VERSION ""

NS_ :

BS_:

BU_: Engine2 Aftertreatment_1_GasOutlet BrakesSystemController Transmission1 Engine1

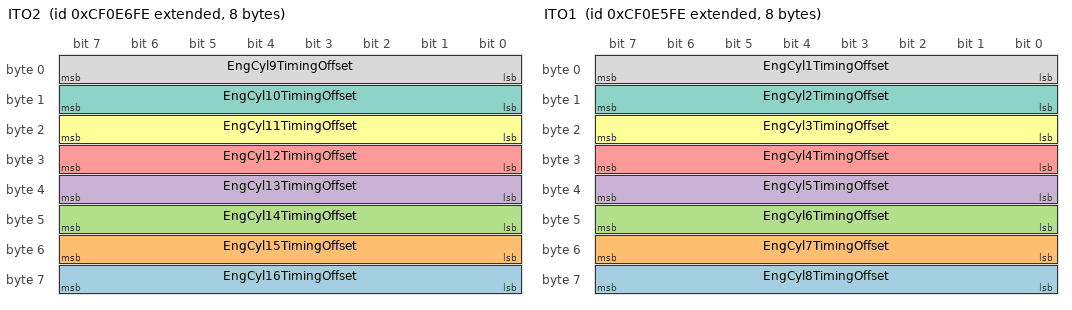
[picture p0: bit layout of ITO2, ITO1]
BO_ 2364598014 ITO2: 8 Vector__XXX
 SG_ EngCyl16TimingOffset : 56|8@1+ (0.1,-12.5) [-12.5|12.5] "deg" Vector__XXX
 SG_ EngCyl15TimingOffset : 48|8@1+ (0.1,-12.5) [-12.5|12.5] "deg" Vector__XXX
 SG_ EngCyl14TimingOffset : 40|8@1+ (0.1,-12.5) [-12.5|12.5] "deg" Vector__XXX
 SG_ EngCyl13TimingOffset : 32|8@1+ (0.1,-12.5) [-12.5|12.5] "deg" Vector__XXX
 SG_ EngCyl12TimingOffset : 24|8@1+ (0.1,-12.5) [-12.5|12.5] "deg" Vector__XXX
 SG_ EngCyl11TimingOffset : 16|8@1+ (0.1,-12.5) [-12.5|12.5] "deg" Vector__XXX
 SG_ EngCyl10TimingOffset : 8|8@1+ (0.1,-12.5) [-12.5|12.5] "deg" Vector__XXX
 SG_ EngCyl9TimingOffset : 0|8@1+ (0.1,-12.5) [-12.5|12.5] "deg" Vector__XXX

BO_ 2364597758 ITO1: 8 Vector__XXX
 SG_ EngCyl8TimingOffset : 56|8@1+ (0.1,-12.5) [-12.5|12.5] "deg" Vector__XXX
 SG_ EngCyl7TimingOffset : 48|8@1+ (0.1,-12.5) [-12.5|12.5] "deg" Vector__XXX
 SG_ EngCyl6TimingOffset : 40|8@1+ (0.1,-12.5) [-12.5|12.5] "deg" Vector__XXX
 SG_ EngCyl5TimingOffset : 32|8@1+ (0.1,-12.5) [-12.5|12.5] "deg" Vector__XXX
 SG_ EngCyl4TimingOffset : 24|8@1+ (0.1,-12.5) [-12.5|12.5] "deg" Vector__XXX
 SG_ EngCyl3TimingOffset : 16|8@1+ (0.1,-12.5) [-12.5|12.5] "deg" Vector__XXX
 SG_ EngCyl2TimingOffset : 8|8@1+ (0.1,-12.5) [-12.5|12.5] "deg" Vector__XXX
 SG_ EngCyl1TimingOffset : 0|8@1+ (0.1,-12.5) [-12.5|12.5] "deg" Vector__XXX

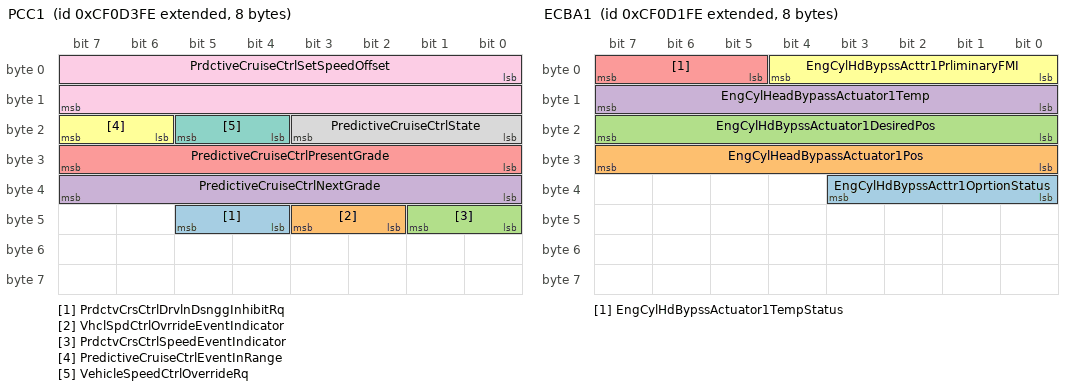
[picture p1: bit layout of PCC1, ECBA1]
BO_ 2364593150 PCC1: 8 Vector__XXX
 SG_ PrdctvCrsCtrlDrvlnDsnggInhibitRq : 44|2@1+ (1,0) [0|3] "" Vector__XXX
 SG_ VhclSpdCtrlOvrrideEventIndicator : 42|2@1+ (1,0) [0|3] "" Vector__XXX
 SG_ PrdctvCrsCtrlSpeedEventIndicator : 40|2@1+ (1,0) [0|3] "" Vector__XXX
 SG_ PredictiveCruiseCtrlNextGrade : 32|8@1+ (0.125,-16) [-16|15.25] "%" Vector__XXX
 SG_ PredictiveCruiseCtrlPresentGrade : 24|8@1+ (0.125,-16) [-16|15.25] "%" Vector__XXX
 SG_ PredictiveCruiseCtrlEventInRange : 22|2@1+ (1,0) [0|3] "" Vector__XXX
 SG_ VehicleSpeedCtrlOverrideRq : 20|2@1+ (1,0) [0|3] "" Vector__XXX
 SG_ PredictiveCruiseCtrlState : 16|4@1+ (1,0) [0|15] "" Vector__XXX
 SG_ PrdctiveCruiseCtrlSetSpeedOffset : 0|16@1+ (0.00390625,-125) [-125|125.996] "km/h" Vector__XXX

BO_ 2364592894 EEC18: 8 Vector__XXX
 SG_ EngCylHeadBypassActuator1Cmd : 0|16@1+ (0.0025,0) [0|160.6375] "%" Vector__XXX

BO_ 2364592638 ECBA1: 8 Vector__XXX
 SG_ EngCylHdBypssActtr1OprtionStatus : 32|4@1+ (1,0) [0|15] "" Vector__XXX
 SG_ EngCylHeadBypassActuator1Pos : 24|8@1+ (0.4,0) [0|100] "%" Vector__XXX
 SG_ EngCylHdBypssActuator1DesiredPos : 16|8@1+ (0.4,0) [0|100] "%" Vector__XXX
 SG_ EngCylHeadBypassActuator1Temp : 8|8@1+ (1,-40) [-40|210] "°C" Vector__XXX
 SG_ EngCylHdBypssActuator1TempStatus : 5|3@1+ (1,0) [0|7] "" Vector__XXX
 SG_ EngCylHdBypssActtr1PrliminaryFMI : 0|5@1+ (1,0) [0|31] "" Vector__XXX

BO_ 2364592382 ECCR: 8 Vector__XXX
 SG_ EngCyl24ExcludeFromCombustionRq : 54|2@1+ (1,0) [0|3] "" Vector__XXX
 SG_ EngCyl23ExcludeFromCombustionRq : 52|2@1+ (1,0) [0|3] "" Vector__XXX
 SG_ EngCyl22ExcludeFromCombustionRq : 50|2@1+ (1,0) [0|3] "" Vector__XXX
 SG_ EngCyl21ExcludeFromCombustionRq : 48|2@1+ (1,0) [0|3] "" Vector__XXX
 SG_ EngCyl20ExcludeFromCombustionRq : 46|2@1+ (1,0) [0|3] "" Vector__XXX
 SG_ EngCyl19ExcludeFromCombustionRq : 44|2@1+ (1,0) [0|3] "" Vector__XXX
 SG_ EngCyl18ExcludeFromCombustionRq : 42|2@1+ (1,0) [0|3] "" Vector__XXX
 SG_ EngCyl17ExcludeFromCombustionRq : 40|2@1+ (1,0) [0|3] "" Vector__XXX
 SG_ EngCyl16ExcludeFromCombustionRq : 38|2@1+ (1,0) [0|3] "" Vector__XXX
 SG_ EngCyl15ExcludeFromCombustionRq : 36|2@1+ (1,0) [0|3] "" Vector__XXX
 SG_ EngCyl14ExcludeFromCombustionRq : 34|2@1+ (1,0) [0|3] "" Vector__XXX
 SG_ EngCyl13ExcludeFromCombustionRq : 32|2@1+ (1,0) [0|3] "" Vector__XXX
 SG_ EngCyl12ExcludeFromCombustionRq : 30|2@1+ (1,0) [0|3] "" Vector__XXX
 SG_ EngCyl11ExcludeFromCombustionRq : 28|2@1+ (1,0) [0|3] "" Vector__XXX
 SG_ EngCyl10ExcludeFromCombustionRq : 26|2@1+ (1,0) [0|3] "" Vector__XXX
 SG_ EngCyl9ExcludeFromCombustionRq : 24|2@1+ (1,0) [0|3] "" Vector__XXX
 SG_ EngCyl8ExcludeFromCombustionRq : 22|2@1+ (1,0) [0|3] "" Vector__XXX
 SG_ EngCyl7ExcludeFromCombustionRq : 20|2@1+ (1,0) [0|3] "" Vector__XXX
 SG_ EngCyl6ExcludeFromCombustionRq : 18|2@1+ (1,0) [0|3] "" Vector__XXX
 SG_ EngCyl5ExcludeFromCombustionRq : 16|2@1+ (1,0) [0|3] "" Vector__XXX
 SG_ EngCyl4ExcludeFromCombustionRq : 14|2@1+ (1,0) [0|3] "" Vector__XXX
 SG_ EngCyl3ExcludeFromCombustionRq : 12|2@1+ (1,0) [0|3] "" Vector__XXX
 SG_ EngCyl2ExcludeFromCombustionRq : 10|2@1+ (1,0) [0|3] "" Vector__XXX
 SG_ EngCyl1ExcludeFromCombustionRq : 8|2@1+ (1,0) [0|3] "" Vector__XXX
 SG_ NmbrOfEngCylndrsTExcldFrmCmbston : 0|8@1+ (1,0) [0|24] "" Vector__XXX

BO_ 2364567294 FPAC: 8 Vector__XXX
 SG_ EngFlInjctnPump2FuelCtrlValveCmd : 16|16@1+ (0.0025,0) [0|100] "%" Vector__XXX
 SG_ EngFlInjctnPump1FuelCtrlValveCmd : 0|16@1+ (0.0025,0) [0|100] "%" Vector__XXX

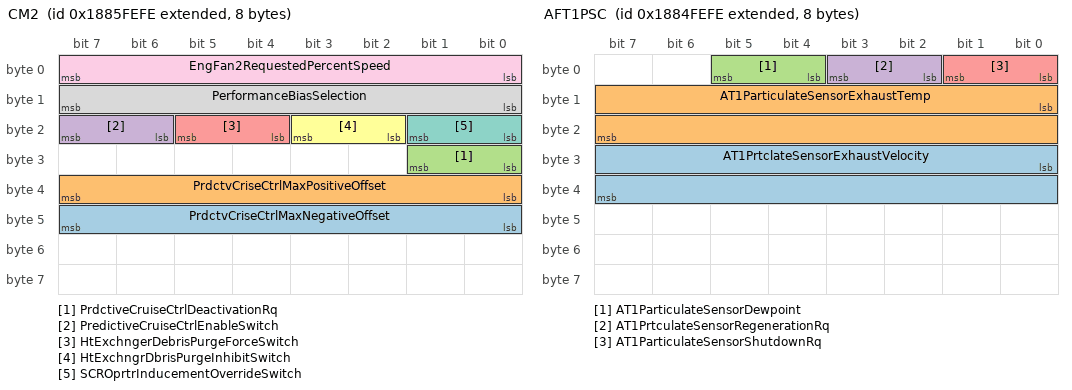
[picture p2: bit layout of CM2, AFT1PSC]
BO_ 2558918398 CM2: 8 Vector__XXX
 SG_ PrdctvCriseCtrlMaxNegativeOffset : 40|8@1+ (0.125,-31.25) [-31.25|0] "km/h" Vector__XXX
 SG_ PrdctvCriseCtrlMaxPositiveOffset : 32|8@1+ (0.125,0) [0|31.25] "km/h" Vector__XXX
 SG_ PrdctiveCruiseCtrlDeactivationRq : 24|2@1+ (1,0) [0|3] "" Vector__XXX
 SG_ PredictiveCruiseCtrlEnableSwitch : 22|2@1+ (1,0) [0|3] "" Vector__XXX
 SG_ HtExchngerDebrisPurgeForceSwitch : 20|2@1+ (1,0) [0|3] "" Vector__XXX
 SG_ HtExchngrDbrisPurgeInhibitSwitch : 18|2@1+ (1,0) [0|3] "" Vector__XXX
 SG_ SCROprtrInducementOverrideSwitch : 16|2@1+ (1,0) [0|3] "" Vector__XXX
 SG_ PerformanceBiasSelection : 8|8@1+ (0.4,0) [0|100] "%" Vector__XXX
 SG_ EngFan2RequestedPercentSpeed : 0|8@1+ (0.4,0) [0|100] "%" Vector__XXX

BO_ 2558852862 AFT1PSC: 8 Vector__XXX
 SG_ AT1PrtclateSensorExhaustVelocity : 24|16@1+ (0.00390625,0) [0|250.996] "km/h" Vector__XXX
 SG_ AT1ParticulateSensorExhaustTemp : 8|16@1+ (0.03125,-273) [-273|1734.96875] "°C" Vector__XXX
 SG_ AT1ParticulateSensorDewpoint : 4|2@1+ (1,0) [0|3] "" Vector__XXX
 SG_ AT1PrtculateSensorRegenerationRq : 2|2@1+ (1,0) [0|3] "" Vector__XXX
 SG_ AT1ParticulateSensorShutdownRq : 0|2@1+ (1,0) [0|3] "" Vector__XXX

BO_ 2558787326 PCIC: 8 Vector__XXX
 SG_ PayloadCorrectionFactorCmd : 24|8@1+ (1,-125) [-125|125] "%" Vector__XXX
 SG_ PayloadCalibCommandedWeight : 8|16@1+ (2,0) [0|128510] "kg" Vector__XXX
 SG_ PayloadCalibSetPointCmd : 0|4@1+ (1,0) [0|15] "" Vector__XXX

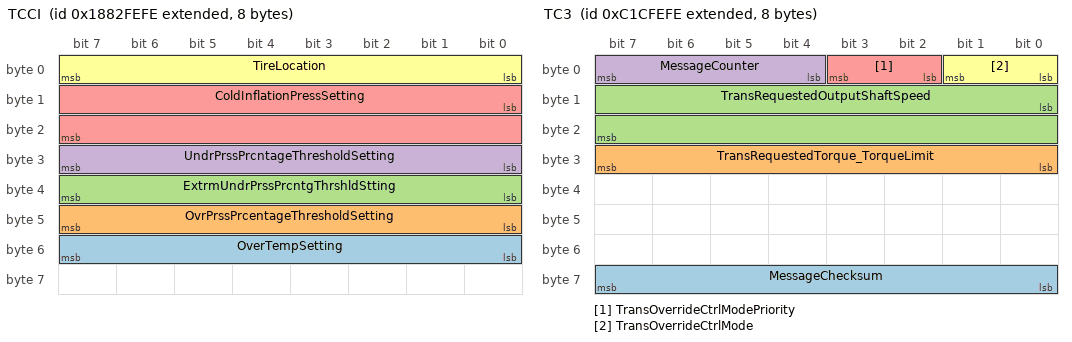
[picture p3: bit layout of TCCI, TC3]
BO_ 2558721790 TCCI: 8 Vector__XXX
 SG_ OverTempSetting : 48|8@1+ (1,-40) [-40|210] "°C" Vector__XXX
 SG_ OvrPrssPrcentageThresholdSetting : 40|8@1+ (0.5,0) [0|125] "%" Vector__XXX
 SG_ ExtrmUndrPrssPrcntgThrshldStting : 32|8@1+ (0.5,0) [0|125] "%" Vector__XXX
 SG_ UndrPrssPrcntageThresholdSetting : 24|8@1+ (0.5,0) [0|125] "%" Vector__XXX
 SG_ ColdInflationPressSetting : 8|16@1+ (1,0) [0|64255] "kPa" Vector__XXX
 SG_ TireLocation : 0|8@1+ (1,0) [0|0] "" Vector__XXX

BO_ 2558656254 AFTSC: 8 Vector__XXX
 SG_ RqToPermitDEFDosingTestInjection : 4|3@1+ (1,0) [0|7] "" Vector__XXX
 SG_ RqToPermitDEFHydStiffnessCheck : 2|2@1+ (1,0) [0|3] "" Vector__XXX
 SG_ ATThermalManagementInhibitRq : 0|2@1+ (1,0) [0|3] "" Vector__XXX

BO_ 2558590718 HSC1: 8 Vector__XXX
 SG_ HybrdSystmRgnrtvBrakingDisableRq : 4|2@1+ (1,0) [0|3] "" Vector__XXX
 SG_ HybridSystemProtectionOverrideRq : 0|2@1+ (1,0) [0|3] "" Vector__XXX

BO_ 2350776062 EIC: 8 Vector__XXX
 SG_ EngTimingAdvance : 0|16@1+ (0.0078125,-200) [-200|301.99] "deg" Vector__XXX

BO_ 2350710526 TC3: 8 Vector__XXX
 SG_ MessageChecksum : 56|8@1+ (1,0) [0|255] "" Vector__XXX
 SG_ TransRequestedTorque_TorqueLimit : 24|8@1+ (1,-125) [-125|125] "%" Vector__XXX
 SG_ TransRequestedOutputShaftSpeed : 8|16@1+ (0.25,-8031.75) [-8031.375|8031.375] "rpm" Vector__XXX
 SG_ MessageCounter : 4|4@1+ (1,0) [0|15] "" Vector__XXX
 SG_ TransOverrideCtrlModePriority : 2|2@1+ (1,0) [0|3] "" Vector__XXX
 SG_ TransOverrideCtrlMode : 0|2@1+ (1,0) [0|3] "" Vector__XXX

BO_ 2381315838 PropA2: 8 Vector__XXX
 SG_ ManufacturerSpecificInformation : 0|64@1+ (1,0) [0|0] "" Vector__XXX

BO_ 2365510142 DM09: 8 Vector__XXX

BO_ 2365475326 GBSD: 8 Vector__XXX
 SG_ GroundBasedDirection : 56|2@1+ (1,0) [0|0] "" Vector__XXX
 SG_ GroundBasedImplementDistance : 16|32@1+ (1,0) [0|0] "" Vector__XXX
 SG_ GroundBasedImplementSpeed : 0|16@1+ (1,0) [0|0] "" Vector__XXX

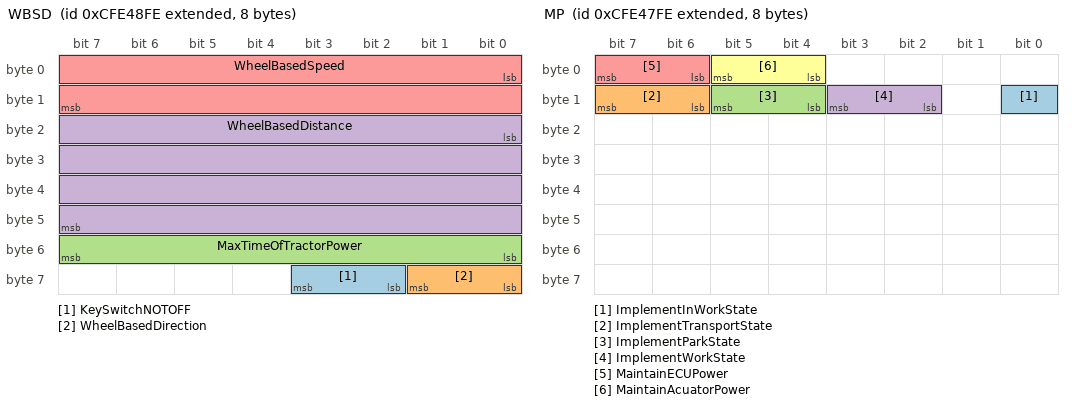
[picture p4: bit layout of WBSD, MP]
BO_ 2365475070 WBSD: 8 Vector__XXX
 SG_ KeySwitchNOTOFF : 58|2@1+ (1,0) [0|0] "" Vector__XXX
 SG_ WheelBasedDirection : 56|2@1+ (1,0) [0|0] "" Vector__XXX
 SG_ MaxTimeOfTractorPower : 48|8@1+ (1,0) [0|0] "" Vector__XXX
 SG_ WheelBasedDistance : 16|32@1+ (1,0) [0|0] "" Vector__XXX
 SG_ WheelBasedSpeed : 0|16@1+ (1,0) [0|0] "" Vector__XXX

BO_ 2365474814 MP: 8 Vector__XXX
 SG_ ImplementInWorkState : 8|1@1+ (1,0) [0|0] "" Vector__XXX
 SG_ ImplementTransportState : 14|2@1+ (1,0) [0|0] "" Vector__XXX
 SG_ ImplementParkState : 12|2@1+ (1,0) [0|0] "" Vector__XXX
 SG_ ImplementWorkState : 10|2@1+ (1,0) [0|0] "" Vector__XXX
 SG_ MaintainECUPower : 6|2@1+ (1,0) [0|0] "" Vector__XXX
 SG_ MaintainAcuatorPower : 4|2@1+ (1,0) [0|0] "" Vector__XXX

BO_ 2365474558 FHS: 8 Vector__XXX
 SG_ FrontDraft : 24|16@1+ (1,0) [0|0] "" Vector__XXX
 SG_ FrontNominalLowerLinkForce : 16|8@1+ (1,0) [0|0] "" Vector__XXX
 SG_ FrontHitchInworkIndication : 14|2@1+ (1,0) [0|0] "" Vector__XXX
 SG_ FrontHitchPos : 0|8@1+ (1,0) [0|0] "" Vector__XXX

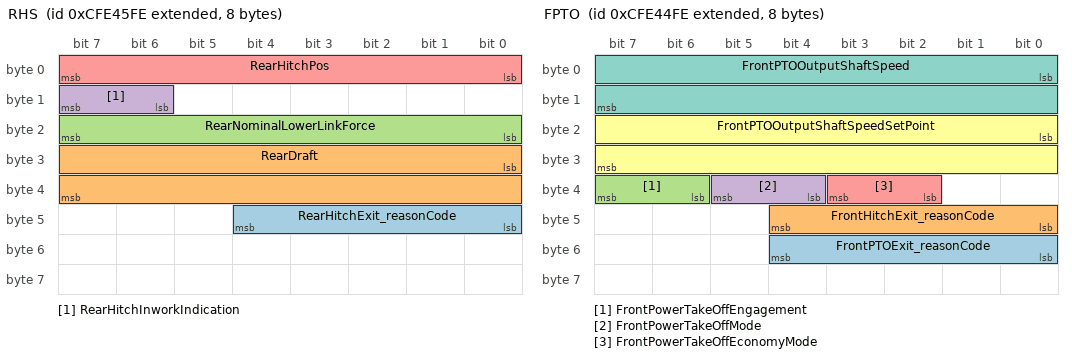
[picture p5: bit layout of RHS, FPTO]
BO_ 2365474302 RHS: 8 Vector__XXX
 SG_ RearHitchExit_reasonCode : 40|5@1+ (1,0) [0|0] "" Vector__XXX
 SG_ RearDraft : 24|16@1+ (1,0) [0|0] "" Vector__XXX
 SG_ RearNominalLowerLinkForce : 16|8@1+ (1,0) [0|0] "" Vector__XXX
 SG_ RearHitchInworkIndication : 14|2@1+ (1,0) [0|0] "" Vector__XXX
 SG_ RearHitchPos : 0|8@1+ (1,0) [0|0] "" Vector__XXX

BO_ 2365474046 FPTO: 8 Vector__XXX
 SG_ FrontPTOExit_reasonCode : 48|5@1+ (1,0) [0|0] "" Vector__XXX
 SG_ FrontHitchExit_reasonCode : 40|5@1+ (1,0) [0|0] "" Vector__XXX
 SG_ FrontPowerTakeOffEngagement : 38|2@1+ (1,0) [0|0] "" Vector__XXX
 SG_ FrontPowerTakeOffMode : 36|2@1+ (1,0) [0|0] "" Vector__XXX
 SG_ FrontPowerTakeOffEconomyMode : 34|2@1+ (1,0) [0|0] "" Vector__XXX
 SG_ FrontPTOOutputShaftSpeedSetPoint : 16|16@1+ (1,0) [0|0] "" Vector__XXX
 SG_ FrontPTOOutputShaftSpeed : 0|16@1+ (1,0) [0|0] "" Vector__XXX

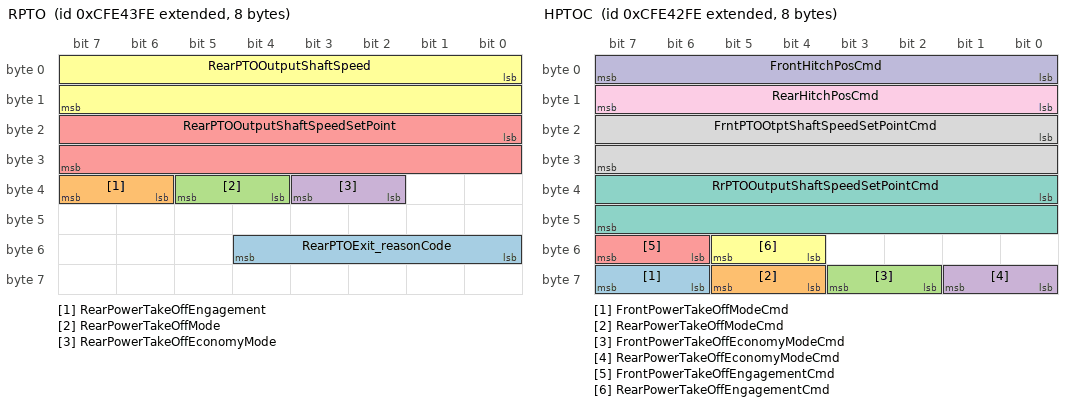
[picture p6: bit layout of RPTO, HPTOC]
BO_ 2365473790 RPTO: 8 Vector__XXX
 SG_ RearPTOExit_reasonCode : 48|5@1+ (1,0) [0|0] "" Vector__XXX
 SG_ RearPowerTakeOffEngagement : 38|2@1+ (1,0) [0|0] "" Vector__XXX
 SG_ RearPowerTakeOffMode : 36|2@1+ (1,0) [0|0] "" Vector__XXX
 SG_ RearPowerTakeOffEconomyMode : 34|2@1+ (1,0) [0|0] "" Vector__XXX
 SG_ RearPTOOutputShaftSpeedSetPoint : 16|16@1+ (1,0) [0|0] "" Vector__XXX
 SG_ RearPTOOutputShaftSpeed : 0|16@1+ (1,0) [0|0] "" Vector__XXX

BO_ 2365473534 HPTOC: 8 Vector__XXX
 SG_ FrontPowerTakeOffModeCmd : 62|2@1+ (1,0) [0|0] "" Vector__XXX
 SG_ RearPowerTakeOffModeCmd : 60|2@1+ (1,0) [0|0] "" Vector__XXX
 SG_ FrontPowerTakeOffEconomyModeCmd : 58|2@1+ (1,0) [0|0] "" Vector__XXX
 SG_ RearPowerTakeOffEconomyModeCmd : 56|2@1+ (1,0) [0|0] "" Vector__XXX
 SG_ FrontPowerTakeOffEngagementCmd : 54|2@1+ (1,0) [0|0] "" Vector__XXX
 SG_ RearPowerTakeOffEngagementCmd : 52|2@1+ (1,0) [0|0] "" Vector__XXX
 SG_ RrPTOOutputShaftSpeedSetPointCmd : 32|16@1+ (1,0) [0|0] "" Vector__XXX
 SG_ FrntPTOOtptShaftSpeedSetPointCmd : 16|16@1+ (1,0) [0|0] "" Vector__XXX
 SG_ RearHitchPosCmd : 8|8@1+ (1,0) [0|0] "" Vector__XXX
 SG_ FrontHitchPosCmd : 0|8@1+ (1,0) [0|0] "" Vector__XXX

BO_ 2365472766 AV15C: 8 Vector__XXX
 SG_ AuxValve15FailSafeModeCmd : 22|2@1+ (1,0) [0|0] "" Vector__XXX
 SG_ AuxValve15StateCmd : 16|4@1+ (1,0) [0|0] "" Vector__XXX
 SG_ AuxValve15PortFlowCmd : 0|8@1+ (1,0) [0|0] "" Vector__XXX

BO_ 2365472510 AV14C: 8 Vector__XXX
 SG_ AuxValve14FailSafeModeCmd : 22|2@1+ (1,0) [0|0] "" Vector__XXX
 SG_ AuxValve14StateCmd : 16|4@1+ (1,0) [0|0] "" Vector__XXX
 SG_ AuxValve14PortFlowCmd : 0|8@1+ (1,0) [0|0] "" Vector__XXX

BO_ 2365472254 AV13C: 8 Vector__XXX
 SG_ AuxValve13FailSafeModeCmd : 22|2@1+ (1,0) [0|0] "" Vector__XXX
 SG_ AuxValve13StateCmd : 16|4@1+ (1,0) [0|0] "" Vector__XXX
 SG_ AuxValve13PortFlowCmd : 0|8@1+ (1,0) [0|0] "" Vector__XXX

BO_ 2365471998 AV12C: 8 Vector__XXX
 SG_ AuxValve12FailSafeModeCmd : 22|2@1+ (1,0) [0|0] "" Vector__XXX
 SG_ AuxValve12StateCmd : 16|4@1+ (1,0) [0|0] "" Vector__XXX
 SG_ AuxValve12PortFlowCmd : 0|8@1+ (1,0) [0|0] "" Vector__XXX

BO_ 2365471742 AV11C: 8 Vector__XXX
 SG_ AuxValve11FailSafeModeCmd : 22|2@1+ (1,0) [0|0] "" Vector__XXX
 SG_ AuxValve11StateCmd : 16|4@1+ (1,0) [0|0] "" Vector__XXX
 SG_ AuxValve11PortFlowCmd : 0|8@1+ (1,0) [0|0] "" Vector__XXX

BO_ 2365471486 AV10C: 8 Vector__XXX
 SG_ AuxValve10FailSafeModeCmd : 22|2@1+ (1,0) [0|0] "" Vector__XXX
 SG_ AuxValve10StateCmd : 16|4@1+ (1,0) [0|0] "" Vector__XXX
 SG_ AuxValve10PortFlowCmd : 0|8@1+ (1,0) [0|0] "" Vector__XXX

BO_ 2365471230 AV09C: 8 Vector__XXX
 SG_ AuxValve9FailSafeModeCmd : 22|2@1+ (1,0) [0|0] "" Vector__XXX
 SG_ AuxValve9StateCmd : 16|4@1+ (1,0) [0|0] "" Vector__XXX
 SG_ AuxValve9PortFlowCmd : 0|8@1+ (1,0) [0|0] "" Vector__XXX

BO_ 2365470974 AV08C: 8 Vector__XXX
 SG_ AuxValve8FailSafeModeCmd : 22|2@1+ (1,0) [0|0] "" Vector__XXX
 SG_ AuxValve8StateCmd : 16|4@1+ (1,0) [0|0] "" Vector__XXX
 SG_ AuxValve8PortFlowCmd : 0|8@1+ (1,0) [0|0] "" Vector__XXX

BO_ 2365470718 AV07C: 8 Vector__XXX
 SG_ AuxValve7FailSafeModeCmd : 22|2@1+ (1,0) [0|0] "" Vector__XXX
 SG_ AuxValve7StateCmd : 16|4@1+ (1,0) [0|0] "" Vector__XXX
 SG_ AuxValve7PortFlowCmd : 0|8@1+ (1,0) [0|0] "" Vector__XXX

BO_ 2365470462 AV06C: 8 Vector__XXX
 SG_ AuxValve6FailSafeModeCmd : 22|2@1+ (1,0) [0|0] "" Vector__XXX
 SG_ AuxValve6StateCmd : 16|4@1+ (1,0) [0|0] "" Vector__XXX
 SG_ AuxValve6PortFlowCmd : 0|8@1+ (1,0) [0|0] "" Vector__XXX

BO_ 2365470206 AV05C: 8 Vector__XXX
 SG_ AuxValve5FailSafeModeCmd : 22|2@1+ (1,0) [0|0] "" Vector__XXX
 SG_ AuxValve5StateCmd : 16|4@1+ (1,0) [0|0] "" Vector__XXX
 SG_ AuxValve5PortFlowCmd : 0|8@1+ (1,0) [0|0] "" Vector__XXX

BO_ 2365469950 AV04C: 8 Vector__XXX
 SG_ AuxValve4FailSafeModeCmd : 22|2@1+ (1,0) [0|0] "" Vector__XXX
 SG_ AuxValve4StateCmd : 16|4@1+ (1,0) [0|0] "" Vector__XXX
 SG_ AuxValve4PortFlowCmd : 0|8@1+ (1,0) [0|0] "" Vector__XXX

BO_ 2365469694 AV03C: 8 Vector__XXX
 SG_ AuxValve3FailSafeModeCmd : 22|2@1+ (1,0) [0|0] "" Vector__XXX
 SG_ AuxValve3StateCmd : 16|4@1+ (1,0) [0|0] "" Vector__XXX
 SG_ AuxValve3PortFlowCmd : 0|8@1+ (1,0) [0|0] "" Vector__XXX

BO_ 2365469438 AV02C: 8 Vector__XXX
 SG_ AuxValve2FailSafeModeCmd : 22|2@1+ (1,0) [0|0] "" Vector__XXX
 SG_ AuxValve2StateCmd : 16|4@1+ (1,0) [0|0] "" Vector__XXX
 SG_ AuxValve2PortFlowCmd : 0|8@1+ (1,0) [0|0] "" Vector__XXX

BO_ 2365469182 AV01C: 8 Vector__XXX
 SG_ AuxValve1FailSafeModeCmd : 22|2@1+ (1,0) [0|0] "" Vector__XXX
 SG_ AuxValve1StateCmd : 16|4@1+ (1,0) [0|0] "" Vector__XXX
 SG_ AuxValve1PortFlowCmd : 0|8@1+ (1,0) [0|0] "" Vector__XXX

BO_ 2365468926 AV00C: 8 Vector__XXX
 SG_ AuxValve0FailSafeModeCmd : 22|2@1+ (1,0) [0|0] "" Vector__XXX
 SG_ AuxValve0StateCmd : 16|4@1+ (1,0) [0|0] "" Vector__XXX
 SG_ AuxValve0PortFlowCmd : 0|8@1+ (1,0) [0|0] "" Vector__XXX

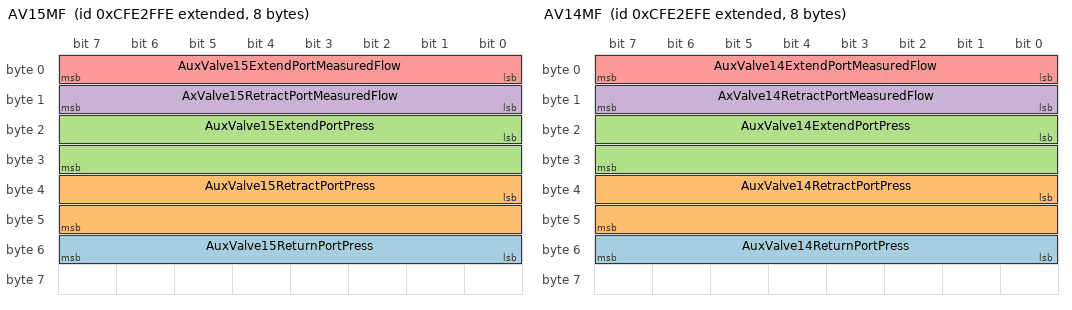
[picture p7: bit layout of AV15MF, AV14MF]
BO_ 2365468670 AV15MF: 8 Vector__XXX
 SG_ AuxValve15ReturnPortPress : 48|8@1+ (1,0) [0|0] "" Vector__XXX
 SG_ AuxValve15RetractPortPress : 32|16@1+ (1,0) [0|0] "" Vector__XXX
 SG_ AuxValve15ExtendPortPress : 16|16@1+ (1,0) [0|0] "" Vector__XXX
 SG_ AxValve15RetractPortMeasuredFlow : 8|8@1+ (1,0) [0|0] "" Vector__XXX
 SG_ AuxValve15ExtendPortMeasuredFlow : 0|8@1+ (1,0) [0|0] "" Vector__XXX

BO_ 2365468414 AV14MF: 8 Vector__XXX
 SG_ AuxValve14ReturnPortPress : 48|8@1+ (1,0) [0|0] "" Vector__XXX
 SG_ AuxValve14RetractPortPress : 32|16@1+ (1,0) [0|0] "" Vector__XXX
 SG_ AuxValve14ExtendPortPress : 16|16@1+ (1,0) [0|0] "" Vector__XXX
 SG_ AxValve14RetractPortMeasuredFlow : 8|8@1+ (1,0) [0|0] "" Vector__XXX
 SG_ AuxValve14ExtendPortMeasuredFlow : 0|8@1+ (1,0) [0|0] "" Vector__XXX

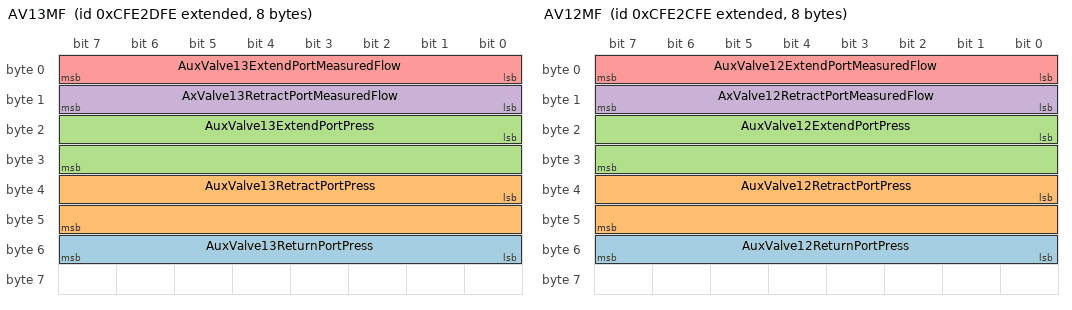
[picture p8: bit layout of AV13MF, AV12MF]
BO_ 2365468158 AV13MF: 8 Vector__XXX
 SG_ AuxValve13ReturnPortPress : 48|8@1+ (1,0) [0|0] "" Vector__XXX
 SG_ AuxValve13RetractPortPress : 32|16@1+ (1,0) [0|0] "" Vector__XXX
 SG_ AuxValve13ExtendPortPress : 16|16@1+ (1,0) [0|0] "" Vector__XXX
 SG_ AxValve13RetractPortMeasuredFlow : 8|8@1+ (1,0) [0|0] "" Vector__XXX
 SG_ AuxValve13ExtendPortMeasuredFlow : 0|8@1+ (1,0) [0|0] "" Vector__XXX

BO_ 2365467902 AV12MF: 8 Vector__XXX
 SG_ AuxValve12ReturnPortPress : 48|8@1+ (1,0) [0|0] "" Vector__XXX
 SG_ AuxValve12RetractPortPress : 32|16@1+ (1,0) [0|0] "" Vector__XXX
 SG_ AuxValve12ExtendPortPress : 16|16@1+ (1,0) [0|0] "" Vector__XXX
 SG_ AxValve12RetractPortMeasuredFlow : 8|8@1+ (1,0) [0|0] "" Vector__XXX
 SG_ AuxValve12ExtendPortMeasuredFlow : 0|8@1+ (1,0) [0|0] "" Vector__XXX

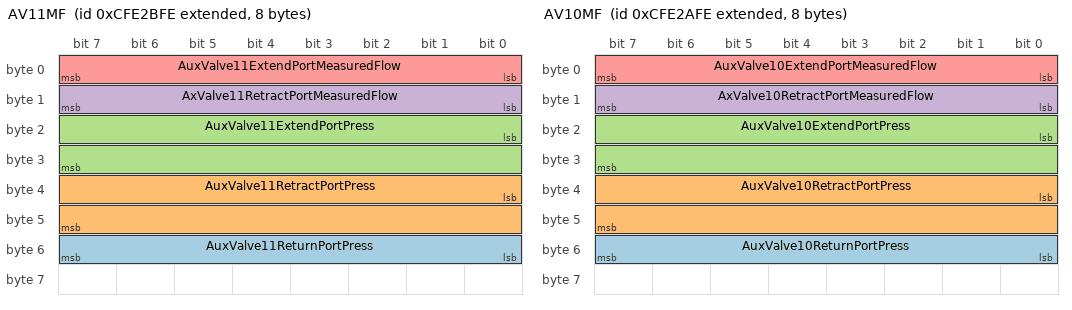
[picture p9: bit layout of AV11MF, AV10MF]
BO_ 2365467646 AV11MF: 8 Vector__XXX
 SG_ AuxValve11ReturnPortPress : 48|8@1+ (1,0) [0|0] "" Vector__XXX
 SG_ AuxValve11RetractPortPress : 32|16@1+ (1,0) [0|0] "" Vector__XXX
 SG_ AuxValve11ExtendPortPress : 16|16@1+ (1,0) [0|0] "" Vector__XXX
 SG_ AxValve11RetractPortMeasuredFlow : 8|8@1+ (1,0) [0|0] "" Vector__XXX
 SG_ AuxValve11ExtendPortMeasuredFlow : 0|8@1+ (1,0) [0|0] "" Vector__XXX

BO_ 2365467390 AV10MF: 8 Vector__XXX
 SG_ AuxValve10ReturnPortPress : 48|8@1+ (1,0) [0|0] "" Vector__XXX
 SG_ AuxValve10RetractPortPress : 32|16@1+ (1,0) [0|0] "" Vector__XXX
 SG_ AuxValve10ExtendPortPress : 16|16@1+ (1,0) [0|0] "" Vector__XXX
 SG_ AxValve10RetractPortMeasuredFlow : 8|8@1+ (1,0) [0|0] "" Vector__XXX
 SG_ AuxValve10ExtendPortMeasuredFlow : 0|8@1+ (1,0) [0|0] "" Vector__XXX

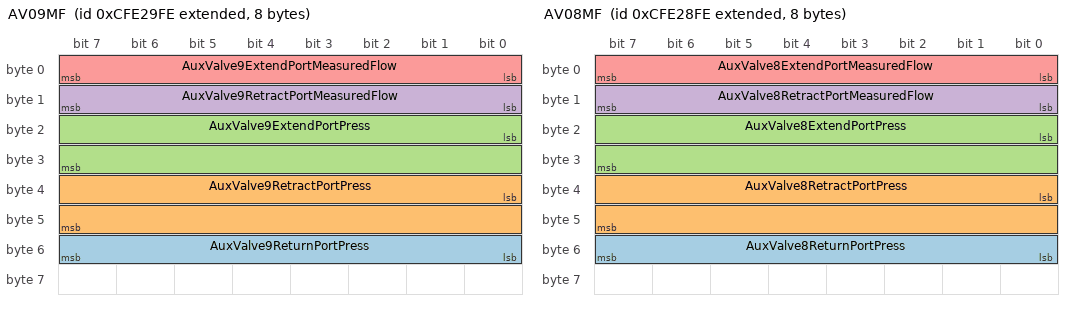
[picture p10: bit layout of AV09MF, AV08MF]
BO_ 2365467134 AV09MF: 8 Vector__XXX
 SG_ AuxValve9ReturnPortPress : 48|8@1+ (1,0) [0|0] "" Vector__XXX
 SG_ AuxValve9RetractPortPress : 32|16@1+ (1,0) [0|0] "" Vector__XXX
 SG_ AuxValve9ExtendPortPress : 16|16@1+ (1,0) [0|0] "" Vector__XXX
 SG_ AuxValve9RetractPortMeasuredFlow : 8|8@1+ (1,0) [0|0] "" Vector__XXX
 SG_ AuxValve9ExtendPortMeasuredFlow : 0|8@1+ (1,0) [0|0] "" Vector__XXX

BO_ 2365466878 AV08MF: 8 Vector__XXX
 SG_ AuxValve8ReturnPortPress : 48|8@1+ (1,0) [0|0] "" Vector__XXX
 SG_ AuxValve8RetractPortPress : 32|16@1+ (1,0) [0|0] "" Vector__XXX
 SG_ AuxValve8ExtendPortPress : 16|16@1+ (1,0) [0|0] "" Vector__XXX
 SG_ AuxValve8RetractPortMeasuredFlow : 8|8@1+ (1,0) [0|0] "" Vector__XXX
 SG_ AuxValve8ExtendPortMeasuredFlow : 0|8@1+ (1,0) [0|0] "" Vector__XXX

BO_ 2365466622 AV07MF: 8 Vector__XXX
 SG_ AuxValve7ReturnPortPress : 48|8@1+ (1,0) [0|0] "" Vector__XXX
 SG_ AuxValve7RetractPortPress : 32|16@1+ (1,0) [0|0] "" Vector__XXX
 SG_ AuxValve7ExtendPortPress : 16|16@1+ (1,0) [0|0] "" Vector__XXX
 SG_ AuxValve7RetractPortMeasuredFlow : 8|8@1+ (1,0) [0|0] "" Vector__XXX
 SG_ AuxValve7ExtendPortMeasuredFlow : 0|8@1+ (1,0) [0|0] "" Vector__XXX

BO_ 2365466366 AV06MF: 8 Vector__XXX
 SG_ AuxValve6ReturnPortPress : 48|8@1+ (1,0) [0|0] "" Vector__XXX
 SG_ AuxValve6RetractPortPress : 32|16@1+ (1,0) [0|0] "" Vector__XXX
 SG_ AuxValve6ExtendPortPress : 16|16@1+ (1,0) [0|0] "" Vector__XXX
 SG_ AuxValve6RetractPortMeasuredFlow : 8|8@1+ (1,0) [0|0] "" Vector__XXX
 SG_ AuxValve6ExtendPortMeasuredFlow : 0|8@1+ (1,0) [0|0] "" Vector__XXX

BO_ 2365466110 AV05MF: 8 Vector__XXX
 SG_ AuxValve5ReturnPortPress : 48|8@1+ (1,0) [0|0] "" Vector__XXX
 SG_ AuxValve5RetractPortPress : 32|16@1+ (1,0) [0|0] "" Vector__XXX
 SG_ AuxValve5ExtendPortPress : 16|16@1+ (1,0) [0|0] "" Vector__XXX
 SG_ AuxValve5RetractPortMeasuredFlow : 8|8@1+ (1,0) [0|0] "" Vector__XXX
 SG_ AuxValve5ExtendPortMeasuredFlow : 0|8@1+ (1,0) [0|0] "" Vector__XXX

BO_ 2365465854 AV04MF: 8 Vector__XXX
 SG_ AuxValve4ReturnPortPress : 48|8@1+ (1,0) [0|0] "" Vector__XXX
 SG_ AuxValve4RetractPortPress : 32|16@1+ (1,0) [0|0] "" Vector__XXX
 SG_ AuxValve4ExtendPortPress : 16|16@1+ (1,0) [0|0] "" Vector__XXX
 SG_ AuxValve4RetractPortMeasuredFlow : 8|8@1+ (1,0) [0|0] "" Vector__XXX
 SG_ AuxValve4ExtendPortMeasuredFlow : 0|8@1+ (1,0) [0|0] "" Vector__XXX

BO_ 2365465598 AV03MF: 8 Vector__XXX
 SG_ AuxValve3ReturnPortPress : 48|8@1+ (1,0) [0|0] "" Vector__XXX
 SG_ AuxValve3RetractPortPress : 32|16@1+ (1,0) [0|0] "" Vector__XXX
 SG_ AuxValve3ExtendPortPress : 16|16@1+ (1,0) [0|0] "" Vector__XXX
 SG_ AuxValve3RetractPortMeasuredFlow : 8|8@1+ (1,0) [0|0] "" Vector__XXX
 SG_ AuxValve3ExtendPortMeasuredFlow : 0|8@1+ (1,0) [0|0] "" Vector__XXX

BO_ 2365465342 AV02MF: 8 Vector__XXX
 SG_ AuxValve2ReturnPortPress : 48|8@1+ (1,0) [0|0] "" Vector__XXX
 SG_ AuxValve2RetractPortPress : 32|16@1+ (1,0) [0|0] "" Vector__XXX
 SG_ AuxValve2ExtendPortPress : 16|16@1+ (1,0) [0|0] "" Vector__XXX
 SG_ AuxValve2RetractPortMeasuredFlow : 8|8@1+ (1,0) [0|0] "" Vector__XXX
 SG_ AuxValve2ExtendPortMeasuredFlow : 0|8@1+ (1,0) [0|0] "" Vector__XXX

BO_ 2365465086 AV01MF: 8 Vector__XXX
 SG_ AuxValve1ReturnPortPress : 48|8@1+ (1,0) [0|0] "" Vector__XXX
 SG_ AuxValve1RetractPortPress : 32|16@1+ (1,0) [0|0] "" Vector__XXX
 SG_ AuxValve1ExtendPortPress : 16|16@1+ (1,0) [0|0] "" Vector__XXX
 SG_ AuxValve1RetractPortMeasuredFlow : 8|8@1+ (1,0) [0|0] "" Vector__XXX
 SG_ AuxValve1ExtendPortMeasuredFlow : 0|8@1+ (1,0) [0|0] "" Vector__XXX

BO_ 2365464830 AV00MF: 8 Vector__XXX
 SG_ AuxValve0ReturnPortPress : 48|8@1+ (1,0) [0|0] "" Vector__XXX
 SG_ AuxValve0RetractPortPress : 32|16@1+ (1,0) [0|0] "" Vector__XXX
 SG_ AuxValve0ExtendPortPress : 16|16@1+ (1,0) [0|0] "" Vector__XXX
 SG_ AuxValve0RetractPortMeasuredFlow : 8|8@1+ (1,0) [0|0] "" Vector__XXX
 SG_ AuxValve0ExtendPortMeasuredFlow : 0|8@1+ (1,0) [0|0] "" Vector__XXX

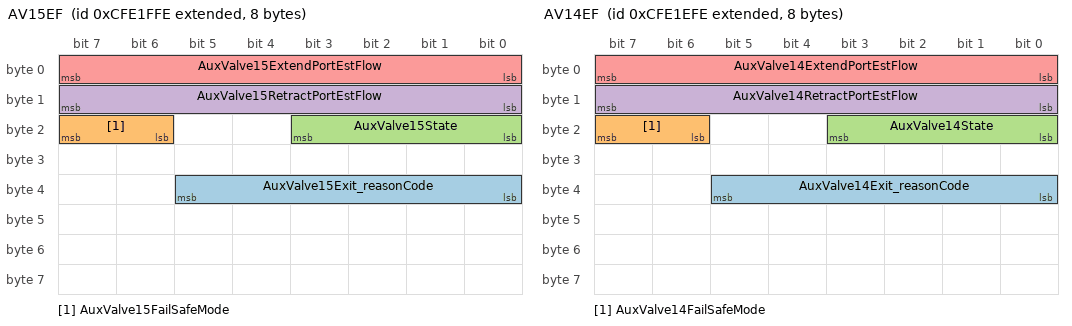
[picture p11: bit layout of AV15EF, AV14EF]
BO_ 2365464574 AV15EF: 8 Vector__XXX
 SG_ AuxValve15Exit_reasonCode : 32|6@1+ (1,0) [0|0] "" Vector__XXX
 SG_ AuxValve15FailSafeMode : 22|2@1+ (1,0) [0|0] "" Vector__XXX
 SG_ AuxValve15State : 16|4@1+ (1,0) [0|0] "" Vector__XXX
 SG_ AuxValve15RetractPortEstFlow : 8|8@1+ (1,0) [0|0] "" Vector__XXX
 SG_ AuxValve15ExtendPortEstFlow : 0|8@1+ (1,0) [0|0] "" Vector__XXX

BO_ 2365464318 AV14EF: 8 Vector__XXX
 SG_ AuxValve14Exit_reasonCode : 32|6@1+ (1,0) [0|0] "" Vector__XXX
 SG_ AuxValve14FailSafeMode : 22|2@1+ (1,0) [0|0] "" Vector__XXX
 SG_ AuxValve14State : 16|4@1+ (1,0) [0|0] "" Vector__XXX
 SG_ AuxValve14RetractPortEstFlow : 8|8@1+ (1,0) [0|0] "" Vector__XXX
 SG_ AuxValve14ExtendPortEstFlow : 0|8@1+ (1,0) [0|0] "" Vector__XXX

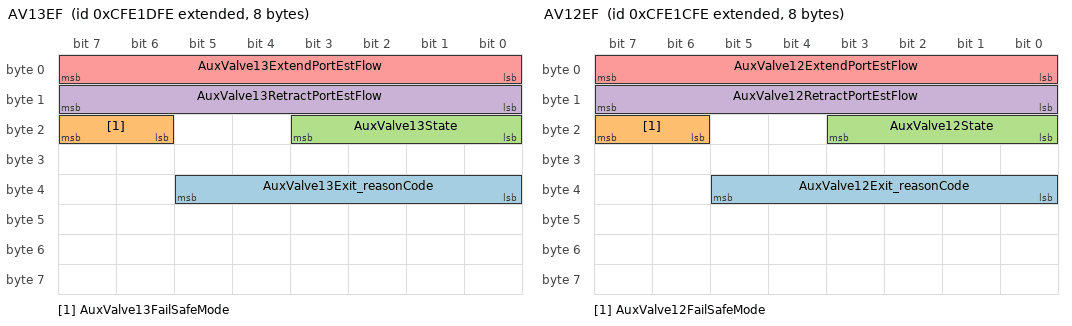
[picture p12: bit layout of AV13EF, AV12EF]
BO_ 2365464062 AV13EF: 8 Vector__XXX
 SG_ AuxValve13Exit_reasonCode : 32|6@1+ (1,0) [0|0] "" Vector__XXX
 SG_ AuxValve13FailSafeMode : 22|2@1+ (1,0) [0|0] "" Vector__XXX
 SG_ AuxValve13State : 16|4@1+ (1,0) [0|0] "" Vector__XXX
 SG_ AuxValve13RetractPortEstFlow : 8|8@1+ (1,0) [0|0] "" Vector__XXX
 SG_ AuxValve13ExtendPortEstFlow : 0|8@1+ (1,0) [0|0] "" Vector__XXX

BO_ 2365463806 AV12EF: 8 Vector__XXX
 SG_ AuxValve12Exit_reasonCode : 32|6@1+ (1,0) [0|0] "" Vector__XXX
 SG_ AuxValve12FailSafeMode : 22|2@1+ (1,0) [0|0] "" Vector__XXX
 SG_ AuxValve12State : 16|4@1+ (1,0) [0|0] "" Vector__XXX
 SG_ AuxValve12RetractPortEstFlow : 8|8@1+ (1,0) [0|0] "" Vector__XXX
 SG_ AuxValve12ExtendPortEstFlow : 0|8@1+ (1,0) [0|0] "" Vector__XXX

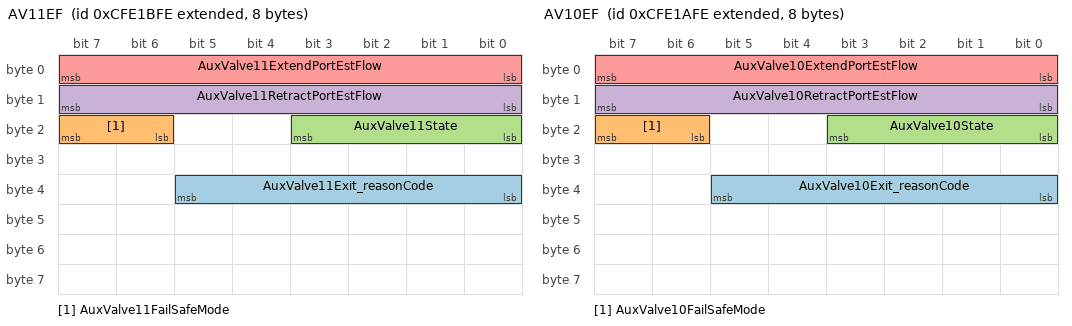
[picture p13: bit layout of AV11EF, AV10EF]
BO_ 2365463550 AV11EF: 8 Vector__XXX
 SG_ AuxValve11Exit_reasonCode : 32|6@1+ (1,0) [0|0] "" Vector__XXX
 SG_ AuxValve11FailSafeMode : 22|2@1+ (1,0) [0|0] "" Vector__XXX
 SG_ AuxValve11State : 16|4@1+ (1,0) [0|0] "" Vector__XXX
 SG_ AuxValve11RetractPortEstFlow : 8|8@1+ (1,0) [0|0] "" Vector__XXX
 SG_ AuxValve11ExtendPortEstFlow : 0|8@1+ (1,0) [0|0] "" Vector__XXX

BO_ 2365463294 AV10EF: 8 Vector__XXX
 SG_ AuxValve10Exit_reasonCode : 32|6@1+ (1,0) [0|0] "" Vector__XXX
 SG_ AuxValve10FailSafeMode : 22|2@1+ (1,0) [0|0] "" Vector__XXX
 SG_ AuxValve10State : 16|4@1+ (1,0) [0|0] "" Vector__XXX
 SG_ AuxValve10RetractPortEstFlow : 8|8@1+ (1,0) [0|0] "" Vector__XXX
 SG_ AuxValve10ExtendPortEstFlow : 0|8@1+ (1,0) [0|0] "" Vector__XXX

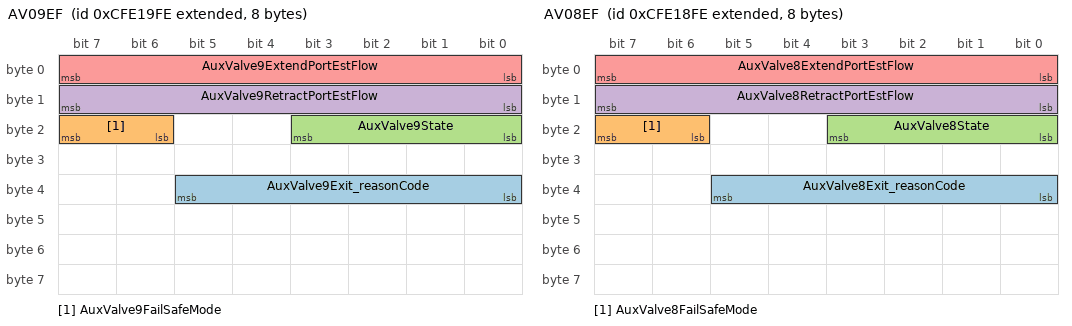
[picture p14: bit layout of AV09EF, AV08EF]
BO_ 2365463038 AV09EF: 8 Vector__XXX
 SG_ AuxValve9Exit_reasonCode : 32|6@1+ (1,0) [0|0] "" Vector__XXX
 SG_ AuxValve9FailSafeMode : 22|2@1+ (1,0) [0|0] "" Vector__XXX
 SG_ AuxValve9State : 16|4@1+ (1,0) [0|0] "" Vector__XXX
 SG_ AuxValve9RetractPortEstFlow : 8|8@1+ (1,0) [0|0] "" Vector__XXX
 SG_ AuxValve9ExtendPortEstFlow : 0|8@1+ (1,0) [0|0] "" Vector__XXX

BO_ 2365462782 AV08EF: 8 Vector__XXX
 SG_ AuxValve8Exit_reasonCode : 32|6@1+ (1,0) [0|0] "" Vector__XXX
 SG_ AuxValve8FailSafeMode : 22|2@1+ (1,0) [0|0] "" Vector__XXX
 SG_ AuxValve8State : 16|4@1+ (1,0) [0|0] "" Vector__XXX
 SG_ AuxValve8RetractPortEstFlow : 8|8@1+ (1,0) [0|0] "" Vector__XXX
 SG_ AuxValve8ExtendPortEstFlow : 0|8@1+ (1,0) [0|0] "" Vector__XXX

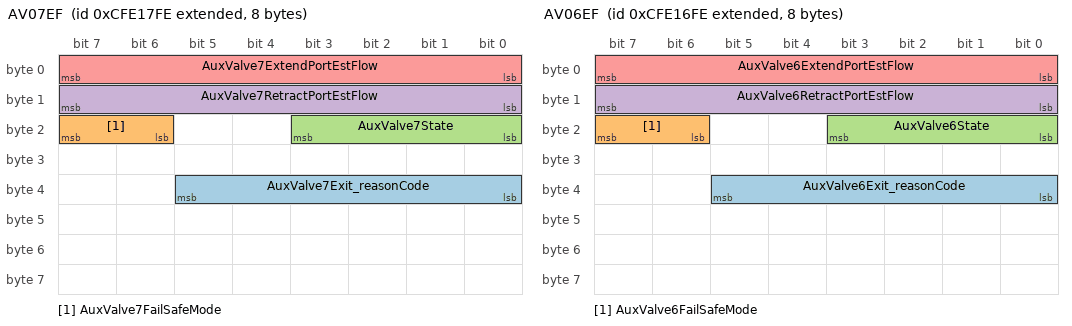
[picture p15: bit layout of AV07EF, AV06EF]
BO_ 2365462526 AV07EF: 8 Vector__XXX
 SG_ AuxValve7Exit_reasonCode : 32|6@1+ (1,0) [0|0] "" Vector__XXX
 SG_ AuxValve7FailSafeMode : 22|2@1+ (1,0) [0|0] "" Vector__XXX
 SG_ AuxValve7State : 16|4@1+ (1,0) [0|0] "" Vector__XXX
 SG_ AuxValve7RetractPortEstFlow : 8|8@1+ (1,0) [0|0] "" Vector__XXX
 SG_ AuxValve7ExtendPortEstFlow : 0|8@1+ (1,0) [0|0] "" Vector__XXX

BO_ 2365462270 AV06EF: 8 Vector__XXX
 SG_ AuxValve6Exit_reasonCode : 32|6@1+ (1,0) [0|0] "" Vector__XXX
 SG_ AuxValve6FailSafeMode : 22|2@1+ (1,0) [0|0] "" Vector__XXX
 SG_ AuxValve6State : 16|4@1+ (1,0) [0|0] "" Vector__XXX
 SG_ AuxValve6RetractPortEstFlow : 8|8@1+ (1,0) [0|0] "" Vector__XXX
 SG_ AuxValve6ExtendPortEstFlow : 0|8@1+ (1,0) [0|0] "" Vector__XXX

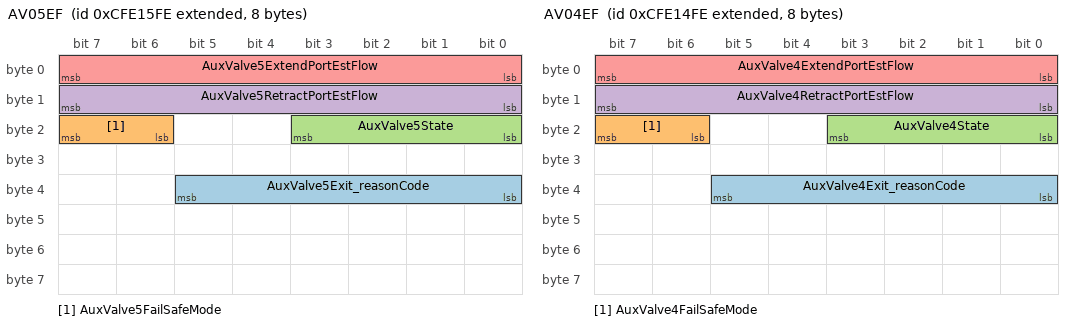
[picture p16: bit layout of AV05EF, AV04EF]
BO_ 2365462014 AV05EF: 8 Vector__XXX
 SG_ AuxValve5Exit_reasonCode : 32|6@1+ (1,0) [0|0] "" Vector__XXX
 SG_ AuxValve5FailSafeMode : 22|2@1+ (1,0) [0|0] "" Vector__XXX
 SG_ AuxValve5State : 16|4@1+ (1,0) [0|0] "" Vector__XXX
 SG_ AuxValve5RetractPortEstFlow : 8|8@1+ (1,0) [0|0] "" Vector__XXX
 SG_ AuxValve5ExtendPortEstFlow : 0|8@1+ (1,0) [0|0] "" Vector__XXX

BO_ 2365461758 AV04EF: 8 Vector__XXX
 SG_ AuxValve4Exit_reasonCode : 32|6@1+ (1,0) [0|0] "" Vector__XXX
 SG_ AuxValve4FailSafeMode : 22|2@1+ (1,0) [0|0] "" Vector__XXX
 SG_ AuxValve4State : 16|4@1+ (1,0) [0|0] "" Vector__XXX
 SG_ AuxValve4RetractPortEstFlow : 8|8@1+ (1,0) [0|0] "" Vector__XXX
 SG_ AuxValve4ExtendPortEstFlow : 0|8@1+ (1,0) [0|0] "" Vector__XXX

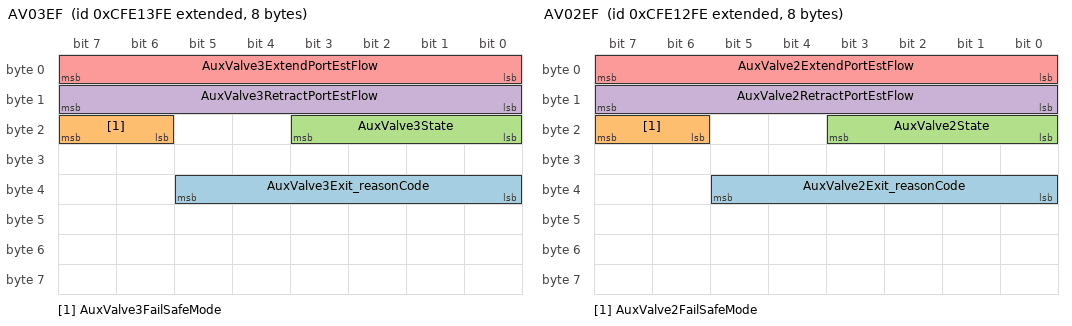
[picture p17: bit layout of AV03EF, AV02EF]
BO_ 2365461502 AV03EF: 8 Vector__XXX
 SG_ AuxValve3Exit_reasonCode : 32|6@1+ (1,0) [0|0] "" Vector__XXX
 SG_ AuxValve3FailSafeMode : 22|2@1+ (1,0) [0|0] "" Vector__XXX
 SG_ AuxValve3State : 16|4@1+ (1,0) [0|0] "" Vector__XXX
 SG_ AuxValve3RetractPortEstFlow : 8|8@1+ (1,0) [0|0] "" Vector__XXX
 SG_ AuxValve3ExtendPortEstFlow : 0|8@1+ (1,0) [0|0] "" Vector__XXX

BO_ 2365461246 AV02EF: 8 Vector__XXX
 SG_ AuxValve2Exit_reasonCode : 32|6@1+ (1,0) [0|0] "" Vector__XXX
 SG_ AuxValve2FailSafeMode : 22|2@1+ (1,0) [0|0] "" Vector__XXX
 SG_ AuxValve2State : 16|4@1+ (1,0) [0|0] "" Vector__XXX
 SG_ AuxValve2RetractPortEstFlow : 8|8@1+ (1,0) [0|0] "" Vector__XXX
 SG_ AuxValve2ExtendPortEstFlow : 0|8@1+ (1,0) [0|0] "" Vector__XXX

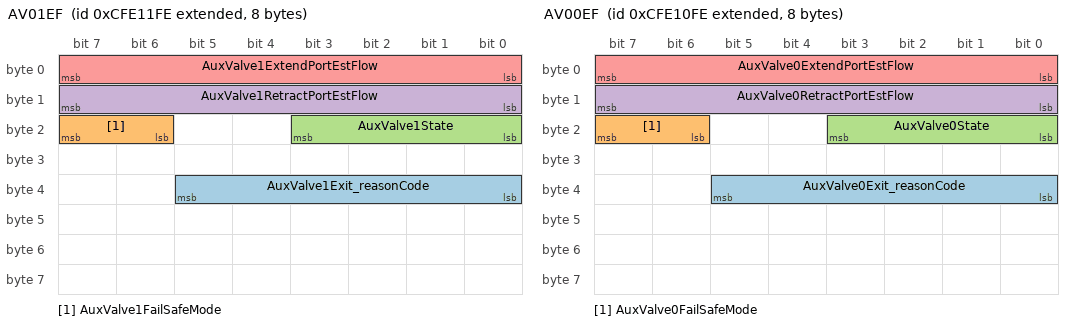
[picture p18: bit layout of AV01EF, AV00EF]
BO_ 2365460990 AV01EF: 8 Vector__XXX
 SG_ AuxValve1Exit_reasonCode : 32|6@1+ (1,0) [0|0] "" Vector__XXX
 SG_ AuxValve1FailSafeMode : 22|2@1+ (1,0) [0|0] "" Vector__XXX
 SG_ AuxValve1State : 16|4@1+ (1,0) [0|0] "" Vector__XXX
 SG_ AuxValve1RetractPortEstFlow : 8|8@1+ (1,0) [0|0] "" Vector__XXX
 SG_ AuxValve1ExtendPortEstFlow : 0|8@1+ (1,0) [0|0] "" Vector__XXX

BO_ 2365460734 AV00EF: 8 Vector__XXX
 SG_ AuxValve0Exit_reasonCode : 32|6@1+ (1,0) [0|0] "" Vector__XXX
 SG_ AuxValve0FailSafeMode : 22|2@1+ (1,0) [0|0] "" Vector__XXX
 SG_ AuxValve0State : 16|4@1+ (1,0) [0|0] "" Vector__XXX
 SG_ AuxValve0RetractPortEstFlow : 8|8@1+ (1,0) [0|0] "" Vector__XXX
 SG_ AuxValve0ExtendPortEstFlow : 0|8@1+ (1,0) [0|0] "" Vector__XXX

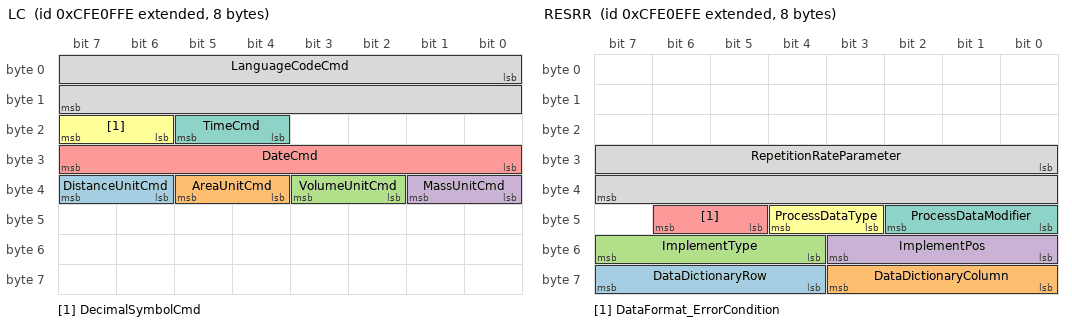
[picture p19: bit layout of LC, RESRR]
BO_ 2365460478 LC: 8 Vector__XXX
 SG_ DistanceUnitCmd : 38|2@1+ (1,0) [0|0] "" Vector__XXX
 SG_ AreaUnitCmd : 36|2@1+ (1,0) [0|0] "" Vector__XXX
 SG_ VolumeUnitCmd : 34|2@1+ (1,0) [0|0] "" Vector__XXX
 SG_ MassUnitCmd : 32|2@1+ (1,0) [0|0] "" Vector__XXX
 SG_ DateCmd : 24|8@1+ (1,0) [0|0] "" Vector__XXX
 SG_ DecimalSymbolCmd : 22|2@1+ (1,0) [0|0] "" Vector__XXX
 SG_ TimeCmd : 20|2@1+ (1,0) [0|0] "" Vector__XXX
 SG_ LanguageCodeCmd : 0|16@1+ (1,0) [0|0] "" Vector__XXX

BO_ 2365460222 RESRR: 8 Vector__XXX
 SG_ DataDictionaryRow : 60|4@1+ (1,0) [0|0] "" Vector__XXX
 SG_ DataDictionaryColumn : 56|4@1+ (1,0) [0|0] "" Vector__XXX
 SG_ ImplementType : 52|4@1+ (1,0) [0|0] "" Vector__XXX
 SG_ ImplementPos : 48|4@1+ (1,0) [0|0] "" Vector__XXX
 SG_ DataFormat_ErrorCondition : 45|2@1+ (1,0) [0|0] "" Vector__XXX
 SG_ ProcessDataType : 43|2@1+ (1,0) [0|0] "" Vector__XXX
 SG_ ProcessDataModifier : 40|3@1+ (1,0) [0|0] "" Vector__XXX
 SG_ RepetitionRateParameter : 24|16@1+ (1,0) [0|0] "" Vector__XXX

BO_ 2365459454 IRC: 8 Vector__XXX

BO_ 2365459198 IRCR: 8 Vector__XXX

BO_ 2365458942 TFR: 8 Vector__XXX
 SG_ TrctrFcltyRspLmt_RqstSttsRprting : 27|1@1+ (1,0) [0|0] "" Vector__XXX

BO_ 2365458686 RTF: 8 Vector__XXX
 SG_ TrctrFcltyRqLmt_RqstSttsRporting : 27|1@1+ (1,0) [0|0] "" Vector__XXX

BO_ 2365447934 MAM21: 8 Vector__XXX

BO_ 2365447678 MAM11: 8 Vector__XXX

BO_ 2365444094 WSM: 8 Vector__XXX
 SG_ NumberOfMembers : 0|8@1+ (1,0) [0|0] "" Vector__XXX

BO_ 2365443838 WSMM: 8 Vector__XXX
 SG_ NAMEOfWorkingSetMember : 0|64@1+ (1,0) [0|0] "" Vector__XXX

BO_ 2365434878 RCMS: 8 Vector__XXX
 SG_ PGNOfConfigurableMessageDesired : 8|24@1+ (1,0) [0|16777215] "" Vector__XXX
 SG_ MessageSelectionCtrl : 0|8@1+ (1,0) [0|250] "" Vector__XXX

BO_ 2566754814 ACS: 8 Vector__XXX
 SG_ AutomaticTransferSwitchStatus : 8|3@1+ (1,0) [0|7] "" Vector__XXX
 SG_ UtilityCircuitBreakerStatus : 3|3@1+ (1,0) [0|7] "" Vector__XXX
 SG_ GeneratorCircuitBreakerStatus : 0|3@1+ (1,0) [0|7] "" Vector__XXX

BO_ 2566754302 GTACPP: 8 Vector__XXX
 SG_ GeneratorTotalPercentKVAr : 32|16@1+ (0.0078125,-251) [-251|250.99] "%" Vector__XXX
 SG_ GeneratorTotalPercentKVA : 16|16@1+ (0.0078125,-251) [-251|250.99] "%" Vector__XXX
 SG_ GeneratorTotalPercentKW : 0|16@1+ (0.0078125,-251) [-251|250.99] "%" Vector__XXX

BO_ 2566754046 GTACER: 8 Vector__XXX
 SG_ GeneratorTotalKVArHoursImport : 32|32@1+ (1,0) [0|4211081215] "kVArh" Vector__XXX
 SG_ GeneratorTotalKVArHoursExport : 0|32@1+ (1,0) [0|4211081215] "kVArh" Vector__XXX

BO_ 2566753790 UTACER: 8 Vector__XXX
 SG_ UtilityTotalKVArHoursImport : 32|32@1+ (1,0) [0|4211081215] "kVArh" Vector__XXX
 SG_ UtilityTotalKVArHoursExport : 0|32@1+ (1,0) [0|4211081215] "kVArh" Vector__XXX

BO_ 2365411582 GPM19: 8 Vector__XXX

BO_ 2365411326 GPM26: 8 Vector__XXX

BO_ 2365411070 GPM27: 8 Vector__XXX

BO_ 2365410814 GPM28: 8 Vector__XXX

BO_ 2365410558 GPM29: 8 Vector__XXX

BO_ 2365410302 GPM210: 8 Vector__XXX

BO_ 2365410046 GPM211: 8 Vector__XXX

BO_ 2365408254 MSSC: 8 Vector__XXX
 SG_ MachineSelectedDirectionCmd : 56|2@1+ (1,0) [0|0] "" Vector__XXX
 SG_ MchnSelectedSpeedExit_reasonCode : 48|5@1+ (1,0) [0|0] "" Vector__XXX
 SG_ MchineSelectedSpeedSetpointLimit : 16|16@1+ (1,0) [0|0] "" Vector__XXX
 SG_ MachineSelectedSpeedSetpointCmd : 0|16@1+ (1,0) [0|0] "" Vector__XXX

BO_ 2365407998 ICC: 8 Vector__XXX
 SG_ ISOBUSCmplncCrtfctnMssgeRevision : 47|1@1+ (1,0) [0|0] "" Vector__XXX
 SG_ ISOBUSCmplncCrtfctnRfrenceNumber : 48|16@1+ (1,0) [0|0] "" Vector__XXX
 SG_ ISOBUSCmplncCrtfctonTypeTaskCtrl : 39|1@1+ (1,0) [0|0] "" Vector__XXX
 SG_ ISOBUSCmplncCrtfctnTypTCWrkn4326 : 38|1@1+ (1,0) [0|0] "" Vector__XXX
 SG_ ISOBUSCmplncCrtfctnTypTCWrkngStM : 37|1@1+ (1,0) [0|0] "" Vector__XXX
 SG_ ISOBUSCmplncCrtfctnTypFileServer : 36|1@1+ (1,0) [0|0] "" Vector__XXX
 SG_ ISOBUSCmplncCrtfctnTypGPSRceiver : 35|1@1+ (1,0) [0|0] "" Vector__XXX
 SG_ ISOBUSCmplncCrtfcationTypeMinECU : 31|1@1+ (1,0) [0|0] "" Vector__XXX
 SG_ ISOBUSCmplncCrtfctnTypTECUClass1 : 30|1@1+ (1,0) [0|0] "" Vector__XXX
 SG_ ISOBUSCmplncCrtfctnTypTECUClass2 : 29|1@1+ (1,0) [0|0] "" Vector__XXX
 SG_ ISOBUSCmplncCrtfctnTypTECUClass3 : 28|1@1+ (1,0) [0|0] "" Vector__XXX
 SG_ ISOBUSCmplncCrtfctnTypeClass3ECU : 27|1@1+ (1,0) [0|0] "" Vector__XXX
 SG_ ISOBUSCmplncCrtfctnTypVrtlTrmnal : 26|1@1+ (1,0) [0|0] "" Vector__XXX
 SG_ ISOBUSCmplncCrtfctnTypVTWrkn4323 : 25|1@1+ (1,0) [0|0] "" Vector__XXX
 SG_ ISOBUSCmplncCrtfctnTypVTWrkngStM : 24|1@1+ (1,0) [0|0] "" Vector__XXX
 SG_ ISOBUSCmplncCrtfctonLaboratoryID : 13|11@1+ (1,0) [0|0] "" Vector__XXX
 SG_ ISOBUSCmplncCrtfctLaboratoryType : 9|3@1+ (1,0) [0|0] "" Vector__XXX
 SG_ ISOBUSCmplnceCertificateRevision : 6|3@1+ (1,0) [0|0] "" Vector__XXX
 SG_ ISOBUSCmplianceCertificationYear : 0|6@1+ (1,0) [0|0] "" Vector__XXX

BO_ 2365403902 TBD: 8 Vector__XXX

BO_ 2365391870 IOS: 8 Vector__XXX
 SG_ ImplementOperatingStateCmd : 56|2@1+ (1,0) [0|0] "" Vector__XXX

CM_ BO_ 2364598014 "This PGN contains timing offsets for cylinders 9-16.

These timing offsets are relative to the commanded engine timing advance (SPN 7355).";
CM_ SG_ 2364598014 EngCyl16TimingOffset "The ignition timing offset for Cylinder 16 from the engine timing advance (SPN 7355) as a command to the ignition control module. Positive values command an increasingly advanced timing.";
CM_ SG_ 2364598014 EngCyl15TimingOffset "The ignition timing offset for Cylinder 15 from the engine timing advance (SPN 7355) as a command to the ignition control module. Positive values command an increasingly advanced timing.";
CM_ SG_ 2364598014 EngCyl14TimingOffset "The ignition timing offset for Cylinder 14 from the engine timing advance (SPN 7355) as a command to the ignition control module. Positive values command an increasingly advanced timing.";
CM_ SG_ 2364598014 EngCyl13TimingOffset "The ignition timing offset for Cylinder 13 from the engine timing advance (SPN 7355) as a command to the ignition control module. Positive values command an increasingly advanced timing.";
CM_ SG_ 2364598014 EngCyl12TimingOffset "The ignition timing offset for Cylinder 12 from the engine timing advance (SPN 7355) as a command to the ignition control module. Positive values command an increasingly advanced timing.";
CM_ SG_ 2364598014 EngCyl11TimingOffset "The ignition timing offset for Cylinder 11 from the engine timing advance (SPN 7355) as a command to the ignition control module. Positive values command an increasingly advanced timing.";
CM_ SG_ 2364598014 EngCyl10TimingOffset "The ignition timing offset for Cylinder 10 from the engine timing advance (SPN 7355) as a command to the ignition control module. Positive values command an increasingly advanced timing.";
CM_ SG_ 2364598014 EngCyl9TimingOffset "The ignition timing offset for Cylinder 9 from the engine timing advance (SPN 7355) as a command to the ignition control module. Positive values command an increasingly advanced timing.";
CM_ BO_ 2364597758 "This PGN contains timing offsets for cylinders 1-8.

These timing offsets are relative to the commanded engine timing advance (SPN 7355).";
CM_ SG_ 2364597758 EngCyl8TimingOffset "The ignition timing offset for Cylinder 8 from the engine timing advance (SPN 7355) as a command to the ignition control module. Positive values command an increasingly advanced timing.";
CM_ SG_ 2364597758 EngCyl7TimingOffset "The ignition timing offset for Cylinder 7 from the engine timing advance (SPN 7355) as a command to the ignition control module. Positive values command an increasingly advanced timing.";
CM_ SG_ 2364597758 EngCyl6TimingOffset "The ignition timing offset for Cylinder 6 from the engine timing advance (SPN 7355) as a command to the ignition control module. Positive values command an increasingly advanced timing.";
CM_ SG_ 2364597758 EngCyl5TimingOffset "The ignition timing offset for Cylinder 5 from the engine timing advance (SPN 7355) as a command to the ignition control module. Positive values command an increasingly advanced timing.";
CM_ SG_ 2364597758 EngCyl4TimingOffset "The ignition timing offset for Cylinder 4 from the engine timing advance (SPN 7355) as a command to the ignition control module. Positive values command an increasingly advanced timing.";
CM_ SG_ 2364597758 EngCyl3TimingOffset "The ignition timing offset for Cylinder 3 from the engine timing advance (SPN 7355) as a command to the ignition control module. Positive values command an increasingly advanced timing.";
CM_ SG_ 2364597758 EngCyl2TimingOffset "The ignition timing offset for Cylinder 2 from the engine timing advance (SPN 7355) as a command to the ignition control module. Positive values command an increasingly advanced timing.";
CM_ SG_ 2364597758 EngCyl1TimingOffset "The ignition timing offset for Cylinder 1 from the engine timing advance (SPN 7355) as a command to the ignition control module. Positive values command an increasingly advanced timing.";
CM_ BO_ 2364593150 "Contains parameters related to predictive cruise control. Predictive cruise control is the process of varying the set point used by the cruise control algorithm based on external factors (e.g., anticipated road grade).";
CM_ SG_ 2364593150 PrdctvCrsCtrlDrvlnDsnggInhibitRq "Request to temporarily inhibit a fuel saving feature that would normally open the driveline. Under certain conditions and with knowledge of the terrain, inhibiting this feature may improve fuel economy.
SPN 683 Disengage Driveline Request has ...";
CM_ SG_ 2364593150 VhclSpdCtrlOvrrideEventIndicator "Indicates to the operator that a Speed Control override event is active.  \"Speed Control\" refers to retarders or methods of automatically limiting vehicle speed, for instance on downhill grades.  An active event indicates that vehicle speed may ...";
CM_ SG_ 2364593150 PrdctvCrsCtrlSpeedEventIndicator "Indicates to the operator that a predictive cruise control (PCC) speed event is active. Typically, this will correspond to a Predictive Cruise Control Set Speed Offset (SPN 7316) request to increase or decrease vehicle speed from the nominal cruise ...";
CM_ SG_ 2364593150 PredictiveCruiseCtrlNextGrade "Road grade at next predictive cruise control (PCC) event. Positive numbers indicate uphill grade, negative are downhill for vehicle direction of travel. For grades beyond the limits of the parameter, the limit value shall be reported.";
CM_ SG_ 2364593150 PredictiveCruiseCtrlPresentGrade "Road grade at present vehicle position. Positive numbers indicate uphill grade, negative are downhill for present vehicle direction of travel. For grades beyond the limits of the parameter, the limit value shall be reported.";
CM_ SG_ 2364593150 PredictiveCruiseCtrlEventInRange "Indicates that an event, such as a grade, is detected within the range of the predictive cruise control (PCC) look-ahead distance.
00 - No PCC event in range
01 - PCC event in range
10 - Error
11 - Not available
Note:  Intended to be sent ...";
CM_ SG_ 2364593150 VehicleSpeedCtrlOverrideRq "Speed control override requested. Indicates that the minimum restriction of speed is desired, for instance when travelling downhill towards an impending uphill grade. This is not a request to inhibit engine brakes (or other speed limiting device) ...";
CM_ SG_ 2364593150 PredictiveCruiseCtrlState "Indicates the state of the PCC controller.
If this parameter is 0001, the cruise control set point may be modified by the Predictive Cruise Control Set Speed Offset (SPN 7316) . For states other than 0001, the value in Predictive Cruise Control Set ...";
CM_ SG_ 2364593150 PrdctiveCruiseCtrlSetSpeedOffset "The amount by which the actual set point used by the cruise control algorithm should be changed as determined by external factors (e.g., anticipated road grade).
If SPN 7317 indicates Enabled (0001b) and if the cruise control algorithm determines ...";
CM_ BO_ 2364592894 "Transmits command information for the actuators associated with engine.";
CM_ SG_ 2364592894 EngCylHeadBypassActuator1Cmd "Command to cylinder head bypass actuator 1, normalized to percent, where 0% nominally represents fully closed (No Flow) and 100% represents fully open (Max Flow). The purpose of the cylinder bypass valve is to release the air at the high pressure ...";
CM_ BO_ 2364592638 "Transmits information about Engine Cylinder Head Bypass Actuator. The cylinder head bypass
valve is used to release the air at the high pressure compressor outlet into turbocharger turbine inlet
when intake pressure exceeds exhaust pressure at ...";
CM_ SG_ 2364592638 EngCylHdBypssActtr1OprtionStatus "Identifies the status of Engine Cylinder Head Bypass Actuator 1.
Cylinder head bypass valve is used to release the air at the high pressure compressor outlet into turbocharger turbine inlet when intake pressure exceeds exhaust pressure at lower ...";
CM_ SG_ 2364592638 EngCylHeadBypassActuator1Pos "Actual position of Engine Cylinder Head Bypass actuator, where 0% represents fully closed and 100% represents fully open.
Cylinder Head bypass valve is used to release the air at the high pressure compressor outlet into turbocharger turbine inlet ...";
CM_ SG_ 2364592638 EngCylHdBypssActuator1DesiredPos "Requested position of Engine Cylinder Head Bypass actuator by engine ECM, where 0% represents bypass fully closed and 100% represents fully open. This is the position that the device is attempting to achieve.
Cylinder Head bypass valve is used to ...";
CM_ SG_ 2364592638 EngCylHeadBypassActuator1Temp "Temperature of the Engine Cylinder Head Bypass Actuator 1 drive circuitry. Temperature excursions may affect the torque output.
Cylinder Head bypass valve is used to release the air at the high pressure compressor outlet into turbocharger turbine ...";
CM_ SG_ 2364592638 EngCylHdBypssActuator1TempStatus "Identifies the status of the Engine Cylinder Head Bypass Blowoff Actuator 1 drive circuitry temperature. Temperature excursions may affect the torque output.
Cylinder Head bypass valve is used to release the air at the high pressure compressor ...";
CM_ SG_ 2364592638 EngCylHdBypssActtr1PrliminaryFMI "Identifies the applicable J1939-73 FMI detected in Engine Cylinder Head Bypass Actuator 1 by the manufacturer's software. When there is no failure FMI 31 is transmitted. When there are multiple failures, the most severe is transmitted.
Cylinder ...";
CM_ BO_ 2364592382 "Transmits combustion related requests";
CM_ SG_ 2364592382 EngCyl24ExcludeFromCombustionRq "Request to the engine ECU to exclude (skip or cut-out) cylinder 24 from combustion.

00 Exclude from Combustion
01 Include for Combustion
10 Reserved
11 Not available/Do not care";
CM_ SG_ 2364592382 EngCyl23ExcludeFromCombustionRq "Request to the engine ECU to exclude (skip or cut-out) cylinder 23 from combustion.

00 Exclude from Combustion
01 Include for Combustion
10 Reserved
11 Not available/Do not care";
CM_ SG_ 2364592382 EngCyl22ExcludeFromCombustionRq "Request to the engine ECU to exclude (skip or cut-out) cylinder 22 from combustion.

00 Exclude from Combustion
01 Include for Combustion
10 Reserved
11 Not available/Do not care";
CM_ SG_ 2364592382 EngCyl21ExcludeFromCombustionRq "Request to the engine ECU to exclude (skip or cut-out) cylinder 21 from combustion.

00 Exclude from Combustion
01 Include for Combustion
10 Reserved
11 Not available/Do not care";
CM_ SG_ 2364592382 EngCyl20ExcludeFromCombustionRq "Request to the engine ECU to exclude (skip or cut-out) cylinder 20 from combustion.

00 Exclude from Combustion
01 Include for Combustion
10 Reserved
11 Not available/Do not care";
CM_ SG_ 2364592382 EngCyl19ExcludeFromCombustionRq "Request to the engine ECU to exclude (skip or cut-out) cylinder 19 from combustion.

00 Exclude from Combustion
01 Include for Combustion
10 Reserved
11 Not available/Do not care";
CM_ SG_ 2364592382 EngCyl18ExcludeFromCombustionRq "Request to the engine ECU to exclude (skip or cut-out) cylinder 18 from combustion.

00 Exclude from Combustion
01 Include for Combustion
10 Reserved
11 Not available/Do not care";
CM_ SG_ 2364592382 EngCyl17ExcludeFromCombustionRq "Request to the engine ECU to exclude (skip or cut-out) cylinder 17 from combustion.

00 Exclude from Combustion
01 Include for Combustion
10 Reserved
11 Not available/Do not care";
CM_ SG_ 2364592382 EngCyl16ExcludeFromCombustionRq "Request to the engine ECU to exclude (skip or cut-out) cylinder 16 from combustion.

00 Exclude from Combustion
01 Include for Combustion
10 Reserved
11 Not available/Do not care";
CM_ SG_ 2364592382 EngCyl15ExcludeFromCombustionRq "Request to the engine ECU to exclude (skip or cut-out) cylinder 15 from combustion.

00 Exclude from Combustion
01 Include for Combustion
10 Reserved
11 Not available/Do not care";
CM_ SG_ 2364592382 EngCyl14ExcludeFromCombustionRq "Request to the engine ECU to exclude (skip or cut-out) cylinder 14 from combustion.

00 Exclude from Combustion
01 Include for Combustion
10 Reserved
11 Not available/Do not care";
CM_ SG_ 2364592382 EngCyl13ExcludeFromCombustionRq "Request to the engine ECU to exclude (skip or cut-out) cylinder 13 from combustion.

00 Exclude from Combustion
01 Include for Combustion
10 Reserved
11 Not available/Do not care";
CM_ SG_ 2364592382 EngCyl12ExcludeFromCombustionRq "Request to the engine ECU to exclude (skip or cut-out) cylinder 12 from combustion.

00 Exclude from Combustion
01 Include for Combustion
10 Reserved
11 Not available/Do not care";
CM_ SG_ 2364592382 EngCyl11ExcludeFromCombustionRq "Request to the engine ECU to exclude (skip or cut-out) cylinder 11 from combustion.

00 Exclude from Combustion
01 Include for Combustion
10 Reserved
11 Not available/Do not care";
CM_ SG_ 2364592382 EngCyl10ExcludeFromCombustionRq "Request to the engine ECU to exclude (skip or cut-out) cylinder 10 from combustion.

00 Exclude from Combustion
01 Include for Combustion
10 Reserved
11 Not available/Do not care";
CM_ SG_ 2364592382 EngCyl9ExcludeFromCombustionRq "Request to the engine ECU to exclude (skip or cut-out) cylinder 9 from combustion.

00 Exclude from Combustion
01 Include for Combustion
10 Reserved
11 Not available/Do not care";
CM_ SG_ 2364592382 EngCyl8ExcludeFromCombustionRq "Request to the engine ECU to exclude (skip or cut-out) cylinder 8 from combustion.

00 Exclude from Combustion
01 Include for Combustion
10 Reserved
11 Not available/Do not care";
CM_ SG_ 2364592382 EngCyl7ExcludeFromCombustionRq "Request to the engine ECU to exclude (skip or cut-out) cylinder 7 from combustion.

00 Exclude from Combustion
01 Include for Combustion
10 Reserved
11 Not available/Do not care";
CM_ SG_ 2364592382 EngCyl6ExcludeFromCombustionRq "Request to the engine ECU to exclude (skip or cut-out) cylinder 6 from combustion.

00 Exclude from Combustion
01 Include for Combustion
10 Reserved
11 Not available/Do not care";
CM_ SG_ 2364592382 EngCyl5ExcludeFromCombustionRq "Request to the engine ECU to exclude (skip or cut-out) cylinder 5 from combustion.

00 Exclude from Combustion
01 Include for Combustion
10 Reserved
11 Not available/Do not care";
CM_ SG_ 2364592382 EngCyl4ExcludeFromCombustionRq "Request to the engine ECU to exclude (skip or cut-out) cylinder 4 from combustion.

00 Exclude from Combustion
01 Include for Combustion
10 Reserved
11 Not available/Do not care";
CM_ SG_ 2364592382 EngCyl3ExcludeFromCombustionRq "Request to the engine ECU to exclude (skip or cut-out) cylinder 3 from combustion.

00 Exclude from Combustion
01 Include for Combustion
10 Reserved
11 Not available/Do not care";
CM_ SG_ 2364592382 EngCyl2ExcludeFromCombustionRq "Request to the engine ECU to exclude (skip or cut-out) cylinder 2 from combustion.

00 Exclude from Combustion
01 Include for Combustion
10 Reserved
11 Not available/Do not care";
CM_ SG_ 2364592382 EngCyl1ExcludeFromCombustionRq "Request to the engine ECU to exclude (skip or cut-out) cylinder 1 from combustion.

00 Exclude from Combustion
01 Include for Combustion
10 Reserved
11 Not available/Do not care";
CM_ SG_ 2364592382 NmbrOfEngCylndrsTExcldFrmCmbston "Request to the engine ECU for the number of cylinders to exclude from combustion (cut-out or skip) for a given instance in time.  The engine ECU can decide on the cylinders to exclude from combustion.  One of the use cases would be sending this ...";
CM_ BO_ 2364567294 "Used to transmit the commanded % position for the Fuel Pump control valve.";
CM_ SG_ 2364567294 EngFlInjctnPump2FuelCtrlValveCmd "The control command to fuel control valve in fuel pump 2, normalized to percent, where 0% represents fully closed and 100% represents fully open.";
CM_ SG_ 2364567294 EngFlInjctnPump1FuelCtrlValveCmd "The control command to fuel control valve in fuel pump 1, normalized to percent, where 0% represents fully closed and 100% represents fully open.";
CM_ BO_ 2558918398 "Message containing parameters originating from the vehicle cab.";
CM_ SG_ 2558918398 PrdctvCriseCtrlMaxNegativeOffset "Maximum speed decrease that the predictive cruise control (PCC) is allowed to request. This may be adjusted by the operator (either directly or indirectly) to tailor the performance of the PCC system.
This parameter is used in conjunction with ...";
CM_ SG_ 2558918398 PrdctvCriseCtrlMaxPositiveOffset "Maximum speed increase that the predictive cruise control (PCC) is allowed to request. This may be adjusted by the operator (either directly or indirectly) to tailor the performance of the PCC system.
This parameter is used in conjunction with ...";
CM_ SG_ 2558918398 PrdctiveCruiseCtrlDeactivationRq "Indicates that the operator has requested to deactivate the predictive cruise control (PCC) function.
If enabled, the PCC device may still provide notification of events in range, road grade, and other information. But if requested to be ...";
CM_ SG_ 2558918398 PredictiveCruiseCtrlEnableSwitch "Indicates whether predictive cruise control (PCC) is enabled. When not enabled, the predictive cruise control does not calculate a speed offset or identify predictive cruise events, and the predictive cruise control state (SPN 7317) shall not be ...";
CM_ SG_ 2558918398 HtExchngerDebrisPurgeForceSwitch "Indicates the state of a switch available to the operator that forces the system to purge the debris from the heat exchanger.
00   not active
01   active
10   error
11   not available
This SPN would be “not active” when purging the debris from ...";
CM_ SG_ 2558918398 HtExchngrDbrisPurgeInhibitSwitch "Indicates the state of a switch available to the operator that will inhibit the system from purging the debris from the heat exchanger.
00   not active
01   active
10   error
11   not available
This SPN would be “not active” when purging the ...";
CM_ SG_ 2558918398 SCROprtrInducementOverrideSwitch "The position of the operator inducement override switch. This switch function allows the operator to override an operator inducement derate.
See EU Commission directive 2012/46/EU. Appendix 1 Section 5.5 for more information.
00 Off
01 On
10 ...";
CM_ SG_ 2558918398 PerformanceBiasSelection "Indicates the operating bias toward performance of the power source.
0% Functionality is biased toward fuel economy as much as possible.
50% Functionality is biased toward neither fuel economy or performance.
100% Functionality is biased toward ...";
CM_ SG_ 2558918398 EngFan2RequestedPercentSpeed "Fan speed of the second fan in the system as a ratio of the actual fan drive (current speed) to the fully engaged fan drive (maximum fan speed). A two state fan (off/on) will use 0% and 100% respectively.  A three state fan (off/intermediate/on) ...";
CM_ BO_ 2558852862 "This PGN contains parameters used to control the particulate sensor and to provide data that the particulate sensor needs to operate.";
CM_ SG_ 2558852862 AT1PrtclateSensorExhaustVelocity "Velocity of the exhaust gas near the particulate sensor.";
CM_ SG_ 2558852862 AT1ParticulateSensorExhaustTemp "This is the temperature in the exhaust stream that is closest to the particulate sensor. This could be a calculated value or read from another sensor. The ECU transmitting this message to the particulate sensor controller will be aware of the ...";
CM_ SG_ 2558852862 AT1ParticulateSensorDewpoint "Indicates that the temperature near the particulate sensor has exceeded the dew point.

00 - Dewpoint has not been reached
01 - Dewpoint has been reached
10 - SAE reserved
11 - Not available";
CM_ SG_ 2558852862 AT1PrtculateSensorRegenerationRq "Another ECU would send this to request that the particulate sensor perform a regeneration of the sensor.  A request would be considered active when this parameter transitions from 00 to 01.
00 - Regeneration not requested
01 - Regeneration ...";
CM_ SG_ 2558852862 AT1ParticulateSensorShutdownRq "Aftertreatment 1 particulate sensor shutdown request.

00 - Shutdown request not active
01 - Shutdown request active
10 - SAE reserved
11 - Not available";
CM_ BO_ 2558787326 "Calibration setting commands for the Payload Measurement System.";
CM_ SG_ 2558787326 PayloadCorrectionFactorCmd "The payload correction factor is used to fine tune the sensor gain value.
Correction factor calibration of the Payload Measurement system is performed through a Payload Calibration Set Point SPN value of Correction Point and the Payload Correction ...";
CM_ SG_ 2558787326 PayloadCalibCommandedWeight "The true known mass of real load weight applicable for the calibration point specified in SPN 6871 and used for calibrating Payload system.
Multipoint calibration of the Payload Measurement system is perfomed by loading the machine with up to 10 ...";
CM_ SG_ 2558787326 PayloadCalibSetPointCmd "Specifies the current payload point being calibrated. The data specified in the 'Payload Calibration Commanded Weight' SPN (SPN 6872) or 'Payload Correction Factor Command' SPN (SPN 6873) shall be used for calibrating this specified payload point ...";
CM_ BO_ 2558721790 "Details the attributes for the tire monitoring settings for the tires.";
CM_ SG_ 2558721790 OverTempSetting "Configurable constant temperature above which an over temperature alert will trigger.";
CM_ SG_ 2558721790 OvrPrssPrcentageThresholdSetting "Configurable percentage deviation from the set cold inflation pressure, for the over tire pressure alert.";
CM_ SG_ 2558721790 ExtrmUndrPrssPrcntgThrshldStting "Configurable percent deviation from the set cold inflation pressure, for the extreme under tire pressure alert.";
CM_ SG_ 2558721790 UndrPrssPrcntageThresholdSetting "Configurable percent deviation from the set cold inflation pressure, for the under tire pressure alert.";
CM_ SG_ 2558721790 ColdInflationPressSetting "Configurable value of the cold inflation pressure of the tire. Cold inflation pressure is the default/reference inflation pressure suggested by the manufacturer for a specific tire.";
CM_ SG_ 2558721790 TireLocation "The location of monitored tire on the vehicle.
The high order 4 bits indicate the vehicle axle position of the tire, counting front to back on the vehicle, with the value 0 representing the front axle on the vehicle. If the upper 4 bits have a ...";
CM_ BO_ 2558656254 "Used to request the aftertreatment system to perform or inhibit certain operations.";
CM_ SG_ 2558656254 RqToPermitDEFDosingTestInjection "A request to permit the DEF dosing test injection. The request continues to be broadcast until the test injection is finished or the corresponding permission status indicates an error.
000 = no request
001 = request to permit DEF Dosing Test ...";
CM_ SG_ 2558656254 RqToPermitDEFHydStiffnessCheck "A request to permit the DEF hydraulic stiffness check. The request continues to be broadcast until the stiffness check is finished or the corresponding permission status indicates an error.
00 = no request
01 = request to permit DEF hydraulic ...";
CM_ SG_ 2558656254 ATThermalManagementInhibitRq "Provides state of inhibit request for Aftertreatment thermal management from external system.
Aftertreatment Thermal Management indicates that the exhaust temperatures have been controlled for expected functioning of the aftertreatment system - ...";
CM_ BO_ 2558590718 "This messages is sent to the hybrid system to control hybrid related features.";
CM_ SG_ 2558590718 HybrdSystmRgnrtvBrakingDisableRq "Indicates the hybrid system regenerative braking disable request state.  This signal gives network controllers the ability to disable all regenerative braking.  This is not the operator controlled switch that performs regenerative braking disable ...";
CM_ SG_ 2558590718 HybridSystemProtectionOverrideRq "Indicates the hybrid system protection override request state.  This request allows overriding of hybrid system protection
features and failure modes allowing hybrid systems to continue to operate, if possible. This is not the physical switch that ...";
CM_ BO_ 2350776062 "Commanded engine ignition timing advance";
CM_ SG_ 2350776062 EngTimingAdvance "Ignition timing as a command to the ignition control module.  Positive values command an increasingly advanced timing from TDC. The same timing applies to all cylinders. Use SPN 7356 - SPN 7379 for cylinder specific timing offsets from this timing.";
CM_ BO_ 2350710526 "This message is used to control the output speed and/or torque of a transmission.
For example, this message could be directed toward a continuously variable transmission (CVT) where output speed and torque are not directly dependent on input speed ...";
CM_ SG_ 2350710526 MessageChecksum "The message checksum is used to verify the signal path from the transmitting device to the receiving device.
The message checksum is calculated using the first 7 data bytes, the message counter and the bytes of the message identifier. It is ...";
CM_ SG_ 2350710526 TransRequestedTorque_TorqueLimit "Parameter provided to the transmission in the torque/speed control message for controlling or limiting the output torque.
Note:  0% to 125% for (positive) powered torque requests, -125% to 0% for (negative) retarding torque requests.  Does not ...";
CM_ SG_ 2350710526 TransRequestedOutputShaftSpeed "Used to request output shaft speed of the transmission which has a output through a driveline to the wheels of a machine/vehicle.";
CM_ SG_ 2350710526 MessageCounter "The message counter is used to detect situations where the transmitting ECU malfunction repeats the same frame all the time.  The receiver of the information may use the counter parameter to detect this situation.
Note:  The initial value of the 4 ...";
CM_ SG_ 2350710526 TransOverrideCtrlModePriority "This field is used as an input to the transmission to determine the priority of the Override Control Mode received in the Torque/Speed Control message.  The default is 11 (Low priority).  It is not required to use the same priority during the entire ...";
CM_ SG_ 2350710526 TransOverrideCtrlMode "The override control mode defines the type of control mode used to control transmission operation.
00 = Override disabled - Disable any existing control commanded by the source of this command.
01 = Speed control - Control speed to the included ...";
CM_ BO_ 2381315838 "This proprietary PG uses the Destination Specific PDU Format allowing manufacturers to direct their proprietary communications to a specific destination node.";
CM_ BO_ 2365510142 "SAE J1939 will not specify an implementation for this DM.  Oxygen sensor test and results should be communicated using DM7 and DM8";
CM_ BO_ 2365475326 "This message is normally sent by the Tractor ECU on the implement bus on construction and agricultural implements and provides to connected systems, the current measured ground speed.";
CM_ SG_ 2365475326 GroundBasedDirection "A measured signal indicating either forward or reverse as the direction of travel.  When speed is zero, indicate the last travel direction until a different direction is detected.

00 Reverse
01 Forward
10 Error indication
11 Not available";
CM_ SG_ 2365475326 GroundBasedImplementDistance "Actual distance travelled by a machine based on measurements from a sensor such as RADAR.  When distance exceeds 4 211 081.215 m, the value should be reset to zero and incremented as additional distance accrues.";
CM_ SG_ 2365475326 GroundBasedImplementSpeed "Actual ground speed of a machine, measured by a sensor such as RADAR.";
CM_ BO_ 2365475070 "This message is sent by the Tractor ECU on the implement bus on construction and agricultural implements and provides to connected systems, the current measured wheel-based speed.";
CM_ SG_ 2365475070 KeySwitchNOTOFF "Indicates the Key Switch of the tractor or power unit is NOT in the Off position. This does not indicate unforeseen power interruption such as those caused by starting the engine or due to connector intermittents.
00 Key Switch Off
01 Key Switch ...";
CM_ SG_ 2365475070 WheelBasedDirection "A measured signal indicating either forward or reverse as the direction of travel.  When speed is zero, indicate the last travel direction until a different direction is detected or selected and engaged.
00 Reverse
01 Forward
10 Error indication
 ...";
CM_ SG_ 2365475070 MaxTimeOfTractorPower "The maximum time of remaining tractor or power unit supplied electrical power at the current load.";
CM_ SG_ 2365475070 WheelBasedDistance "The distance travelled by a machine as calculated from wheel or tail shaft speed.  When distance exceeds 4211081,215 m, the value should be reset to zero and incremented as additional distance accrues.";
CM_ SG_ 2365475070 WheelBasedSpeed "A value of the speed of a machine as calculated from the measured wheel or tail shaft speed.";
CM_ BO_ 2365474814 "This message is sent by any ECU connected to the implement bus requesting that the Tractor ECU not switch off the power for the next 2 seconds.";
CM_ SG_ 2365474814 ImplementInWorkState "Indicates that an implement is connected to a tractor or power unit and is “in-work”.

00   Implement is “out of work”
01   Implement is “in-work”
10   Error indication
11   Not available";
CM_ SG_ 2365474814 ImplementTransportState "Indicates the transport state of an implement connected to a tractor or power unit.

00 Implement may Not be transported 
01 Implement may be transported
10 Error indication
11 Not available";
CM_ SG_ 2365474814 ImplementParkState "Indicates the state of an implement where it may be disconnected from a tractor or power unit.

00 Implement may Not be disconnected 
01 Implement may be disconnected
10 Error indication
11 Not available";
CM_ SG_ 2365474814 ImplementWorkState "Indicates that an implement is connected to a tractor or power unit and is ready for work

00 Implement is Not ready for field work 
01 Implement is ready for field work
10 Error indication
11 Not available";
CM_ SG_ 2365474814 MaintainECUPower "Request to the Tractor ECU to maintain ECU_PWR power for the next 2 seconds.

00 No Further Requirement for ECU_PWR
01 Requirement for 2 more seconds of ECU_PWR
10 Reserved 
11 Don’t Care";
CM_ SG_ 2365474814 MaintainAcuatorPower "Request to the Tractor ECU to maintain PWR power for the next 2 seconds.

00 No Further Requirement for PWR
01 Requirement for 2 more seconds of PWR
10 Reserved 
11 Don’t Care";
CM_ BO_ 2365474558 "This message provides the measurement of the current front hitch parameters.";
CM_ SG_ 2365474558 FrontDraft "The apparent horizontal force applied to the front hitch by an implement.  A positive value indicates force applied to the tractor opposed to heading.";
CM_ SG_ 2365474558 FrontNominalLowerLinkForce "This measurement provides an indication of draft at the lower links of the front three point hitch. Nominal lower link force may be expected to be approximately linear with respect to draft and may be proportional to draft for a single hitch ...";
CM_ SG_ 2365474558 FrontHitchInworkIndication "A measured signal indicating that the front hitch is positioned below (in-work) or above (out-of-work) an adjustable switching threshold.

00 Hitch position is out-of-work 
01 Hitch position is in-work
10 Error indication
11 Not available";
CM_ SG_ 2365474558 FrontHitchPos "The measured position of the front three-point-hitch.  Expressed as a percentage of full travel.  Zero percent indicates the full down position, and 100%, the full up position.";
CM_ BO_ 2365474302 "This message provides the measurement of the current rear hitch parameters.";
CM_ SG_ 2365474302 RearHitchExit_reasonCode "This parameter indicates why the Rear Hitch cannot accept remote commands or has most recently stopped accepting remote commands.
0-No reason/all clear
1-Operator presence not detected
2-Implement released control of function
3-Operator override ...";
CM_ SG_ 2365474302 RearDraft "The apparent horizontal force applied to the rear hitch by an implement.  A positive value indicates force applied to the tractor opposed to heading.";
CM_ SG_ 2365474302 RearNominalLowerLinkForce "This measurement provides an indication of draft at the lower links of the rear three point hitch. Nominal lower link force may be expected to be approximately linear with respect to draft and may be proportional to draft for a single hitch ...";
CM_ SG_ 2365474302 RearHitchInworkIndication "A measured signal indicating that the rear hitch is positioned below (in-work) or above (out-of-work) an adjustable switching threshold.  The method of determining switching threshold is not standardise and will be determined by machine designers.
 ...";
CM_ SG_ 2365474302 RearHitchPos "The measured position of the rear three-point-hitch.  Expressed as a percentage of full travel.  Zero percent indicates the full down position, and 100%, the full up position.";
CM_ BO_ 2365474046 "This message provides the measurement of the current secondary or front PTO output shaft parameters.";
CM_ SG_ 2365474046 FrontPTOExit_reasonCode "This parameter indicates why the Front PTO cannot accept remote commands or has most recently stopped accepting remote commands.
0-No reason/all clear
1-Operator presence not detected
2-Implement released control of function
3-Operator override ...";
CM_ SG_ 2365474046 FrontHitchExit_reasonCode "This parameter indicates why the Front Hitch cannot accept remote commands or has most recently stopped accepting remote commands.
0-No reason/all clear
1-Operator presence not detected
2-Implement released control of function
3-Operator ...";
CM_ SG_ 2365474046 FrontPowerTakeOffEngagement "A measured signal indicating that the front power take off is engaged or disengage.

00 Power take off disengaged
01 Power take off engaged
10 Error indication
11 Not available";
CM_ SG_ 2365474046 FrontPowerTakeOffMode "A measured signal indicating that the front power take off mode is either 540 or 1000 rpm. 

00 Power take off mode is 540
01 Power take off mode is 1000
10 Error indication
11 Not available";
CM_ SG_ 2365474046 FrontPowerTakeOffEconomyMode "A measured signal indicating that the front power take off economy mode is engaged or disengaged. Economy mode PTO operate at 540 or 1000 rpm at a lower engine rpm.
00 Power take off economy mode is disengaged
01 Power take off economy mode is ...";
CM_ SG_ 2365474046 FrontPTOOutputShaftSpeedSetPoint "The measured value of the set point of the rotational speed of the front power take off (PTO) output shaft.";
CM_ SG_ 2365474046 FrontPTOOutputShaftSpeed "The measured rotational speed of the front power take off (PTO) output shaft. For existing tractors that monitor PTO speed prior to the engagement clutch, the PTO speed would only be valid when PTO is engaged and not available when PTO disengaged.";
CM_ BO_ 2365473790 "This message provides the measurement of the current primary or rear PTO output shaft parameters.";
CM_ SG_ 2365473790 RearPTOExit_reasonCode "This parameter indicates why the Rear PTO cannot accept remote commands or has most recently stopped accepting remote commands.
0-No reason/all clear
1-Operator presence not detected
2-Implement released control of function
3-Operator override ...";
CM_ SG_ 2365473790 RearPowerTakeOffEngagement "A measured signal indicating that the rear power take off is engaged or disengage.

00 Power take off disengaged
01 Power take off engaged
10 Error indication
11 Not available";
CM_ SG_ 2365473790 RearPowerTakeOffMode "A measured signal indicating that the rear power take off mode is either 540 or 1000 rpm. 

00 Power take off mode is 540
01 Power take off mode is 1000
10 Error indication
11 Not available";
CM_ SG_ 2365473790 RearPowerTakeOffEconomyMode "A measured signal indicating that the rear power take off economy mode is engaged or disengaged. Economy mode PTO operate at 540 or 1000 rpm at a lower engine rpm.
00 Power take off economy mode is disengaged
01 Power take off economy mode is ...";
CM_ SG_ 2365473790 RearPTOOutputShaftSpeedSetPoint "The measured value of the set point of the rotational speed of the rear power take off (PTO) output shaft.";
CM_ SG_ 2365473790 RearPTOOutputShaftSpeed "The measured rotational speed of the rear power take off (PTO) output shaft. For existing tractors that monitor PTO speed prior to the engagement clutch, the PTO speed would only be valid when PTO is engaged and not available when PTO disengaged.";
CM_ BO_ 2365473534 "This message provides control of the hitch position, PTO shaft set point speed and PTO engagement.";
CM_ SG_ 2365473534 FrontPowerTakeOffModeCmd "The command to select the mode of the front power take off .

00 Select 540 rpm mode
01 Select 1000 rpm mode 
10 Reserved
11 Don’t Care";
CM_ SG_ 2365473534 RearPowerTakeOffModeCmd "The command to select the mode of the rear power take off .

00 Select 540 rpm mode
01 Select 1000 rpm mode 
10 Reserved
11 Don’t Care";
CM_ SG_ 2365473534 FrontPowerTakeOffEconomyModeCmd "The command to engage or disengage the front power take off‘s economy mode.

00 Disengage Power take off‘s economy mode
01 Engage Power take off‘s economy mode
10 Reserved
11 Don’t Care";
CM_ SG_ 2365473534 RearPowerTakeOffEconomyModeCmd "The command to engage or disengage the rear power take off‘s economy mode.

00 Disengage Power take off‘s economy mode
01 Engage Power take off‘s economy mode
10 Reserved
11 Don’t Care";
CM_ SG_ 2365473534 FrontPowerTakeOffEngagementCmd "The command to engage or disengage the front power take off .

00 Disengage Power take off
01 Engage Power take off 
10 Reserved
11 Don’t Care";
CM_ SG_ 2365473534 RearPowerTakeOffEngagementCmd "The command to engage or disengage the rear power take off .

00 Disengage Power take off
01 Engage Power take off 
10 Reserved
11 Don’t Care";
CM_ SG_ 2365473534 RrPTOOutputShaftSpeedSetPointCmd "The command to set the rotational speed of the rear power take off (PTO) output shaft.";
CM_ SG_ 2365473534 FrntPTOOtptShaftSpeedSetPointCmd "The command to set the rotational speed of the front power take off (PTO) output shaft.";
CM_ SG_ 2365473534 RearHitchPosCmd "Command to allow the position of the rear three-point-hitch to be set.  Expressed as a percentage of full travel.  Zero percent indicates the full down position, and 100%, the full up position.";
CM_ SG_ 2365473534 FrontHitchPosCmd "Command to allow the position of the front three-point-hitch to be set.  Expressed as a percentage of full travel.  Zero percent indicates the full down position, and 100%, the full up position.";
CM_ BO_ 2365472766 "This message provides control of the flow through the auxiliary valves.";
CM_ SG_ 2365472766 AuxValve15FailSafeModeCmd "Command for setting the fail safe mode of an auxiliary valve.

00 Block
01 Float
10 Reserved
11 Don’t Care";
CM_ SG_ 2365472766 AuxValve15StateCmd "Command for setting the auxiliary valve state.  With float enabled, hydraulic fluid may flow to or from the tractor as driven by the implement.

0000 Block
0001 Extend
0010 Retract
0011 Float
0100-1110 Reserved
1111 Don’t Care";
CM_ SG_ 2365472766 AuxValve15PortFlowCmd "The command to set the flow through the  extend or retract port of an auxiliary valve of a tractor, expressed as a percentage of full flow.  Zero percent indicates no flow, 100% indicates maximum flow, flow returns to the tractor through the ...";
CM_ BO_ 2365472510 "This message provides control of the flow through the auxiliary valves.";
CM_ SG_ 2365472510 AuxValve14FailSafeModeCmd "Command for setting the fail safe mode of an auxiliary valve.

00 Block
01 Float
10 Reserved
11 Don’t Care";
CM_ SG_ 2365472510 AuxValve14StateCmd "Command for setting the auxiliary valve state.  With float enabled, hydraulic fluid may flow to or from the tractor as driven by the implement.

0000 Block
0001 Extend
0010 Retract
0011 Float
0100-1110 Reserved
1111 Don’t Care";
CM_ SG_ 2365472510 AuxValve14PortFlowCmd "The command to set the flow through the  extend or retract port of an auxiliary valve of a tractor, expressed as a percentage of full flow.  Zero percent indicates no flow, 100% indicates maximum flow, flow returns to the tractor through the ...";
CM_ BO_ 2365472254 "This message provides control of the flow through the auxiliary valves.";
CM_ SG_ 2365472254 AuxValve13FailSafeModeCmd "Command for setting the fail safe mode of an auxiliary valve.

00 Block
01 Float
10 Reserved
11 Don’t Care";
CM_ SG_ 2365472254 AuxValve13StateCmd "Command for setting the auxiliary valve state.  With float enabled, hydraulic fluid may flow to or from the tractor as driven by the implement.

0000 Block
0001 Extend
0010 Retract
0011 Float
0100-1110 Reserved
1111 Don’t Care";
CM_ SG_ 2365472254 AuxValve13PortFlowCmd "The command to set the flow through the  extend or retract port of an auxiliary valve of a tractor, expressed as a percentage of full flow.  Zero percent indicates no flow, 100% indicates maximum flow, flow returns to the tractor through the ...";
CM_ BO_ 2365471998 "This message provides control of the flow through the auxiliary valves.";
CM_ SG_ 2365471998 AuxValve12FailSafeModeCmd "Command for setting the fail safe mode of an auxiliary valve.

00 Block
01 Float
10 Reserved
11 Don’t Care";
CM_ SG_ 2365471998 AuxValve12StateCmd "Command for setting the auxiliary valve state.  With float enabled, hydraulic fluid may flow to or from the tractor as driven by the implement.

0000 Block
0001 Extend
0010 Retract
0011 Float
0100-1110 Reserved
1111 Don’t Care";
CM_ SG_ 2365471998 AuxValve12PortFlowCmd "The command to set the flow through the  extend or retract port of an auxiliary valve of a tractor, expressed as a percentage of full flow.  Zero percent indicates no flow, 100% indicates maximum flow, flow returns to the tractor through the ...";
CM_ BO_ 2365471742 "This message provides control of the flow through the auxiliary valves.";
CM_ SG_ 2365471742 AuxValve11FailSafeModeCmd "Command for setting the fail safe mode of an auxiliary valve.

00 Block
01 Float
10 Reserved
11 Don’t Care";
CM_ SG_ 2365471742 AuxValve11StateCmd "Command for setting the auxiliary valve state.  With float enabled, hydraulic fluid may flow to or from the tractor as driven by the implement.

0000 Block
0001 Extend
0010 Retract
0011 Float
0100-1110 Reserved
1111 Don’t Care";
CM_ SG_ 2365471742 AuxValve11PortFlowCmd "The command to set the flow through the  extend or retract port of an auxiliary valve of a tractor, expressed as a percentage of full flow.  Zero percent indicates no flow, 100% indicates maximum flow, flow returns to the tractor through the ...";
CM_ BO_ 2365471486 "This message provides control of the flow through the auxiliary valves.";
CM_ SG_ 2365471486 AuxValve10FailSafeModeCmd "Command for setting the fail safe mode of an auxiliary valve.

00 Block
01 Float
10 Reserved
11 Don’t Care";
CM_ SG_ 2365471486 AuxValve10StateCmd "Command for setting the auxiliary valve state.  With float enabled, hydraulic fluid may flow to or from the tractor as driven by the implement.

0000 Block
0001 Extend
0010 Retract
0011 Float
0100-1110 Reserved
1111 Don’t Care";
CM_ SG_ 2365471486 AuxValve10PortFlowCmd "The command to set the flow through the  extend or retract port of an auxiliary valve of a tractor, expressed as a percentage of full flow.  Zero percent indicates no flow, 100% indicates maximum flow, flow returns to the tractor through the ...";
CM_ BO_ 2365471230 "This message provides control of the flow through the auxiliary valves.";
CM_ SG_ 2365471230 AuxValve9FailSafeModeCmd "Command for setting the fail safe mode of an auxiliary valve.

00 Block
01 Float
10 Reserved
11 Don’t Care";
CM_ SG_ 2365471230 AuxValve9StateCmd "Command for setting the auxiliary valve state.  With float enabled, hydraulic fluid may flow to or from the tractor as driven by the implement.

0000 Block
0001 Extend
0010 Retract
0011 Float
0100-1110 Reserved
1111 Don’t Care";
CM_ SG_ 2365471230 AuxValve9PortFlowCmd "The command to set the flow through the  extend or retract port of an auxiliary valve of a tractor, expressed as a percentage of full flow.  Zero percent indicates no flow, 100% indicates maximum flow, flow returns to the tractor through the ...";
CM_ BO_ 2365470974 "This message provides control of the flow through the auxiliary valves.";
CM_ SG_ 2365470974 AuxValve8FailSafeModeCmd "Command for setting the fail safe mode of an auxiliary valve.

00 Block
01 Float
10 Reserved
11 Don’t Care";
CM_ SG_ 2365470974 AuxValve8StateCmd "Command for setting the auxiliary valve state.  With float enabled, hydraulic fluid may flow to or from the tractor as driven by the implement.

0000 Block
0001 Extend
0010 Retract
0011 Float
0100-1110 Reserved
1111 Don’t Care";
CM_ SG_ 2365470974 AuxValve8PortFlowCmd "The command to set the flow through the  extend or retract port of an auxiliary valve of a tractor, expressed as a percentage of full flow.  Zero percent indicates no flow, 100% indicates maximum flow, flow returns to the tractor through the ...";
CM_ BO_ 2365470718 "This message provides control of the flow through the auxiliary valves.";
CM_ SG_ 2365470718 AuxValve7FailSafeModeCmd "Command for setting the fail safe mode of an auxiliary valve.

00 Block
01 Float
10 Reserved
11 Don’t Care";
CM_ SG_ 2365470718 AuxValve7StateCmd "Command for setting the auxiliary valve state.  With float enabled, hydraulic fluid may flow to or from the tractor as driven by the implement.

0000 Block
0001 Extend
0010 Retract
0011 Float
0100-1110 Reserved
1111 Don’t Care";
CM_ SG_ 2365470718 AuxValve7PortFlowCmd "The command to set the flow through the  extend or retract port of an auxiliary valve of a tractor, expressed as a percentage of full flow.  Zero percent indicates no flow, 100% indicates maximum flow, flow returns to the tractor through the ...";
CM_ BO_ 2365470462 "This message provides control of the flow through the auxiliary valves.";
CM_ SG_ 2365470462 AuxValve6FailSafeModeCmd "Command for setting the fail safe mode of an auxiliary valve.

00 Block
01 Float
10 Reserved
11 Don’t Care";
CM_ SG_ 2365470462 AuxValve6StateCmd "Command for setting the auxiliary valve state.  With float enabled, hydraulic fluid may flow to or from the tractor as driven by the implement.

0000 Block
0001 Extend
0010 Retract
0011 Float
0100-1110 Reserved
1111 Don’t Care";
CM_ SG_ 2365470462 AuxValve6PortFlowCmd "The command to set the flow through the  extend or retract port of an auxiliary valve of a tractor, expressed as a percentage of full flow.  Zero percent indicates no flow, 100% indicates maximum flow, flow returns to the tractor through the ...";
CM_ BO_ 2365470206 "This message provides control of the flow through the auxiliary valves.";
CM_ SG_ 2365470206 AuxValve5FailSafeModeCmd "Command for setting the fail safe mode of an auxiliary valve.

00 Block
01 Float
10 Reserved
11 Don’t Care";
CM_ SG_ 2365470206 AuxValve5StateCmd "Command for setting the auxiliary valve state.  With float enabled, hydraulic fluid may flow to or from the tractor as driven by the implement.

0000 Block
0001 Extend
0010 Retract
0011 Float
0100-1110 Reserved
1111 Don’t Care";
CM_ SG_ 2365470206 AuxValve5PortFlowCmd "The command to set the flow through the  extend or retract port of an auxiliary valve of a tractor, expressed as a percentage of full flow.  Zero percent indicates no flow, 100% indicates maximum flow, flow returns to the tractor through the ...";
CM_ BO_ 2365469950 "This message provides control of the flow through the auxiliary valves.";
CM_ SG_ 2365469950 AuxValve4FailSafeModeCmd "Command for setting the fail safe mode of an auxiliary valve.

00 Block
01 Float
10 Reserved
11 Don’t Care";
CM_ SG_ 2365469950 AuxValve4StateCmd "Command for setting the auxiliary valve state.  With float enabled, hydraulic fluid may flow to or from the tractor as driven by the implement.

0000 Block
0001 Extend
0010 Retract
0011 Float
0100-1110 Reserved
1111 Don’t Care";
CM_ SG_ 2365469950 AuxValve4PortFlowCmd "The command to set the flow through the  extend or retract port of an auxiliary valve of a tractor, expressed as a percentage of full flow.  Zero percent indicates no flow, 100% indicates maximum flow, flow returns to the tractor through the ...";
CM_ BO_ 2365469694 "This message provides control of the flow through the auxiliary valves.";
CM_ SG_ 2365469694 AuxValve3FailSafeModeCmd "Command for setting the fail safe mode of an auxiliary valve.

00 Block
01 Float
10 Reserved
11 Don’t Care";
CM_ SG_ 2365469694 AuxValve3StateCmd "Command for setting the auxiliary valve state.  With float enabled, hydraulic fluid may flow to or from the tractor as driven by the implement.

0000 Block
0001 Extend
0010 Retract
0011 Float
0100-1110 Reserved
1111 Don’t Care";
CM_ SG_ 2365469694 AuxValve3PortFlowCmd "The command to set the flow through the  extend or retract port of an auxiliary valve of a tractor, expressed as a percentage of full flow.  Zero percent indicates no flow, 100% indicates maximum flow, flow returns to the tractor through the ...";
CM_ BO_ 2365469438 "This message provides control of the flow through the auxiliary valves.";
CM_ SG_ 2365469438 AuxValve2FailSafeModeCmd "Command for setting the fail safe mode of an auxiliary valve.

00 Block
01 Float
10 Reserved
11 Don’t Care";
CM_ SG_ 2365469438 AuxValve2StateCmd "Command for setting the auxiliary valve state.  With float enabled, hydraulic fluid may flow to or from the tractor as driven by the implement.

0000 Block
0001 Extend
0010 Retract
0011 Float
0100-1110 Reserved
1111 Don’t Care";
CM_ SG_ 2365469438 AuxValve2PortFlowCmd "The command to set the flow through the  extend or retract port of an auxiliary valve of a tractor, expressed as a percentage of full flow.  Zero percent indicates no flow, 100% indicates maximum flow, flow returns to the tractor through the ...";
CM_ BO_ 2365469182 "This message provides control of the flow through the auxiliary valves.";
CM_ SG_ 2365469182 AuxValve1FailSafeModeCmd "Command for setting the fail safe mode of an auxiliary valve.

00 Block
01 Float
10 Reserved
11 Don’t Care";
CM_ SG_ 2365469182 AuxValve1StateCmd "Command for setting the auxiliary valve state.  With float enabled, hydraulic fluid may flow to or from the tractor as driven by the implement.

0000 Block
0001 Extend
0010 Retract
0011 Float
0100-1110 Reserved
1111 Don’t Care";
CM_ SG_ 2365469182 AuxValve1PortFlowCmd "The command to set the flow through the  extend or retract port of an auxiliary valve of a tractor, expressed as a percentage of full flow.  Zero percent indicates no flow, 100% indicates maximum flow, flow returns to the tractor through the ...";
CM_ BO_ 2365468926 "This message provides control of the flow through the auxiliary valves.";
CM_ SG_ 2365468926 AuxValve0FailSafeModeCmd "Command for setting the fail safe mode of an auxiliary valve.

00 Block
01 Float
10 Reserved
11 Don’t Care";
CM_ SG_ 2365468926 AuxValve0StateCmd "Command for setting the auxiliary valve state.  With float enabled, hydraulic fluid may flow to or from the tractor as driven by the implement.

0000 Block
0001 Extend
0010 Retract
0011 Float
0100-1110 Reserved
1111 Don’t Care";
CM_ SG_ 2365468926 AuxValve0PortFlowCmd "The command to set the flow through the  extend or retract port of an auxiliary valve of a tractor, expressed as a percentage of full flow.  Zero percent indicates no flow, 100% indicates maximum flow, flow returns to the tractor through the ...";
CM_ BO_ 2365468670 "This message provides the measurement of specified auxiliary valve.";
CM_ SG_ 2365468670 AuxValve15ReturnPortPress "The measured nominal pressure at the return port of an auxiliary valve of a tractor.";
CM_ SG_ 2365468670 AuxValve15RetractPortPress "The measured nominal pressure at the retract port of an auxiliary valve of a tractor.";
CM_ SG_ 2365468670 AuxValve15ExtendPortPress "The measured nominal pressure at the extend port of an auxiliary valve of a tractor.";
CM_ SG_ 2365468670 AxValve15RetractPortMeasuredFlow "The measured flow through the retract port of an auxiliary valve of a tractor, expressed as a percentage of full flow.  Zero percent indicates no flow, 100% indicates maximum flow, -100% indicates maximum flow returning to the tractor through the ...";
CM_ SG_ 2365468670 AuxValve15ExtendPortMeasuredFlow "The measured flow through the extend port of an auxiliary valve of a tractor, expressed as a percentage of full flow.  Zero percent indicates no flow, 100% indicates maximum flow, -100% indicates maximum flow returning to the tractor through the ...";
CM_ BO_ 2365468414 "This message provides the measurement of specified auxiliary valve.";
CM_ SG_ 2365468414 AuxValve14ReturnPortPress "The measured nominal pressure at the return port of an auxiliary valve of a tractor.";
CM_ SG_ 2365468414 AuxValve14RetractPortPress "The measured nominal pressure at the retract port of an auxiliary valve of a tractor.";
CM_ SG_ 2365468414 AuxValve14ExtendPortPress "The measured nominal pressure at the extend port of an auxiliary valve of a tractor.";
CM_ SG_ 2365468414 AxValve14RetractPortMeasuredFlow "The measured flow through the retract port of an auxiliary valve of a tractor, expressed as a percentage of full flow.  Zero percent indicates no flow, 100% indicates maximum flow, -100% indicates maximum flow returning to the tractor through the ...";
CM_ SG_ 2365468414 AuxValve14ExtendPortMeasuredFlow "The measured flow through the extend port of an auxiliary valve of a tractor, expressed as a percentage of full flow.  Zero percent indicates no flow, 100% indicates maximum flow, -100% indicates maximum flow returning to the tractor through the ...";
CM_ BO_ 2365468158 "This message provides the measurement of specified auxiliary valve.";
CM_ SG_ 2365468158 AuxValve13ReturnPortPress "The measured nominal pressure at the return port of an auxiliary valve of a tractor.";
CM_ SG_ 2365468158 AuxValve13RetractPortPress "The measured nominal pressure at the retract port of an auxiliary valve of a tractor.";
CM_ SG_ 2365468158 AuxValve13ExtendPortPress "The measured nominal pressure at the extend port of an auxiliary valve of a tractor.";
CM_ SG_ 2365468158 AxValve13RetractPortMeasuredFlow "The measured flow through the retract port of an auxiliary valve of a tractor, expressed as a percentage of full flow.  Zero percent indicates no flow, 100% indicates maximum flow, -100% indicates maximum flow returning to the tractor through the ...";
CM_ SG_ 2365468158 AuxValve13ExtendPortMeasuredFlow "The measured flow through the extend port of an auxiliary valve of a tractor, expressed as a percentage of full flow.  Zero percent indicates no flow, 100% indicates maximum flow, -100% indicates maximum flow returning to the tractor through the ...";
CM_ BO_ 2365467902 "This message provides the measurement of specified auxiliary valve.";
CM_ SG_ 2365467902 AuxValve12ReturnPortPress "The measured nominal pressure at the return port of an auxiliary valve of a tractor.";
CM_ SG_ 2365467902 AuxValve12RetractPortPress "The measured nominal pressure at the retract port of an auxiliary valve of a tractor.";
CM_ SG_ 2365467902 AuxValve12ExtendPortPress "The measured nominal pressure at the extend port of an auxiliary valve of a tractor.";
CM_ SG_ 2365467902 AxValve12RetractPortMeasuredFlow "The measured flow through the retract port of an auxiliary valve of a tractor, expressed as a percentage of full flow.  Zero percent indicates no flow, 100% indicates maximum flow, -100% indicates maximum flow returning to the tractor through the ...";
CM_ SG_ 2365467902 AuxValve12ExtendPortMeasuredFlow "The measured flow through the extend port of an auxiliary valve of a tractor, expressed as a percentage of full flow.  Zero percent indicates no flow, 100% indicates maximum flow, -100% indicates maximum flow returning to the tractor through the ...";
CM_ BO_ 2365467646 "This message provides the measurement of specified auxiliary valve.";
CM_ SG_ 2365467646 AuxValve11ReturnPortPress "The measured nominal pressure at the return port of an auxiliary valve of a tractor.";
CM_ SG_ 2365467646 AuxValve11RetractPortPress "The measured nominal pressure at the retract port of an auxiliary valve of a tractor.";
CM_ SG_ 2365467646 AuxValve11ExtendPortPress "The measured nominal pressure at the extend port of an auxiliary valve of a tractor.";
CM_ SG_ 2365467646 AxValve11RetractPortMeasuredFlow "The measured flow through the retract port of an auxiliary valve of a tractor, expressed as a percentage of full flow.  Zero percent indicates no flow, 100% indicates maximum flow, -100% indicates maximum flow returning to the tractor through the ...";
CM_ SG_ 2365467646 AuxValve11ExtendPortMeasuredFlow "The measured flow through the extend port of an auxiliary valve of a tractor, expressed as a percentage of full flow.  Zero percent indicates no flow, 100% indicates maximum flow, -100% indicates maximum flow returning to the tractor through the ...";
CM_ BO_ 2365467390 "This message provides the measurement of specified auxiliary valve.";
CM_ SG_ 2365467390 AuxValve10ReturnPortPress "The measured nominal pressure at the return port of an auxiliary valve of a tractor.";
CM_ SG_ 2365467390 AuxValve10RetractPortPress "The measured nominal pressure at the retract port of an auxiliary valve of a tractor.";
CM_ SG_ 2365467390 AuxValve10ExtendPortPress "The measured nominal pressure at the extend port of an auxiliary valve of a tractor.";
CM_ SG_ 2365467390 AxValve10RetractPortMeasuredFlow "The measured flow through the retract port of an auxiliary valve of a tractor, expressed as a percentage of full flow.  Zero percent indicates no flow, 100% indicates maximum flow, -100% indicates maximum flow returning to the tractor through the ...";
CM_ SG_ 2365467390 AuxValve10ExtendPortMeasuredFlow "The measured flow through the extend port of an auxiliary valve of a tractor, expressed as a percentage of full flow.  Zero percent indicates no flow, 100% indicates maximum flow, -100% indicates maximum flow returning to the tractor through the ...";
CM_ BO_ 2365467134 "This message provides the measurement of specified auxiliary valve.";
CM_ SG_ 2365467134 AuxValve9ReturnPortPress "The measured nominal pressure at the return port of an auxiliary valve of a tractor.";
CM_ SG_ 2365467134 AuxValve9RetractPortPress "The measured nominal pressure at the retract port of an auxiliary valve of a tractor.";
CM_ SG_ 2365467134 AuxValve9ExtendPortPress "The measured nominal pressure at the extend port of an auxiliary valve of a tractor.";
CM_ SG_ 2365467134 AuxValve9RetractPortMeasuredFlow "The measured flow through the retract port of an auxiliary valve of a tractor, expressed as a percentage of full flow.  Zero percent indicates no flow, 100% indicates maximum flow, -100% indicates maximum flow returning to the tractor through the ...";
CM_ SG_ 2365467134 AuxValve9ExtendPortMeasuredFlow "The measured flow through the extend port of an auxiliary valve of a tractor, expressed as a percentage of full flow.  Zero percent indicates no flow, 100% indicates maximum flow, -100% indicates maximum flow returning to the tractor through the ...";
CM_ BO_ 2365466878 "This message provides the measurement of specified auxiliary valve.";
CM_ SG_ 2365466878 AuxValve8ReturnPortPress "The measured nominal pressure at the return port of an auxiliary valve of a tractor.";
CM_ SG_ 2365466878 AuxValve8RetractPortPress "The measured nominal pressure at the retract port of an auxiliary valve of a tractor.";
CM_ SG_ 2365466878 AuxValve8ExtendPortPress "The measured nominal pressure at the extend port of an auxiliary valve of a tractor.";
CM_ SG_ 2365466878 AuxValve8RetractPortMeasuredFlow "The measured flow through the retract port of an auxiliary valve of a tractor, expressed as a percentage of full flow.  Zero percent indicates no flow, 100% indicates maximum flow, -100% indicates maximum flow returning to the tractor through the ...";
CM_ SG_ 2365466878 AuxValve8ExtendPortMeasuredFlow "The measured flow through the extend port of an auxiliary valve of a tractor, expressed as a percentage of full flow.  Zero percent indicates no flow, 100% indicates maximum flow, -100% indicates maximum flow returning to the tractor through the ...";
CM_ BO_ 2365466622 "This message provides the measurement of specified auxiliary valve.";
CM_ SG_ 2365466622 AuxValve7ReturnPortPress "The measured nominal pressure at the return port of an auxiliary valve of a tractor.";
CM_ SG_ 2365466622 AuxValve7RetractPortPress "The measured nominal pressure at the retract port of an auxiliary valve of a tractor.";
CM_ SG_ 2365466622 AuxValve7ExtendPortPress "The measured nominal pressure at the extend port of an auxiliary valve of a tractor.";
CM_ SG_ 2365466622 AuxValve7RetractPortMeasuredFlow "The measured flow through the retract port of an auxiliary valve of a tractor, expressed as a percentage of full flow.  Zero percent indicates no flow, 100% indicates maximum flow, -100% indicates maximum flow returning to the tractor through the ...";
CM_ SG_ 2365466622 AuxValve7ExtendPortMeasuredFlow "The measured flow through the extend port of an auxiliary valve of a tractor, expressed as a percentage of full flow.  Zero percent indicates no flow, 100% indicates maximum flow, -100% indicates maximum flow returning to the tractor through the ...";
CM_ BO_ 2365466366 "This message provides the measurement of specified auxiliary valve.";
CM_ SG_ 2365466366 AuxValve6ReturnPortPress "The measured nominal pressure at the return port of an auxiliary valve of a tractor.";
CM_ SG_ 2365466366 AuxValve6RetractPortPress "The measured nominal pressure at the retract port of an auxiliary valve of a tractor.";
CM_ SG_ 2365466366 AuxValve6ExtendPortPress "The measured nominal pressure at the extend port of an auxiliary valve of a tractor.";
CM_ SG_ 2365466366 AuxValve6RetractPortMeasuredFlow "The measured flow through the retract port of an auxiliary valve of a tractor, expressed as a percentage of full flow.  Zero percent indicates no flow, 100% indicates maximum flow, -100% indicates maximum flow returning to the tractor through the ...";
CM_ SG_ 2365466366 AuxValve6ExtendPortMeasuredFlow "The measured flow through the extend port of an auxiliary valve of a tractor, expressed as a percentage of full flow.  Zero percent indicates no flow, 100% indicates maximum flow, -100% indicates maximum flow returning to the tractor through the ...";
CM_ BO_ 2365466110 "This message provides the measurement of specified auxiliary valve.";
CM_ SG_ 2365466110 AuxValve5ReturnPortPress "The measured nominal pressure at the return port of an auxiliary valve of a tractor.";
CM_ SG_ 2365466110 AuxValve5RetractPortPress "The measured nominal pressure at the retract port of an auxiliary valve of a tractor.";
CM_ SG_ 2365466110 AuxValve5ExtendPortPress "The measured nominal pressure at the extend port of an auxiliary valve of a tractor.";
CM_ SG_ 2365466110 AuxValve5RetractPortMeasuredFlow "The measured flow through the retract port of an auxiliary valve of a tractor, expressed as a percentage of full flow.  Zero percent indicates no flow, 100% indicates maximum flow, -100% indicates maximum flow returning to the tractor through the ...";
CM_ SG_ 2365466110 AuxValve5ExtendPortMeasuredFlow "The measured flow through the extend port of an auxiliary valve of a tractor, expressed as a percentage of full flow.  Zero percent indicates no flow, 100% indicates maximum flow, -100% indicates maximum flow returning to the tractor through the ...";
CM_ BO_ 2365465854 "This message provides the measurement of specified auxiliary valve.";
CM_ SG_ 2365465854 AuxValve4ReturnPortPress "The measured nominal pressure at the return port of an auxiliary valve of a tractor.";
CM_ SG_ 2365465854 AuxValve4RetractPortPress "The measured nominal pressure at the retract port of an auxiliary valve of a tractor.";
CM_ SG_ 2365465854 AuxValve4ExtendPortPress "The measured nominal pressure at the extend port of an auxiliary valve of a tractor.";
CM_ SG_ 2365465854 AuxValve4RetractPortMeasuredFlow "The measured flow through the retract port of an auxiliary valve of a tractor, expressed as a percentage of full flow.  Zero percent indicates no flow, 100% indicates maximum flow, -100% indicates maximum flow returning to the tractor through the ...";
CM_ SG_ 2365465854 AuxValve4ExtendPortMeasuredFlow "The measured flow through the extend port of an auxiliary valve of a tractor, expressed as a percentage of full flow.  Zero percent indicates no flow, 100% indicates maximum flow, -100% indicates maximum flow returning to the tractor through the ...";
CM_ BO_ 2365465598 "This message provides the measurement of specified auxiliary valve.";
CM_ SG_ 2365465598 AuxValve3ReturnPortPress "The measured nominal pressure at the return port of an auxiliary valve of a tractor.";
CM_ SG_ 2365465598 AuxValve3RetractPortPress "The measured nominal pressure at the retract port of an auxiliary valve of a tractor.";
CM_ SG_ 2365465598 AuxValve3ExtendPortPress "The measured nominal pressure at the extend port of an auxiliary valve of a tractor.";
CM_ SG_ 2365465598 AuxValve3RetractPortMeasuredFlow "The measured flow through the retract port of an auxiliary valve of a tractor, expressed as a percentage of full flow.  Zero percent indicates no flow, 100% indicates maximum flow, -100% indicates maximum flow returning to the tractor through the ...";
CM_ SG_ 2365465598 AuxValve3ExtendPortMeasuredFlow "The measured flow through the extend port of an auxiliary valve of a tractor, expressed as a percentage of full flow.  Zero percent indicates no flow, 100% indicates maximum flow, -100% indicates maximum flow returning to the tractor through the ...";
CM_ BO_ 2365465342 "This message provides the measurement of specified auxiliary valve.";
CM_ SG_ 2365465342 AuxValve2ReturnPortPress "The measured nominal pressure at the return port of an auxiliary valve of a tractor.";
CM_ SG_ 2365465342 AuxValve2RetractPortPress "The measured nominal pressure at the retract port of an auxiliary valve of a tractor.";
CM_ SG_ 2365465342 AuxValve2ExtendPortPress "The measured nominal pressure at the extend port of an auxiliary valve of a tractor.";
CM_ SG_ 2365465342 AuxValve2RetractPortMeasuredFlow "The measured flow through the retract port of an auxiliary valve of a tractor, expressed as a percentage of full flow.  Zero percent indicates no flow, 100% indicates maximum flow, -100% indicates maximum flow returning to the tractor through the ...";
CM_ SG_ 2365465342 AuxValve2ExtendPortMeasuredFlow "The measured flow through the extend port of an auxiliary valve of a tractor, expressed as a percentage of full flow.  Zero percent indicates no flow, 100% indicates maximum flow, -100% indicates maximum flow returning to the tractor through the ...";
CM_ BO_ 2365465086 "This message provides the measurement of specified auxiliary valve.";
CM_ SG_ 2365465086 AuxValve1ReturnPortPress "The measured nominal pressure at the return port of an auxiliary valve of a tractor.";
CM_ SG_ 2365465086 AuxValve1RetractPortPress "The measured nominal pressure at the retract port of an auxiliary valve of a tractor.";
CM_ SG_ 2365465086 AuxValve1ExtendPortPress "The measured nominal pressure at the extend port of an auxiliary valve of a tractor.";
CM_ SG_ 2365465086 AuxValve1RetractPortMeasuredFlow "The measured flow through the retract port of an auxiliary valve of a tractor, expressed as a percentage of full flow.  Zero percent indicates no flow, 100% indicates maximum flow, -100% indicates maximum flow returning to the tractor through the ...";
CM_ SG_ 2365465086 AuxValve1ExtendPortMeasuredFlow "The measured flow through the extend port of an auxiliary valve of a tractor, expressed as a percentage of full flow.  Zero percent indicates no flow, 100% indicates maximum flow, -100% indicates maximum flow returning to the tractor through the ...";
CM_ BO_ 2365464830 "This message provides the measurement of specified auxiliary valve.";
CM_ SG_ 2365464830 AuxValve0ReturnPortPress "The measured nominal pressure at the return port of an auxiliary valve of a tractor.";
CM_ SG_ 2365464830 AuxValve0RetractPortPress "The measured nominal pressure at the retract port of an auxiliary valve of a tractor.";
CM_ SG_ 2365464830 AuxValve0ExtendPortPress "The measured nominal pressure at the extend port of an auxiliary valve of a tractor.";
CM_ SG_ 2365464830 AuxValve0RetractPortMeasuredFlow "The measured flow through the retract port of an auxiliary valve of a tractor, expressed as a percentage of full flow.  Zero percent indicates no flow, 100% indicates maximum flow, -100% indicates maximum flow returning to the tractor through the ...";
CM_ SG_ 2365464830 AuxValve0ExtendPortMeasuredFlow "The measured flow through the extend port of an auxiliary valve of a tractor, expressed as a percentage of full flow.  Zero percent indicates no flow, 100% indicates maximum flow, -100% indicates maximum flow returning to the tractor through the ...";
CM_ BO_ 2365464574 "This message provides the estimated flow of specified auxiliary valve.";
CM_ SG_ 2365464574 AuxValve15Exit_reasonCode "This parameter indicates why the Auxiliary Valve 15 cannot accept remote commands or has most recently stopped accepting remote commands.
0-No reason/all clear
1-Operator presence not detected
2-Implement released control of function
3-Operator ...";
CM_ SG_ 2365464574 AuxValve15FailSafeMode "The measured state the fail safe mode of an auxiliary valve.

00 Block
01 Float
10 Error
11 Not available";
CM_ SG_ 2365464574 AuxValve15State "The measured state of the auxiliary valve.   With float enabled, hydraulic fluid may flow to or from the tractor as driven by the implement.

0000 Blocked
0001 Extend
0010 Retract
0011 Floating
0100-1110 Reserved
1111 Don’t Care";
CM_ SG_ 2365464574 AuxValve15RetractPortEstFlow "The value reported by the controller of flow through the retract port of an auxiliary valve of a tractor which could be based on the commanded position of the valve.  Zero percent indicates no flow, 100%, maximum flow, -100% maximum flow returning ...";
CM_ SG_ 2365464574 AuxValve15ExtendPortEstFlow "The value reported by the controller of flow through the extend port of an auxiliary valve of a tractor which could be based on the commanded position of the valve.  Zero percent indicates no flow, 100%, maximum flow, -100% maximum flow returning to ...";
CM_ BO_ 2365464318 "This message provides the estimated flow of specified auxiliary valve.";
CM_ SG_ 2365464318 AuxValve14Exit_reasonCode "This parameter indicates why the Auxiliary Valve 14 cannot accept remote commands or has most recently stopped accepting remote commands.
0-No reason/all clear
1-Operator presence not detected
2-Implement released control of function
3-Operator ...";
CM_ SG_ 2365464318 AuxValve14FailSafeMode "The measured state the fail safe mode of an auxiliary valve.

00 Block
01 Float
10 Error indication
11 Not available";
CM_ SG_ 2365464318 AuxValve14State "The measured state of the auxiliary valve.   With float enabled, hydraulic fluid may flow to or from the tractor as driven by the implement.

0000 Blocked
0001 Extend
0010 Retract
0011 Floating
0100-1110 Reserved
1111 Don’t Care";
CM_ SG_ 2365464318 AuxValve14RetractPortEstFlow "The value reported by the controller of flow through the retract port of an auxiliary valve of a tractor which could be based on the commanded position of the valve.  Zero percent indicates no flow, 100%, maximum flow, -100% maximum flow returning ...";
CM_ SG_ 2365464318 AuxValve14ExtendPortEstFlow "The value reported by the controller of flow through the extend port of an auxiliary valve of a tractor which could be based on the commanded position of the valve.  Zero percent indicates no flow, 100%, maximum flow, -100% maximum flow returning to ...";
CM_ BO_ 2365464062 "This message provides the estimated flow of specified auxiliary valve.";
CM_ SG_ 2365464062 AuxValve13Exit_reasonCode "This parameter indicates why the Auxiliary Valve 13 cannot accept remote commands or has most recently stopped accepting remote commands.
0-No reason/all clear
1-Operator presence not detected
2-Implement released control of function
3-Operator ...";
CM_ SG_ 2365464062 AuxValve13FailSafeMode "The measured state the fail safe mode of an auxiliary valve.

00 Block
01 Float
10 Error indication
11 Not available";
CM_ SG_ 2365464062 AuxValve13State "The measured state of the auxiliary valve.   With float enabled, hydraulic fluid may flow to or from the tractor as driven by the implement.

0000 Blocked
0001 Extend
0010 Retract
0011 Floating
0100-1110 Reserved
1111 Don’t Care";
CM_ SG_ 2365464062 AuxValve13RetractPortEstFlow "The value reported by the controller of flow through the retract port of an auxiliary valve of a tractor which could be based on the commanded position of the valve.  Zero percent indicates no flow, 100%, maximum flow, -100% maximum flow returning ...";
CM_ SG_ 2365464062 AuxValve13ExtendPortEstFlow "The value reported by the controller of flow through the extend port of an auxiliary valve of a tractor which could be based on the commanded position of the valve.  Zero percent indicates no flow, 100%, maximum flow, -100% maximum flow returning to ...";
CM_ BO_ 2365463806 "This message provides the estimated flow of specified auxiliary valve.";
CM_ SG_ 2365463806 AuxValve12Exit_reasonCode "This parameter indicates why the Auxiliary Valve 12 cannot accept remote commands or has most recently stopped accepting remote commands.
0-No reason/all clear
1-Operator presence not detected
2-Implement released control of function
3-Operator ...";
CM_ SG_ 2365463806 AuxValve12FailSafeMode "The measured state the fail safe mode of an auxiliary valve.

00 Block
01 Float
10 Error indication
11 Not available";
CM_ SG_ 2365463806 AuxValve12State "The measured state of the auxiliary valve.   With float enabled, hydraulic fluid may flow to or from the tractor as driven by the implement.

0000 Blocked
0001 Extend
0010 Retract
0011 Floating
0100-1110 Reserved
1111 Don’t Care";
CM_ SG_ 2365463806 AuxValve12RetractPortEstFlow "The value reported by the controller of flow through the retract port of an auxiliary valve of a tractor which could be based on the commanded position of the valve.  Zero percent indicates no flow, 100%, maximum flow, -100% maximum flow returning ...";
CM_ SG_ 2365463806 AuxValve12ExtendPortEstFlow "The value reported by the controller of flow through the extend port of an auxiliary valve of a tractor which could be based on the commanded position of the valve.  Zero percent indicates no flow, 100%, maximum flow, -100% maximum flow returning to ...";
CM_ BO_ 2365463550 "This message provides the estimated flow of specified auxiliary valve.";
CM_ SG_ 2365463550 AuxValve11Exit_reasonCode "This parameter indicates why the Auxiliary Valve 11 cannot accept remote commands or has most recently stopped accepting remote commands.
0-No reason/all clear
1-Operator presence not detected
2-Implement released control of function
3-Operator ...";
CM_ SG_ 2365463550 AuxValve11FailSafeMode "The measured state the fail safe mode of an auxiliary valve.

00 Block
01 Float
10 Error indication
11 Not available";
CM_ SG_ 2365463550 AuxValve11State "The measured state of the auxiliary valve.   With float enabled, hydraulic fluid may flow to or from the tractor as driven by the implement.

0000 Blocked
0001 Extend
0010 Retract
0011 Floating
0100-1110 Reserved
1111 Don’t Care";
CM_ SG_ 2365463550 AuxValve11RetractPortEstFlow "The value reported by the controller of flow through the retract port of an auxiliary valve of a tractor which could be based on the commanded position of the valve.  Zero percent indicates no flow, 100%, maximum flow, -100% maximum flow returning ...";
CM_ SG_ 2365463550 AuxValve11ExtendPortEstFlow "The value reported by the controller of flow through the extend port of an auxiliary valve of a tractor which could be based on the commanded position of the valve.  Zero percent indicates no flow, 100%, maximum flow, -100% maximum flow returning to ...";
CM_ BO_ 2365463294 "This message provides the estimated flow of specified auxiliary valve.";
CM_ SG_ 2365463294 AuxValve10Exit_reasonCode "This parameter indicates why the Auxiliary Valve 10 cannot accept remote commands or has most recently stopped accepting remote commands.
0-No reason/all clear
1-Operator presence not detected
2-Implement released control of function
3-Operator ...";
CM_ SG_ 2365463294 AuxValve10FailSafeMode "The measured state the fail safe mode of an auxiliary valve.

00 Block
01 Float
10 Error indication
11 Not available";
CM_ SG_ 2365463294 AuxValve10State "The measured state of the auxiliary valve.   With float enabled, hydraulic fluid may flow to or from the tractor as driven by the implement.

0000 Blocked
0001 Extend
0010 Retract
0011 Floating
0100-1110 Reserved
1111 Don’t Care";
CM_ SG_ 2365463294 AuxValve10RetractPortEstFlow "The value reported by the controller of flow through the retract port of an auxiliary valve of a tractor which could be based on the commanded position of the valve.  Zero percent indicates no flow, 100%, maximum flow, -100% maximum flow returning ...";
CM_ SG_ 2365463294 AuxValve10ExtendPortEstFlow "The value reported by the controller of flow through the extend port of an auxiliary valve of a tractor which could be based on the commanded position of the valve.  Zero percent indicates no flow, 100%, maximum flow, -100% maximum flow returning to ...";
CM_ BO_ 2365463038 "This message provides the estimated flow of specified auxiliary valve.";
CM_ SG_ 2365463038 AuxValve9Exit_reasonCode "This parameter indicates why the Auxiliary Valve 9 cannot accept remote commands or has most recently stopped accepting remote commands.
0-No reason/all clear
1-Operator presence not detected
2-Implement released control of function
3-Operator ...";
CM_ SG_ 2365463038 AuxValve9FailSafeMode "The measured state the fail safe mode of an auxiliary valve.

00 Block
01 Float
10 Error indication
11 Not available";
CM_ SG_ 2365463038 AuxValve9State "The measured state of the auxiliary valve.   With float enabled, hydraulic fluid may flow to or from the tractor as driven by the implement.

0000 Blocked
0001 Extend
0010 Retract
0011 Floating
0100-1110 Reserved
1111 Don’t Care";
CM_ SG_ 2365463038 AuxValve9RetractPortEstFlow "The value reported by the controller of flow through the retract port of an auxiliary valve of a tractor which could be based on the commanded position of the valve.  Zero percent indicates no flow, 100%, maximum flow, -100% maximum flow returning ...";
CM_ SG_ 2365463038 AuxValve9ExtendPortEstFlow "The value reported by the controller of flow through the extend port of an auxiliary valve of a tractor which could be based on the commanded position of the valve.  Zero percent indicates no flow, 100%, maximum flow, -100% maximum flow returning to ...";
CM_ BO_ 2365462782 "This message provides the estimated flow of specified auxiliary valve.";
CM_ SG_ 2365462782 AuxValve8Exit_reasonCode "This parameter indicates why the Auxiliary Valve 8 cannot accept remote commands or has most recently stopped accepting remote commands.
0-No reason/all clear
1-Operator presence not detected
2-Implement released control of function
3-Operator ...";
CM_ SG_ 2365462782 AuxValve8FailSafeMode "The measured state the fail safe mode of an auxiliary valve.

00 Block
01 Float
10 Error indication
11 Not available";
CM_ SG_ 2365462782 AuxValve8State "The measured state of the auxiliary valve.   With float enabled, hydraulic fluid may flow to or from the tractor as driven by the implement.

0000 Blocked
0001 Extend
0010 Retract
0011 Floating
0100-1110 Reserved
1111 Don’t Care";
CM_ SG_ 2365462782 AuxValve8RetractPortEstFlow "The value reported by the controller of flow through the retract port of an auxiliary valve of a tractor which could be based on the commanded position of the valve.  Zero percent indicates no flow, 100%, maximum flow, -100% maximum flow returning ...";
CM_ SG_ 2365462782 AuxValve8ExtendPortEstFlow "The value reported by the controller of flow through the extend port of an auxiliary valve of a tractor which could be based on the commanded position of the valve.  Zero percent indicates no flow, 100%, maximum flow, -100% maximum flow returning to ...";
CM_ BO_ 2365462526 "This message provides the estimated flow of specified auxiliary valve.";
CM_ SG_ 2365462526 AuxValve7Exit_reasonCode "This parameter indicates why the Auxiliary Valve 7 cannot accept remote commands or has most recently stopped accepting remote commands.
0-No reason/all clear
1-Operator presence not detected
2-Implement released control of function
3-Operator ...";
CM_ SG_ 2365462526 AuxValve7FailSafeMode "The measured state the fail safe mode of an auxiliary valve.

00 Block
01 Float
10 Error indication
11 Not available";
CM_ SG_ 2365462526 AuxValve7State "The measured state of the auxiliary valve.   With float enabled, hydraulic fluid may flow to or from the tractor as driven by the implement.

0000 Blocked
0001 Extend
0010 Retract
0011 Floating
0100-1110 Reserved
1111 Don’t Care";
CM_ SG_ 2365462526 AuxValve7RetractPortEstFlow "The value reported by the controller of flow through the retract port of an auxiliary valve of a tractor which could be based on the commanded position of the valve.  Zero percent indicates no flow, 100%, maximum flow, -100% maximum flow returning ...";
CM_ SG_ 2365462526 AuxValve7ExtendPortEstFlow "The value reported by the controller of flow through the extend port of an auxiliary valve of a tractor which could be based on the commanded position of the valve.  Zero percent indicates no flow, 100%, maximum flow, -100% maximum flow returning to ...";
CM_ BO_ 2365462270 "This message provides the estimated flow of specified auxiliary valve.";
CM_ SG_ 2365462270 AuxValve6Exit_reasonCode "This parameter indicates why the Auxiliary Valve 6 cannot accept remote commands or has most recently stopped accepting remote commands.
0-No reason/all clear
1-Operator presence not detected
2-Implement released control of function
3-Operator ...";
CM_ SG_ 2365462270 AuxValve6FailSafeMode "The measured state the fail safe mode of an auxiliary valve.

00 Block
01 Float
10 Error indication
11 Not available";
CM_ SG_ 2365462270 AuxValve6State "The measured state of the auxiliary valve.   With float enabled, hydraulic fluid may flow to or from the tractor as driven by the implement.

0000 Blocked
0001 Extend
0010 Retract
0011 Floating
0100-1110 Reserved
1111 Don’t Care";
CM_ SG_ 2365462270 AuxValve6RetractPortEstFlow "The value reported by the controller of flow through the retract port of an auxiliary valve of a tractor which could be based on the commanded position of the valve.  Zero percent indicates no flow, 100%, maximum flow, -100% maximum flow returning ...";
CM_ SG_ 2365462270 AuxValve6ExtendPortEstFlow "The value reported by the controller of flow through the extend port of an auxiliary valve of a tractor which could be based on the commanded position of the valve.  Zero percent indicates no flow, 100%, maximum flow, -100% maximum flow returning to ...";
CM_ BO_ 2365462014 "This message provides the estimated flow of specified auxiliary valve.";
CM_ SG_ 2365462014 AuxValve5Exit_reasonCode "This parameter indicates why the Auxiliary Valve 5 cannot accept remote commands or has most recently stopped accepting remote commands.
0-No reason/all clear
1-Operator presence not detected
2-Implement released control of function
3-Operator ...";
CM_ SG_ 2365462014 AuxValve5FailSafeMode "The measured state the fail safe mode of an auxiliary valve.

00 Block
01 Float
10 Error indication
11 Not available";
CM_ SG_ 2365462014 AuxValve5State "The measured state of the auxiliary valve.   With float enabled, hydraulic fluid may flow to or from the tractor as driven by the implement.

0000 Blocked
0001 Extend
0010 Retract
0011 Floating
0100-1110 Reserved
1111 Don’t Care";
CM_ SG_ 2365462014 AuxValve5RetractPortEstFlow "The value reported by the controller of flow through the retract port of an auxiliary valve of a tractor which could be based on the commanded position of the valve.  Zero percent indicates no flow, 100%, maximum flow, -100% maximum flow returning ...";
CM_ SG_ 2365462014 AuxValve5ExtendPortEstFlow "The value reported by the controller of flow through the extend port of an auxiliary valve of a tractor which could be based on the commanded position of the valve.  Zero percent indicates no flow, 100%, maximum flow, -100% maximum flow returning to ...";
CM_ BO_ 2365461758 "This message provides the estimated flow of specified auxiliary valve.";
CM_ SG_ 2365461758 AuxValve4Exit_reasonCode "This parameter indicates why the Auxiliary Valve 4 cannot accept remote commands or has most recently stopped accepting remote commands.
0-No reason/all clear
1-Operator presence not detected
2-Implement released control of function
3-Operator ...";
CM_ SG_ 2365461758 AuxValve4FailSafeMode "The measured state the fail safe mode of an auxiliary valve.

00 Block
01 Float
10 Error indication
11 Not available";
CM_ SG_ 2365461758 AuxValve4State "The measured state of the auxiliary valve.   With float enabled, hydraulic fluid may flow to or from the tractor as driven by the implement.

0000 Blocked
0001 Extend
0010 Retract
0011 Floating
0100-1110 Reserved
1111 Don’t Care";
CM_ SG_ 2365461758 AuxValve4RetractPortEstFlow "The value reported by the controller of flow through the retract port of an auxiliary valve of a tractor which could be based on the commanded position of the valve.  Zero percent indicates no flow, 100%, maximum flow, -100% maximum flow returning ...";
CM_ SG_ 2365461758 AuxValve4ExtendPortEstFlow "The value reported by the controller of flow through the extend port of an auxiliary valve of a tractor which could be based on the commanded position of the valve.  Zero percent indicates no flow, 100%, maximum flow, -100% maximum flow returning to ...";
CM_ BO_ 2365461502 "This message provides the estimated flow of specified auxiliary valve.";
CM_ SG_ 2365461502 AuxValve3Exit_reasonCode "This parameter indicates why the Auxiliary Valve 3 cannot accept remote commands or has most recently stopped accepting remote commands.
0-No reason/all clear
1-Operator presence not detected
2-Implement released control of function
3-Operator ...";
CM_ SG_ 2365461502 AuxValve3FailSafeMode "The measured state the fail safe mode of an auxiliary valve.

00 Block
01 Float
10 Error indication
11 Not available";
CM_ SG_ 2365461502 AuxValve3State "The measured state of the auxiliary valve.   With float enabled, hydraulic fluid may flow to or from the tractor as driven by the implement.

0000 Blocked
0001 Extend
0010 Retract
0011 Floating
0100-1110 Reserved
1111 Don’t Care";
CM_ SG_ 2365461502 AuxValve3RetractPortEstFlow "The value reported by the controller of flow through the retract port of an auxiliary valve of a tractor which could be based on the commanded position of the valve.  Zero percent indicates no flow, 100%, maximum flow, -100% maximum flow returning ...";
CM_ SG_ 2365461502 AuxValve3ExtendPortEstFlow "The value reported by the controller of flow through the extend port of an auxiliary valve of a tractor which could be based on the commanded position of the valve.  Zero percent indicates no flow, 100%, maximum flow, -100% maximum flow returning to ...";
CM_ BO_ 2365461246 "This message provides the estimated flow of specified auxiliary valve.";
CM_ SG_ 2365461246 AuxValve2Exit_reasonCode "This parameter indicates why the Auxiliary Valve 2 cannot accept remote commands or has most recently stopped accepting remote commands.
0-No reason/all clear
1-Operator presence not detected
2-Implement released control of function
3-Operator ...";
CM_ SG_ 2365461246 AuxValve2FailSafeMode "The measured state the fail safe mode of an auxiliary valve.

00 Block
01 Float
10 Error indication
11 Not available";
CM_ SG_ 2365461246 AuxValve2State "The measured state of the auxiliary valve.   With float enabled, hydraulic fluid may flow to or from the tractor as driven by the implement.

0000 Blocked
0001 Extend
0010 Retract
0011 Floating
0100-1110 Reserved
1111 Don’t Care";
CM_ SG_ 2365461246 AuxValve2RetractPortEstFlow "The value reported by the controller of flow through the retract port of an auxiliary valve of a tractor which could be based on the commanded position of the valve.  Zero percent indicates no flow, 100%, maximum flow, -100% maximum flow returning ...";
CM_ SG_ 2365461246 AuxValve2ExtendPortEstFlow "The value reported by the controller of flow through the extend port of an auxiliary valve of a tractor which could be based on the commanded position of the valve.  Zero percent indicates no flow, 100%, maximum flow, -100% maximum flow returning to ...";
CM_ BO_ 2365460990 "This message provides the estimated flow of specified auxiliary valve.";
CM_ SG_ 2365460990 AuxValve1Exit_reasonCode "This parameter indicates why the Auxiliary Valve 1 cannot accept remote commands or has most recently stopped accepting remote commands.
0-No reason/all clear
1-Operator presence not detected
2-Implement released control of function
3-Operator ...";
CM_ SG_ 2365460990 AuxValve1FailSafeMode "The measured state the fail safe mode of an auxiliary valve.

00 Block
01 Float
10 Error indication
11 Not available";
CM_ SG_ 2365460990 AuxValve1State "The measured state of the auxiliary valve.   With float enabled, hydraulic fluid may flow to or from the tractor as driven by the implement.

0000 Blocked
0001 Extend
0010 Retract
0011 Floating
0100-1110 Reserved
1111 Don’t Care";
CM_ SG_ 2365460990 AuxValve1RetractPortEstFlow "The value reported by the controller of flow through the retract port of an auxiliary valve of a tractor which could be based on the commanded position of the valve.  Zero percent indicates no flow, 100%, maximum flow, -100% maximum flow returning ...";
CM_ SG_ 2365460990 AuxValve1ExtendPortEstFlow "The value reported by the controller of flow through the extend port of an auxiliary valve of a tractor which could be based on the commanded position of the valve.  Zero percent indicates no flow, 100%, maximum flow, -100% maximum flow returning to ...";
CM_ BO_ 2365460734 "This message provides the estimated flow of specified auxiliary valve.";
CM_ SG_ 2365460734 AuxValve0Exit_reasonCode "This parameter indicates why the Auxiliary Valve 0 cannot accept remote commands or has most recently stopped accepting remote commands.
0-No reason/all clear
1-Operator presence not detected
2-Implement released control of function
3-Operator ...";
CM_ SG_ 2365460734 AuxValve0FailSafeMode "The measured state the fail safe mode of an auxiliary valve.

00 Block
01 Float
10 Error indication
11 Not available";
CM_ SG_ 2365460734 AuxValve0State "The measured state of the auxiliary valve.   With float enabled, hydraulic fluid may flow to or from the tractor as driven by the implement.

0000 Blocked
0001 Extend
0010 Retract
0011 Floating
0100-1110 Reserved
1111 Don’t Care";
CM_ SG_ 2365460734 AuxValve0RetractPortEstFlow "The value reported by the controller of flow through the retract port of an auxiliary valve of a tractor which could be based on the commanded position of the valve.  Zero percent indicates no flow, 100%, maximum flow, -100% maximum flow returning ...";
CM_ SG_ 2365460734 AuxValve0ExtendPortEstFlow "The value reported by the controller of flow through the extend port of an auxiliary valve of a tractor which could be based on the commanded position of the valve.  Zero percent indicates no flow, 100%, maximum flow, -100% maximum flow returning to ...";
CM_ BO_ 2365460478 "The language message has been defined as a global message to inform all ECUs on the 11783 bus the language that the operator wants to use, the date and time format and the units of measure with which the connected system should work.";
CM_ SG_ 2365460478 DistanceUnitCmd "Command to specify the distance units

00 Metric (km, m, …)
01 Imperial (miles, feet, ..)
10 Reserved
11 No action";
CM_ SG_ 2365460478 AreaUnitCmd "Command to specify the area units

00 Metric (ha or m2)
01 Imperial (acres or feet2)
10 Reserved
11 No action";
CM_ SG_ 2365460478 VolumeUnitCmd "Command to specify the volume units

00 Metric (litre)
01 Imperial (gallon)
10 US (gallon)
11 No action";
CM_ SG_ 2365460478 MassUnitCmd "Command to specify the mass units

00 Metric (tonne, kg, …)
01 Imperial (long tons-UK, pounds, ….)
10 Tons/pounds (short tons-US, pounds, …)
11 No action";
CM_ SG_ 2365460478 DateCmd "Command sent to all ECUs which specifies the displayed order of the date.

0 ddmmyyyy
1 ddyyyymm
2 mmyyyydd
3 mmddyyyy
4 yyyymmdd
5 yyyyddmm
6-255 Reserved";
CM_ SG_ 2365460478 DecimalSymbolCmd "Command sent to all ECUs which specifies that a decimal point or Comma should be displayed.

00 Comma is used
01 Point is used
10 Reserved
11 No action";
CM_ SG_ 2365460478 TimeCmd "Command sent to all ECUs which specifies the displayed format of the time

00 24 hour
01 12 hour (am/ pm)
10 Reserved
11 No action";
CM_ SG_ 2365460478 LanguageCodeCmd "Command sent to all ECUs which specifies the operator’s desired language of information.  ISO 11783 shall use the 2-character string country codes in ISO 639.  Typical examples from ISO 639 are: 

Dutch: nl
French: fr
English: en
German: de";
CM_ BO_ 2365460222 "This global message is the response of the request of a specific user to change the repetition rate.";
CM_ SG_ 2365460222 DataDictionaryRow "This 4 bit parameter indicates the Row that is to be used within the specific Data Dictionary Table identified by the Implement Type. This is the Group (GRUP) in LBS documents.";
CM_ SG_ 2365460222 DataDictionaryColumn "This 4 bit parameter indicates the Column that is to be used within the specific Data Dictionary Table identified by the Implement Type. This is the Instance (INST) in LBS documents.";
CM_ SG_ 2365460222 ImplementType "This 4 bit parameter indicates which data dictionary page is to be used to locate the identity of the following data.";
CM_ SG_ 2365460222 ImplementPos "This 4 bit parameter of this message will indicate which Implement is referenced within a set of identical Implements.  The numbering is to start with 1 at the leftmost, foremost, bottom most implement.  The numbering will then increment from left ...";
CM_ SG_ 2365460222 DataFormat_ErrorCondition "This 2 bit parameter that indicates the format or availability of the data in the following Process Data Parameter.
00 Data format is Long Integer
01 Data format is Floating
10 Data format is unsigned Long Integer
11 Not Available or error
Data ...";
CM_ SG_ 2365460222 ProcessDataType "This 2 bit parameter indicates what the data in the following Process Data Parameters is to be used for. See Table A.2.
00 Data is Set Point
01 Data is Actual values
10 Message is Set Point request
11 Message is Actual value request
Data is Set ...";
CM_ SG_ 2365460222 ProcessDataModifier "This 3 bit parameter that indicates how the data in the following Process Data Parameters is to be used when combined with the Process Data Type parameter. See Table A.2.

NOTE: Process Data Type is included since MOD is a function of PD";
CM_ SG_ 2365460222 RepetitionRateParameter "This parameter defines the repetition rate of the specified PGN.";
CM_ BO_ 2365459454 "This command is a task controller or an implement ECU to tractor ECU message.";
CM_ BO_ 2365459198 "This command is a task controller or an implement ECU to tractor ECU message.";
CM_ BO_ 2365458942 "Tractor response to an implement ECU or task controller tractor classification and facilities request";
CM_ SG_ 2365458942 TrctrFcltyRspLmt_RqstSttsRprting "Indicates whether the vehicle supports reporting of the limit status and request status parameters in the tractor’s supported status messages.

0   Limit/request status reporting not available
1   Limit/request status reporting available";
CM_ BO_ 2365458686 "Implement response to task controller or Tractor ECU desired tractor classification and facilities";
CM_ SG_ 2365458686 TrctrFcltyRqLmt_RqstSttsRporting "Indicates whether the requester requires reporting of the limit status and request status parameters in the tractor’s supported status messages.

0  Limit/request status reporting not required
1  Limit/request status reporting required";
CM_ BO_ 2365447934 "Message to transmit data of the towed vehicle to the towing vehicle. See ISO 11992-3.";
CM_ BO_ 2365447678 "Message to transmit data of the towing vehicle to the towed vehicle. See ISO 11992-3.";
CM_ BO_ 2365444094 "Message sent by the Master of a Working Set to identify how many members  there are  in said set.";
CM_ BO_ 2365443838 "Message sent by the Master of a Working Set to identify an individual member of a specific Working Set.";
CM_ SG_ 2365443838 NAMEOfWorkingSetMember "NAME of Working Set Member

The identifier of the particular CA that is a member of the Working Set identified by the source address of this message.  This parameter is a NAME with the format described in 4.1.1.";
CM_ BO_ 2365434878 "This message is designed to cause all CAs to respond with the complete sequence of configuration identification messages for a particular one or all of the configurable messages that they send.";
CM_ SG_ 2365434878 PGNOfConfigurableMessageDesired "To identify the configurable message whose configuration is being requested. If the request is for all configurable PGNs then this SPN is set to all ones.";
CM_ SG_ 2365434878 MessageSelectionCtrl "Used to identify all configurable messages.";
CM_ BO_ 2566754814 "This contains parameters indicating the status of various breakers throughout a power generation system.  These include: Generator Circuit Breaker Status, Utility Circuit Breaker Status, and Automatic Transfer Switch status.";
CM_ SG_ 2566754814 AutomaticTransferSwitchStatus "This parameter indicates the measured state of the automatic transfer switch.
Bit state 000 = Normal position
Bit state 001 = Emergency position
Bit states 010-101 = available for SAE assignment
Bit state 110 = error
Bit state 111 = not ...";
CM_ SG_ 2566754814 UtilityCircuitBreakerStatus "This parameter indicates the measured state of the utility circuit breaker.
Bit state 000 = Open
Bit state 001 = Closed
Bit state 010 = Locked Out
Bit states 011-101 = available for SAE assignment
Bit state 110 = error
Bit state 111 = not ...";
CM_ SG_ 2566754814 GeneratorCircuitBreakerStatus "This parameter indicates the measured state of the generator circuit breaker.
Bit state 000 = Open
Bit state 001 = Closed
Bit state 010 = Locked Out
Bit states 011-101 = available for SAE assignment
Bit state 110 = error
Bit state 111 = not ...";
CM_ BO_ 2566754302 "This PGN contains quantities for the instantaneous AC power from the generator, as percentages of rated power";
CM_ SG_ 2566754302 GeneratorTotalPercentKVAr "This parameter reports the generator total AC reactive power, as a percentage of rated power.";
CM_ SG_ 2566754302 GeneratorTotalPercentKVA "This parameter reports the generator total AC apparent power, as a percentage of rated power.";
CM_ SG_ 2566754302 GeneratorTotalPercentKW "This parameter reports the generator total AC power, as a percentage of rated power.";
CM_ BO_ 2566754046 "This PGN contains quantities for the cumulative AC reactive energy from the generator.";
CM_ SG_ 2566754046 GeneratorTotalKVArHoursImport "This parameter reports the cumulative total AC reactive energy imported to the generator.";
CM_ SG_ 2566754046 GeneratorTotalKVArHoursExport "This parameter reports the cumulative total AC reactive energy exported from the generator.";
CM_ BO_ 2566753790 "This PGN contains quantities for the cumulative AC reactive energy from the utility.";
CM_ SG_ 2566753790 UtilityTotalKVArHoursImport "This parameter reports the cumulative total AC reactive energy imported to the utility.";
CM_ SG_ 2566753790 UtilityTotalKVArHoursExport "This parameter reports the cumulative total AC reactive energy exported from the utility.";
CM_ BO_ 2365411582 "Message to transmit data of the towing vehicle to the towed vehicle. See ISO 11992-3.";
CM_ BO_ 2365411326 "Message to transmit data of the towed vehicle to the towing vehicle. See ISO 11992-3.";
CM_ BO_ 2365411070 "Message to transmit data of the towed vehicle to the towing vehicle. See ISO 11992-3.";
CM_ BO_ 2365410814 "Message to transmit data of the towed vehicle to the towing vehicle. See ISO 11992-3.";
CM_ BO_ 2365410558 "Message to transmit data of the towed vehicle to the towing vehicle. See ISO 11992-3.";
CM_ BO_ 2365410302 "Message to transmit data of the towed vehicle to the towing vehicle. See ISO 11992-3.";
CM_ BO_ 2365410046 "Message to transmit data of the towed vehicle to the towing vehicle. See ISO 11992-3.";
CM_ BO_ 2365408254 "Message that provides the control of the machine speed and direction.";
CM_ SG_ 2365408254 MachineSelectedDirectionCmd "Commanded direction of travel of the machine.

00 - Reverse
01 - Forward
10 - Reserved
11 - Don't care, take no action";
CM_ SG_ 2365408254 MchnSelectedSpeedExit_reasonCode "This parameter indicates why the Vehicle Speed control unit cannot currently accept remote commands or has most recently stopped accepting remote commands.
0-No reason/all clear
1-Operator presence not detected
2-Implement released control of ...";
CM_ SG_ 2365408254 MchineSelectedSpeedSetpointLimit "The machine's maximum allowed speed communicated to the tractor.";
CM_ SG_ 2365408254 MachineSelectedSpeedSetpointCmd "Commanded set point value of the machine speed as measured by the selected source.";
CM_ BO_ 2365407998 "This message reports the compliance certification status of a specific electronic control unit.";
CM_ SG_ 2365407998 ISOBUSCmplncCrtfctnMssgeRevision "This parameter distinguishes the format ISOBUS Compliance Certification message in the 2nd edition from the format in the 3rd edition (and later).

0   Format of message in 2nd edition
1   Post-2nd edition message revision";
CM_ SG_ 2365407998 ISOBUSCmplncCrtfctnRfrenceNumber "Certificate reference number assigned by Certification laboratory.  Uniquely identifies the test file from the Certification laboratory when use with the Certification laboratory ID and the ECU manufacturer ID.";
CM_ SG_ 2365407998 ISOBUSCmplncCrtfctonTypeTaskCtrl "Parameter used to indicate the type of compliance test performed.

0    Not certified 
1    Certified";
CM_ SG_ 2365407998 ISOBUSCmplncCrtfctnTypTCWrkn4326 "Parameter used to indicate the type of compliance test performed.

0    Not certified 
1    Certified";
CM_ SG_ 2365407998 ISOBUSCmplncCrtfctnTypTCWrkngStM "Parameter used to indicate the type of compliance test performed.

0    Not certified 
1    Certified";
CM_ SG_ 2365407998 ISOBUSCmplncCrtfctnTypFileServer "Parameter used to indicate the type of compliance test performed.

0    Not certified 
1    Certified";
CM_ SG_ 2365407998 ISOBUSCmplncCrtfctnTypGPSRceiver "Parameter used to indicate the type of compliance test performed.

0    Not certified 
1    Certified";
CM_ SG_ 2365407998 ISOBUSCmplncCrtfcationTypeMinECU "Parameter used to indicate the type of compliance test performed.

0    Not certified 
1    Certified";
CM_ SG_ 2365407998 ISOBUSCmplncCrtfctnTypTECUClass1 "Parameter used to indicate the type of compliance test performed.

0    Not certified 
1    Certified";
CM_ SG_ 2365407998 ISOBUSCmplncCrtfctnTypTECUClass2 "Parameter used to indicate the type of compliance test performed.

0    Not certified 
1    Certified";
CM_ SG_ 2365407998 ISOBUSCmplncCrtfctnTypTECUClass3 "Parameter used to indicate the type of compliance test performed.

0    Not certified 
1    Certified";
CM_ SG_ 2365407998 ISOBUSCmplncCrtfctnTypeClass3ECU "Parameter used to indicate the type of compliance test performed.

0    Not certified 
1    Certified";
CM_ SG_ 2365407998 ISOBUSCmplncCrtfctnTypVrtlTrmnal "Parameter used to indicate the type of compliance test performed.

0    Not certified 
1    Certified";
CM_ SG_ 2365407998 ISOBUSCmplncCrtfctnTypVTWrkn4323 "Parameter used to indicate the type of compliance test performed.

0    Not certified 
1    Certified";
CM_ SG_ 2365407998 ISOBUSCmplncCrtfctnTypVTWrkngStM "Parameter used to indicate the type of compliance test performed.

0    Not certified 
1    Certified";
CM_ SG_ 2365407998 ISOBUSCmplncCrtfctonLaboratoryID "Manufacturer code of the laboratory that performed the compliance test.  In the case of a self-certified ECU, this matches the manufacturer code contained in the address claim PGN.  See ISO 11783 Part 1 Annex B Table B6.";
CM_ SG_ 2365407998 ISOBUSCmplncCrtfctLaboratoryType "Approving body for the certification laboratory.

000 - Non-certified laboratory/ self certification
001 - EU certified laboratory
010 - NA certified laboratory
011 - 110 - Reserved
111 - Not available (Not certified)";
CM_ SG_ 2365407998 ISOBUSCmplnceCertificateRevision "Revision of the ISOBUS compliance test performed.  In years where there are multiple revisions of the test protocol, an alphabetic suffix is used in addition to the certification year.
000 - First Revision (No Suffix)
001 - Second Revision (Suffix ...";
CM_ SG_ 2365407998 ISOBUSCmplianceCertificationYear "Year of the compliance test protocol to which the certification test was performed.";
CM_ BO_ 2365403902 "The ECU level 1 diagnostic protocol message identifies the diagnostic protocol required by a service tool to troubleshoot a fault.";
CM_ BO_ 2365391870 "Message sent by the tractor ECU on the implement bus on forestry or agriculture implements providing to connected systems the current commanded implement operating state.";
CM_ SG_ 2365391870 ImplementOperatingStateCmd "Command for setting the operating state of a connected implement system.

00  Set implement to field working state
01  Set implement to transport state
10  Set implement to park state
11  Take no action";
BA_DEF_ SG_  "SigType" ENUM  "Default","Range","RangeSigned","ASCII","Discrete","Control","ReferencePGN","DTC","StringDelimiter","StringLength","StringLengthControl","MessageCounter","MessageChecksum";
BA_DEF_ SG_  "GenSigStartValue" INT 0 10000;
BA_DEF_ SG_  "GenSigSendType" ENUM  "Cyclic","OnWrite","OnWriteWithRepetition","OnChange","OnChangeWithRepetition","IfActive","IfActiveWithRepetition","NoSigSendType";
BA_DEF_ SG_  "GenSigILSupport" ENUM  "No","Yes";
BA_DEF_ SG_  "GenSigEVName" STRING ;
BA_DEF_ SG_  "SPN" INT 0 524287;
BA_DEF_ BO_  "TpJ1939VarDlc" ENUM  "No","Yes";
BA_DEF_ BO_  "GenMsgStartDelayTime" INT 0 100000;
BA_DEF_ BO_  "GenMsgILSupport" ENUM  "No","Yes";
BA_DEF_ BO_  "GenMsgDelayTime" INT 0 1000;
BA_DEF_ BO_  "GenMsgRequestable" INT 0 1;
BA_DEF_ BO_  "GenMsgSendType" ENUM  "cyclic","NotUsed","NotUsed","NotUsed","NotUsed","NotUsed","NotUsed","IfActive","noMsgSendType";
BA_DEF_ BO_  "VFrameFormat" ENUM  "StandardCAN","ExtendedCAN","reserved","J1939PG";
BA_DEF_ BO_  "GenMsgCycleTime" INT 0 3600000;
BA_DEF_ SG_  "SystemSignalLongSymbol" STRING ;
BA_DEF_DEF_  "SigType" "Default";
BA_DEF_DEF_  "GenSigStartValue" 0;
BA_DEF_DEF_  "GenSigSendType" "NoSigSendType";
BA_DEF_DEF_  "GenSigILSupport" "Yes";
BA_DEF_DEF_  "GenSigEVName" "Env@Nodename_@Signame";
BA_DEF_DEF_  "SPN" 0;
BA_DEF_DEF_  "TpJ1939VarDlc" "No";
BA_DEF_DEF_  "GenMsgStartDelayTime" 0;
BA_DEF_DEF_  "GenMsgILSupport" "Yes";
BA_DEF_DEF_  "GenMsgDelayTime" 0;
BA_DEF_DEF_  "GenMsgRequestable" 1;
BA_DEF_DEF_  "GenMsgSendType" "noMsgSendType";
BA_DEF_DEF_  "VFrameFormat" "J1939PG";
BA_DEF_DEF_  "GenMsgCycleTime" 0;
BA_DEF_DEF_  "SystemSignalLongSymbol" "";
BA_ "GenMsgCycleTime" BO_ 2364593150 100;
BA_ "GenMsgSendType" BO_ 2364593150 0;
BA_ "GenMsgCycleTime" BO_ 2364592894 100;
BA_ "GenMsgSendType" BO_ 2364592894 0;
BA_ "GenMsgCycleTime" BO_ 2364592638 100;
BA_ "GenMsgSendType" BO_ 2364592638 0;
BA_ "GenMsgCycleTime" BO_ 2364592382 1000;
BA_ "GenMsgSendType" BO_ 2364592382 0;
BA_ "GenMsgCycleTime" BO_ 2364567294 50;
BA_ "GenMsgSendType" BO_ 2364567294 0;
BA_ "GenMsgCycleTime" BO_ 2558918398 1000;
BA_ "GenMsgSendType" BO_ 2558918398 0;
BA_ "GenMsgDelayTime" BO_ 2558918398 100;
BA_ "GenMsgCycleTime" BO_ 2558852862 200;
BA_ "GenMsgSendType" BO_ 2558852862 0;
BA_ "GenMsgCycleTime" BO_ 2558656254 1000;
BA_ "GenMsgSendType" BO_ 2558656254 0;
BA_ "GenMsgDelayTime" BO_ 2558656254 100;
BA_ "GenMsgCycleTime" BO_ 2558590718 1000;
BA_ "GenMsgSendType" BO_ 2558590718 0;
BA_ "GenMsgDelayTime" BO_ 2558590718 100;
BA_ "GenMsgCycleTime" BO_ 2350710526 100;
BA_ "GenMsgSendType" BO_ 2350710526 0;
BA_ "GenMsgDelayTime" BO_ 2350710526 10;
BA_ "TpJ1939VarDlc" BO_ 2381315838 1;
BA_ "GenMsgCycleTime" BO_ 2566754814 250;
BA_ "GenMsgSendType" BO_ 2566754814 0;
BA_ "GenMsgCycleTime" BO_ 2566754302 250;
BA_ "GenMsgSendType" BO_ 2566754302 0;
BA_ "GenMsgCycleTime" BO_ 2566754046 250;
BA_ "GenMsgSendType" BO_ 2566754046 0;
BA_ "GenMsgCycleTime" BO_ 2566753790 250;
BA_ "GenMsgSendType" BO_ 2566753790 0;
BA_ "SPN" SG_ 2364598014 EngCyl16TimingOffset 7371;
BA_ "SigType" SG_ 2364598014 EngCyl16TimingOffset 1;
BA_ "SPN" SG_ 2364598014 EngCyl15TimingOffset 7370;
BA_ "SigType" SG_ 2364598014 EngCyl15TimingOffset 1;
BA_ "SPN" SG_ 2364598014 EngCyl14TimingOffset 7369;
BA_ "SigType" SG_ 2364598014 EngCyl14TimingOffset 1;
BA_ "SPN" SG_ 2364598014 EngCyl13TimingOffset 7368;
BA_ "SigType" SG_ 2364598014 EngCyl13TimingOffset 1;
BA_ "SPN" SG_ 2364598014 EngCyl12TimingOffset 7367;
BA_ "SigType" SG_ 2364598014 EngCyl12TimingOffset 1;
BA_ "SPN" SG_ 2364598014 EngCyl11TimingOffset 7366;
BA_ "SigType" SG_ 2364598014 EngCyl11TimingOffset 1;
BA_ "SPN" SG_ 2364598014 EngCyl10TimingOffset 7365;
BA_ "SigType" SG_ 2364598014 EngCyl10TimingOffset 1;
BA_ "SPN" SG_ 2364598014 EngCyl9TimingOffset 7364;
BA_ "SigType" SG_ 2364598014 EngCyl9TimingOffset 1;
BA_ "SPN" SG_ 2364597758 EngCyl8TimingOffset 7363;
BA_ "SigType" SG_ 2364597758 EngCyl8TimingOffset 1;
BA_ "SPN" SG_ 2364597758 EngCyl7TimingOffset 7362;
BA_ "SigType" SG_ 2364597758 EngCyl7TimingOffset 1;
BA_ "SPN" SG_ 2364597758 EngCyl6TimingOffset 7361;
BA_ "SigType" SG_ 2364597758 EngCyl6TimingOffset 1;
BA_ "SPN" SG_ 2364597758 EngCyl5TimingOffset 7360;
BA_ "SigType" SG_ 2364597758 EngCyl5TimingOffset 1;
BA_ "SPN" SG_ 2364597758 EngCyl4TimingOffset 7359;
BA_ "SigType" SG_ 2364597758 EngCyl4TimingOffset 1;
BA_ "SPN" SG_ 2364597758 EngCyl3TimingOffset 7358;
BA_ "SigType" SG_ 2364597758 EngCyl3TimingOffset 1;
BA_ "SPN" SG_ 2364597758 EngCyl2TimingOffset 7357;
BA_ "SigType" SG_ 2364597758 EngCyl2TimingOffset 1;
BA_ "SPN" SG_ 2364597758 EngCyl1TimingOffset 7356;
BA_ "SigType" SG_ 2364597758 EngCyl1TimingOffset 1;
BA_ "SPN" SG_ 2364593150 PrdctvCrsCtrlDrvlnDsnggInhibitRq 7430;
BA_ "SigType" SG_ 2364593150 PrdctvCrsCtrlDrvlnDsnggInhibitRq 5;
BA_ "SPN" SG_ 2364593150 VhclSpdCtrlOvrrideEventIndicator 7435;
BA_ "SigType" SG_ 2364593150 VhclSpdCtrlOvrrideEventIndicator 5;
BA_ "SPN" SG_ 2364593150 PrdctvCrsCtrlSpeedEventIndicator 7434;
BA_ "SigType" SG_ 2364593150 PrdctvCrsCtrlSpeedEventIndicator 5;
BA_ "SPN" SG_ 2364593150 PredictiveCruiseCtrlNextGrade 7433;
BA_ "SigType" SG_ 2364593150 PredictiveCruiseCtrlNextGrade 1;
BA_ "SPN" SG_ 2364593150 PredictiveCruiseCtrlPresentGrade 7432;
BA_ "SigType" SG_ 2364593150 PredictiveCruiseCtrlPresentGrade 1;
BA_ "SPN" SG_ 2364593150 PredictiveCruiseCtrlEventInRange 7431;
BA_ "SigType" SG_ 2364593150 PredictiveCruiseCtrlEventInRange 4;
BA_ "SPN" SG_ 2364593150 VehicleSpeedCtrlOverrideRq 7429;
BA_ "SigType" SG_ 2364593150 VehicleSpeedCtrlOverrideRq 5;
BA_ "SPN" SG_ 2364593150 PredictiveCruiseCtrlState 7317;
BA_ "SPN" SG_ 2364593150 PrdctiveCruiseCtrlSetSpeedOffset 7316;
BA_ "SigType" SG_ 2364593150 PrdctiveCruiseCtrlSetSpeedOffset 1;
BA_ "SPN" SG_ 2364592894 EngCylHeadBypassActuator1Cmd 7094;
BA_ "SigType" SG_ 2364592894 EngCylHeadBypassActuator1Cmd 1;
BA_ "SPN" SG_ 2364592638 EngCylHdBypssActtr1OprtionStatus 7093;
BA_ "SPN" SG_ 2364592638 EngCylHeadBypassActuator1Pos 7092;
BA_ "SigType" SG_ 2364592638 EngCylHeadBypassActuator1Pos 1;
BA_ "SPN" SG_ 2364592638 EngCylHdBypssActuator1DesiredPos 7091;
BA_ "SigType" SG_ 2364592638 EngCylHdBypssActuator1DesiredPos 1;
BA_ "SPN" SG_ 2364592638 EngCylHeadBypassActuator1Temp 7090;
BA_ "SigType" SG_ 2364592638 EngCylHeadBypassActuator1Temp 1;
BA_ "SPN" SG_ 2364592638 EngCylHdBypssActuator1TempStatus 7089;
BA_ "SPN" SG_ 2364592638 EngCylHdBypssActtr1PrliminaryFMI 7088;
BA_ "SPN" SG_ 2364592382 EngCyl24ExcludeFromCombustionRq 7015;
BA_ "SigType" SG_ 2364592382 EngCyl24ExcludeFromCombustionRq 5;
BA_ "SPN" SG_ 2364592382 EngCyl23ExcludeFromCombustionRq 7014;
BA_ "SigType" SG_ 2364592382 EngCyl23ExcludeFromCombustionRq 5;
BA_ "SPN" SG_ 2364592382 EngCyl22ExcludeFromCombustionRq 7013;
BA_ "SigType" SG_ 2364592382 EngCyl22ExcludeFromCombustionRq 5;
BA_ "SPN" SG_ 2364592382 EngCyl21ExcludeFromCombustionRq 7012;
BA_ "SigType" SG_ 2364592382 EngCyl21ExcludeFromCombustionRq 5;
BA_ "SPN" SG_ 2364592382 EngCyl20ExcludeFromCombustionRq 7011;
BA_ "SigType" SG_ 2364592382 EngCyl20ExcludeFromCombustionRq 5;
BA_ "SPN" SG_ 2364592382 EngCyl19ExcludeFromCombustionRq 7010;
BA_ "SigType" SG_ 2364592382 EngCyl19ExcludeFromCombustionRq 5;
BA_ "SPN" SG_ 2364592382 EngCyl18ExcludeFromCombustionRq 7009;
BA_ "SigType" SG_ 2364592382 EngCyl18ExcludeFromCombustionRq 5;
BA_ "SPN" SG_ 2364592382 EngCyl17ExcludeFromCombustionRq 7008;
BA_ "SigType" SG_ 2364592382 EngCyl17ExcludeFromCombustionRq 5;
BA_ "SPN" SG_ 2364592382 EngCyl16ExcludeFromCombustionRq 7007;
BA_ "SigType" SG_ 2364592382 EngCyl16ExcludeFromCombustionRq 5;
BA_ "SPN" SG_ 2364592382 EngCyl15ExcludeFromCombustionRq 7006;
BA_ "SigType" SG_ 2364592382 EngCyl15ExcludeFromCombustionRq 5;
BA_ "SPN" SG_ 2364592382 EngCyl14ExcludeFromCombustionRq 7005;
BA_ "SigType" SG_ 2364592382 EngCyl14ExcludeFromCombustionRq 5;
BA_ "SPN" SG_ 2364592382 EngCyl13ExcludeFromCombustionRq 7004;
BA_ "SigType" SG_ 2364592382 EngCyl13ExcludeFromCombustionRq 5;
BA_ "SPN" SG_ 2364592382 EngCyl12ExcludeFromCombustionRq 7003;
BA_ "SigType" SG_ 2364592382 EngCyl12ExcludeFromCombustionRq 5;
BA_ "SPN" SG_ 2364592382 EngCyl11ExcludeFromCombustionRq 7002;
BA_ "SigType" SG_ 2364592382 EngCyl11ExcludeFromCombustionRq 5;
BA_ "SPN" SG_ 2364592382 EngCyl10ExcludeFromCombustionRq 7001;
BA_ "SigType" SG_ 2364592382 EngCyl10ExcludeFromCombustionRq 5;
BA_ "SPN" SG_ 2364592382 EngCyl9ExcludeFromCombustionRq 7000;
BA_ "SigType" SG_ 2364592382 EngCyl9ExcludeFromCombustionRq 5;
BA_ "SPN" SG_ 2364592382 EngCyl8ExcludeFromCombustionRq 6999;
BA_ "SigType" SG_ 2364592382 EngCyl8ExcludeFromCombustionRq 5;
BA_ "SPN" SG_ 2364592382 EngCyl7ExcludeFromCombustionRq 6998;
BA_ "SigType" SG_ 2364592382 EngCyl7ExcludeFromCombustionRq 5;
BA_ "SPN" SG_ 2364592382 EngCyl6ExcludeFromCombustionRq 6997;
BA_ "SigType" SG_ 2364592382 EngCyl6ExcludeFromCombustionRq 5;
BA_ "SPN" SG_ 2364592382 EngCyl5ExcludeFromCombustionRq 6996;
BA_ "SigType" SG_ 2364592382 EngCyl5ExcludeFromCombustionRq 5;
BA_ "SPN" SG_ 2364592382 EngCyl4ExcludeFromCombustionRq 6995;
BA_ "SigType" SG_ 2364592382 EngCyl4ExcludeFromCombustionRq 5;
BA_ "SPN" SG_ 2364592382 EngCyl3ExcludeFromCombustionRq 6994;
BA_ "SigType" SG_ 2364592382 EngCyl3ExcludeFromCombustionRq 5;
BA_ "SPN" SG_ 2364592382 EngCyl2ExcludeFromCombustionRq 6993;
BA_ "SigType" SG_ 2364592382 EngCyl2ExcludeFromCombustionRq 5;
BA_ "SPN" SG_ 2364592382 EngCyl1ExcludeFromCombustionRq 6992;
BA_ "SigType" SG_ 2364592382 EngCyl1ExcludeFromCombustionRq 5;
BA_ "SPN" SG_ 2364592382 NmbrOfEngCylndrsTExcldFrmCmbston 6991;
BA_ "SigType" SG_ 2364592382 NmbrOfEngCylndrsTExcldFrmCmbston 1;
BA_ "SPN" SG_ 2364567294 EngFlInjctnPump2FuelCtrlValveCmd 6720;
BA_ "SigType" SG_ 2364567294 EngFlInjctnPump2FuelCtrlValveCmd 1;
BA_ "SPN" SG_ 2364567294 EngFlInjctnPump1FuelCtrlValveCmd 6719;
BA_ "SigType" SG_ 2364567294 EngFlInjctnPump1FuelCtrlValveCmd 1;
BA_ "SPN" SG_ 2558918398 PrdctvCriseCtrlMaxNegativeOffset 7439;
BA_ "SigType" SG_ 2558918398 PrdctvCriseCtrlMaxNegativeOffset 1;
BA_ "SPN" SG_ 2558918398 PrdctvCriseCtrlMaxPositiveOffset 7438;
BA_ "SigType" SG_ 2558918398 PrdctvCriseCtrlMaxPositiveOffset 1;
BA_ "SPN" SG_ 2558918398 PrdctiveCruiseCtrlDeactivationRq 7437;
BA_ "SigType" SG_ 2558918398 PrdctiveCruiseCtrlDeactivationRq 4;
BA_ "SPN" SG_ 2558918398 PredictiveCruiseCtrlEnableSwitch 7436;
BA_ "SigType" SG_ 2558918398 PredictiveCruiseCtrlEnableSwitch 4;
BA_ "SPN" SG_ 2558918398 HtExchngerDebrisPurgeForceSwitch 7034;
BA_ "SigType" SG_ 2558918398 HtExchngerDebrisPurgeForceSwitch 4;
BA_ "SPN" SG_ 2558918398 HtExchngrDbrisPurgeInhibitSwitch 7033;
BA_ "SigType" SG_ 2558918398 HtExchngrDbrisPurgeInhibitSwitch 4;
BA_ "SPN" SG_ 2558918398 SCROprtrInducementOverrideSwitch 6881;
BA_ "SigType" SG_ 2558918398 SCROprtrInducementOverrideSwitch 5;
BA_ "SPN" SG_ 2558918398 PerformanceBiasSelection 6874;
BA_ "SigType" SG_ 2558918398 PerformanceBiasSelection 1;
BA_ "SPN" SG_ 2558918398 EngFan2RequestedPercentSpeed 6730;
BA_ "SigType" SG_ 2558918398 EngFan2RequestedPercentSpeed 1;
BA_ "SPN" SG_ 2558852862 AT1PrtclateSensorExhaustVelocity 6829;
BA_ "SigType" SG_ 2558852862 AT1PrtclateSensorExhaustVelocity 1;
BA_ "SPN" SG_ 2558852862 AT1ParticulateSensorExhaustTemp 6785;
BA_ "SigType" SG_ 2558852862 AT1ParticulateSensorExhaustTemp 1;
BA_ "SPN" SG_ 2558852862 AT1ParticulateSensorDewpoint 6784;
BA_ "SigType" SG_ 2558852862 AT1ParticulateSensorDewpoint 5;
BA_ "SPN" SG_ 2558852862 AT1PrtculateSensorRegenerationRq 6783;
BA_ "SigType" SG_ 2558852862 AT1PrtculateSensorRegenerationRq 5;
BA_ "SPN" SG_ 2558852862 AT1ParticulateSensorShutdownRq 6782;
BA_ "SigType" SG_ 2558852862 AT1ParticulateSensorShutdownRq 5;
BA_ "SPN" SG_ 2558787326 PayloadCorrectionFactorCmd 6873;
BA_ "SigType" SG_ 2558787326 PayloadCorrectionFactorCmd 1;
BA_ "SPN" SG_ 2558787326 PayloadCalibCommandedWeight 6872;
BA_ "SigType" SG_ 2558787326 PayloadCalibCommandedWeight 1;
BA_ "SPN" SG_ 2558787326 PayloadCalibSetPointCmd 6871;
BA_ "SPN" SG_ 2558721790 OverTempSetting 6978;
BA_ "SigType" SG_ 2558721790 OverTempSetting 1;
BA_ "SPN" SG_ 2558721790 OvrPrssPrcentageThresholdSetting 6977;
BA_ "SigType" SG_ 2558721790 OvrPrssPrcentageThresholdSetting 1;
BA_ "SPN" SG_ 2558721790 ExtrmUndrPrssPrcntgThrshldStting 6976;
BA_ "SigType" SG_ 2558721790 ExtrmUndrPrssPrcntgThrshldStting 1;
BA_ "SPN" SG_ 2558721790 UndrPrssPrcntageThresholdSetting 6975;
BA_ "SigType" SG_ 2558721790 UndrPrssPrcntageThresholdSetting 1;
BA_ "SPN" SG_ 2558721790 ColdInflationPressSetting 6974;
BA_ "SigType" SG_ 2558721790 ColdInflationPressSetting 1;
BA_ "SPN" SG_ 2558721790 TireLocation 6973;
BA_ "SPN" SG_ 2558656254 RqToPermitDEFDosingTestInjection 7516;
BA_ "SPN" SG_ 2558656254 RqToPermitDEFHydStiffnessCheck 7515;
BA_ "SigType" SG_ 2558656254 RqToPermitDEFHydStiffnessCheck 5;
BA_ "SPN" SG_ 2558656254 ATThermalManagementInhibitRq 7331;
BA_ "SigType" SG_ 2558656254 ATThermalManagementInhibitRq 5;
BA_ "SPN" SG_ 2558590718 HybrdSystmRgnrtvBrakingDisableRq 7559;
BA_ "SigType" SG_ 2558590718 HybrdSystmRgnrtvBrakingDisableRq 5;
BA_ "SPN" SG_ 2558590718 HybridSystemProtectionOverrideRq 7557;
BA_ "SigType" SG_ 2558590718 HybridSystemProtectionOverrideRq 5;
BA_ "SPN" SG_ 2350776062 EngTimingAdvance 7355;
BA_ "SigType" SG_ 2350776062 EngTimingAdvance 1;
BA_ "SPN" SG_ 2350710526 MessageChecksum 7042;
BA_ "SPN" SG_ 2350710526 TransRequestedTorque_TorqueLimit 7040;
BA_ "SigType" SG_ 2350710526 TransRequestedTorque_TorqueLimit 1;
BA_ "SPN" SG_ 2350710526 TransRequestedOutputShaftSpeed 7039;
BA_ "GenSigStartValue" SG_ 2350710526 TransRequestedOutputShaftSpeed 2;
BA_ "SigType" SG_ 2350710526 TransRequestedOutputShaftSpeed 1;
BA_ "SPN" SG_ 2350710526 MessageCounter 7041;
BA_ "SPN" SG_ 2350710526 TransOverrideCtrlModePriority 7038;
BA_ "SigType" SG_ 2350710526 TransOverrideCtrlModePriority 5;
BA_ "SPN" SG_ 2350710526 TransOverrideCtrlMode 7037;
BA_ "SigType" SG_ 2350710526 TransOverrideCtrlMode 5;
BA_ "SPN" SG_ 2381315838 ManufacturerSpecificInformation 3328;
BA_ "SPN" SG_ 2365475326 GroundBasedDirection 1861;
BA_ "SigType" SG_ 2365475326 GroundBasedDirection 4;
BA_ "SPN" SG_ 2365475326 GroundBasedImplementDistance 1860;
BA_ "SPN" SG_ 2365475326 GroundBasedImplementSpeed 1859;
BA_ "SPN" SG_ 2365475070 KeySwitchNOTOFF 1865;
BA_ "SigType" SG_ 2365475070 KeySwitchNOTOFF 4;
BA_ "SPN" SG_ 2365475070 WheelBasedDirection 1864;
BA_ "SigType" SG_ 2365475070 WheelBasedDirection 4;
BA_ "SPN" SG_ 2365475070 MaxTimeOfTractorPower 1866;
BA_ "SPN" SG_ 2365475070 WheelBasedDistance 1863;
BA_ "SPN" SG_ 2365475070 WheelBasedSpeed 1862;
BA_ "SPN" SG_ 2365474814 ImplementInWorkState 7447;
BA_ "SPN" SG_ 2365474814 ImplementTransportState 1869;
BA_ "SigType" SG_ 2365474814 ImplementTransportState 4;
BA_ "SPN" SG_ 2365474814 ImplementParkState 1870;
BA_ "SigType" SG_ 2365474814 ImplementParkState 4;
BA_ "SPN" SG_ 2365474814 ImplementWorkState 1871;
BA_ "SigType" SG_ 2365474814 ImplementWorkState 4;
BA_ "SPN" SG_ 2365474814 MaintainECUPower 1867;
BA_ "SigType" SG_ 2365474814 MaintainECUPower 4;
BA_ "SPN" SG_ 2365474814 MaintainAcuatorPower 1868;
BA_ "SigType" SG_ 2365474814 MaintainAcuatorPower 4;
BA_ "SPN" SG_ 2365474558 FrontDraft 1878;
BA_ "SPN" SG_ 2365474558 FrontNominalLowerLinkForce 1880;
BA_ "SPN" SG_ 2365474558 FrontHitchInworkIndication 1876;
BA_ "SigType" SG_ 2365474558 FrontHitchInworkIndication 4;
BA_ "SPN" SG_ 2365474558 FrontHitchPos 1872;
BA_ "SPN" SG_ 2365474302 RearHitchExit_reasonCode 5819;
BA_ "SPN" SG_ 2365474302 RearDraft 1879;
BA_ "SPN" SG_ 2365474302 RearNominalLowerLinkForce 1881;
BA_ "SPN" SG_ 2365474302 RearHitchInworkIndication 1877;
BA_ "SigType" SG_ 2365474302 RearHitchInworkIndication 4;
BA_ "SPN" SG_ 2365474302 RearHitchPos 1873;
BA_ "SPN" SG_ 2365474046 FrontPTOExit_reasonCode 5817;
BA_ "SPN" SG_ 2365474046 FrontHitchExit_reasonCode 5816;
BA_ "SPN" SG_ 2365474046 FrontPowerTakeOffEngagement 1888;
BA_ "SigType" SG_ 2365474046 FrontPowerTakeOffEngagement 4;
BA_ "SPN" SG_ 2365474046 FrontPowerTakeOffMode 1889;
BA_ "SigType" SG_ 2365474046 FrontPowerTakeOffMode 4;
BA_ "SPN" SG_ 2365474046 FrontPowerTakeOffEconomyMode 1891;
BA_ "SigType" SG_ 2365474046 FrontPowerTakeOffEconomyMode 4;
BA_ "SPN" SG_ 2365474046 FrontPTOOutputShaftSpeedSetPoint 1884;
BA_ "SPN" SG_ 2365474046 FrontPTOOutputShaftSpeed 1882;
BA_ "SPN" SG_ 2365473790 RearPTOExit_reasonCode 5820;
BA_ "SPN" SG_ 2365473790 RearPowerTakeOffEngagement 2408;
BA_ "SigType" SG_ 2365473790 RearPowerTakeOffEngagement 4;
BA_ "SPN" SG_ 2365473790 RearPowerTakeOffMode 1890;
BA_ "SigType" SG_ 2365473790 RearPowerTakeOffMode 4;
BA_ "SPN" SG_ 2365473790 RearPowerTakeOffEconomyMode 1892;
BA_ "SigType" SG_ 2365473790 RearPowerTakeOffEconomyMode 4;
BA_ "SPN" SG_ 2365473790 RearPTOOutputShaftSpeedSetPoint 1885;
BA_ "SPN" SG_ 2365473790 RearPTOOutputShaftSpeed 1883;
BA_ "SPN" SG_ 2365473534 FrontPowerTakeOffModeCmd 1895;
BA_ "SigType" SG_ 2365473534 FrontPowerTakeOffModeCmd 4;
BA_ "SPN" SG_ 2365473534 RearPowerTakeOffModeCmd 1896;
BA_ "SigType" SG_ 2365473534 RearPowerTakeOffModeCmd 4;
BA_ "SPN" SG_ 2365473534 FrontPowerTakeOffEconomyModeCmd 1897;
BA_ "SigType" SG_ 2365473534 FrontPowerTakeOffEconomyModeCmd 4;
BA_ "SPN" SG_ 2365473534 RearPowerTakeOffEconomyModeCmd 1898;
BA_ "SigType" SG_ 2365473534 RearPowerTakeOffEconomyModeCmd 4;
BA_ "SPN" SG_ 2365473534 FrontPowerTakeOffEngagementCmd 1893;
BA_ "SigType" SG_ 2365473534 FrontPowerTakeOffEngagementCmd 4;
BA_ "SPN" SG_ 2365473534 RearPowerTakeOffEngagementCmd 1894;
BA_ "SigType" SG_ 2365473534 RearPowerTakeOffEngagementCmd 4;
BA_ "SPN" SG_ 2365473534 RrPTOOutputShaftSpeedSetPointCmd 1887;
BA_ "SPN" SG_ 2365473534 FrntPTOOtptShaftSpeedSetPointCmd 1886;
BA_ "SPN" SG_ 2365473534 RearHitchPosCmd 1875;
BA_ "SPN" SG_ 2365473534 FrontHitchPosCmd 1874;
BA_ "SPN" SG_ 2365472766 AuxValve15FailSafeModeCmd 2345;
BA_ "SigType" SG_ 2365472766 AuxValve15FailSafeModeCmd 4;
BA_ "SPN" SG_ 2365472766 AuxValve15StateCmd 2344;
BA_ "SPN" SG_ 2365472766 AuxValve15PortFlowCmd 2343;
BA_ "SPN" SG_ 2365472510 AuxValve14FailSafeModeCmd 2333;
BA_ "SigType" SG_ 2365472510 AuxValve14FailSafeModeCmd 4;
BA_ "SPN" SG_ 2365472510 AuxValve14StateCmd 2332;
BA_ "SPN" SG_ 2365472510 AuxValve14PortFlowCmd 2331;
BA_ "SPN" SG_ 2365472254 AuxValve13FailSafeModeCmd 2321;
BA_ "SigType" SG_ 2365472254 AuxValve13FailSafeModeCmd 4;
BA_ "SPN" SG_ 2365472254 AuxValve13StateCmd 2320;
BA_ "SPN" SG_ 2365472254 AuxValve13PortFlowCmd 2319;
BA_ "SPN" SG_ 2365471998 AuxValve12FailSafeModeCmd 2309;
BA_ "SigType" SG_ 2365471998 AuxValve12FailSafeModeCmd 4;
BA_ "SPN" SG_ 2365471998 AuxValve12StateCmd 2308;
BA_ "SPN" SG_ 2365471998 AuxValve12PortFlowCmd 2307;
BA_ "SPN" SG_ 2365471742 AuxValve11FailSafeModeCmd 2297;
BA_ "SigType" SG_ 2365471742 AuxValve11FailSafeModeCmd 4;
BA_ "SPN" SG_ 2365471742 AuxValve11StateCmd 2296;
BA_ "SPN" SG_ 2365471742 AuxValve11PortFlowCmd 2295;
BA_ "SPN" SG_ 2365471486 AuxValve10FailSafeModeCmd 2285;
BA_ "SigType" SG_ 2365471486 AuxValve10FailSafeModeCmd 4;
BA_ "SPN" SG_ 2365471486 AuxValve10StateCmd 2284;
BA_ "SPN" SG_ 2365471486 AuxValve10PortFlowCmd 2283;
BA_ "SPN" SG_ 2365471230 AuxValve9FailSafeModeCmd 2273;
BA_ "SigType" SG_ 2365471230 AuxValve9FailSafeModeCmd 4;
BA_ "SPN" SG_ 2365471230 AuxValve9StateCmd 2272;
BA_ "SPN" SG_ 2365471230 AuxValve9PortFlowCmd 2271;
BA_ "SPN" SG_ 2365470974 AuxValve8FailSafeModeCmd 2261;
BA_ "SigType" SG_ 2365470974 AuxValve8FailSafeModeCmd 4;
BA_ "SPN" SG_ 2365470974 AuxValve8StateCmd 2260;
BA_ "SPN" SG_ 2365470974 AuxValve8PortFlowCmd 2259;
BA_ "SPN" SG_ 2365470718 AuxValve7FailSafeModeCmd 1993;
BA_ "SigType" SG_ 2365470718 AuxValve7FailSafeModeCmd 4;
BA_ "SPN" SG_ 2365470718 AuxValve7StateCmd 1992;
BA_ "SPN" SG_ 2365470718 AuxValve7PortFlowCmd 1991;
BA_ "SPN" SG_ 2365470462 AuxValve6FailSafeModeCmd 1981;
BA_ "SigType" SG_ 2365470462 AuxValve6FailSafeModeCmd 4;
BA_ "SPN" SG_ 2365470462 AuxValve6StateCmd 1980;
BA_ "SPN" SG_ 2365470462 AuxValve6PortFlowCmd 1979;
BA_ "SPN" SG_ 2365470206 AuxValve5FailSafeModeCmd 1969;
BA_ "SigType" SG_ 2365470206 AuxValve5FailSafeModeCmd 4;
BA_ "SPN" SG_ 2365470206 AuxValve5StateCmd 1968;
BA_ "SPN" SG_ 2365470206 AuxValve5PortFlowCmd 1967;
BA_ "SPN" SG_ 2365469950 AuxValve4FailSafeModeCmd 1957;
BA_ "SigType" SG_ 2365469950 AuxValve4FailSafeModeCmd 4;
BA_ "SPN" SG_ 2365469950 AuxValve4StateCmd 1956;
BA_ "SPN" SG_ 2365469950 AuxValve4PortFlowCmd 1955;
BA_ "SPN" SG_ 2365469694 AuxValve3FailSafeModeCmd 1945;
BA_ "SigType" SG_ 2365469694 AuxValve3FailSafeModeCmd 4;
BA_ "SPN" SG_ 2365469694 AuxValve3StateCmd 1944;
BA_ "SPN" SG_ 2365469694 AuxValve3PortFlowCmd 1943;
BA_ "SPN" SG_ 2365469438 AuxValve2FailSafeModeCmd 1933;
BA_ "SigType" SG_ 2365469438 AuxValve2FailSafeModeCmd 4;
BA_ "SPN" SG_ 2365469438 AuxValve2StateCmd 1932;
BA_ "SPN" SG_ 2365469438 AuxValve2PortFlowCmd 1931;
BA_ "SPN" SG_ 2365469182 AuxValve1FailSafeModeCmd 1921;
BA_ "SigType" SG_ 2365469182 AuxValve1FailSafeModeCmd 4;
BA_ "SPN" SG_ 2365469182 AuxValve1StateCmd 1920;
BA_ "SPN" SG_ 2365469182 AuxValve1PortFlowCmd 1919;
BA_ "SPN" SG_ 2365468926 AuxValve0FailSafeModeCmd 1909;
BA_ "SigType" SG_ 2365468926 AuxValve0FailSafeModeCmd 4;
BA_ "SPN" SG_ 2365468926 AuxValve0StateCmd 1908;
BA_ "SPN" SG_ 2365468926 AuxValve0PortFlowCmd 1907;
BA_ "SPN" SG_ 2365468670 AuxValve15ReturnPortPress 2342;
BA_ "SPN" SG_ 2365468670 AuxValve15RetractPortPress 2341;
BA_ "SPN" SG_ 2365468670 AuxValve15ExtendPortPress 2340;
BA_ "SPN" SG_ 2365468670 AxValve15RetractPortMeasuredFlow 2336;
BA_ "SPN" SG_ 2365468670 AuxValve15ExtendPortMeasuredFlow 2335;
BA_ "SPN" SG_ 2365468414 AuxValve14ReturnPortPress 2330;
BA_ "SPN" SG_ 2365468414 AuxValve14RetractPortPress 2329;
BA_ "SPN" SG_ 2365468414 AuxValve14ExtendPortPress 2328;
BA_ "SPN" SG_ 2365468414 AxValve14RetractPortMeasuredFlow 2324;
BA_ "SPN" SG_ 2365468414 AuxValve14ExtendPortMeasuredFlow 2323;
BA_ "SPN" SG_ 2365468158 AuxValve13ReturnPortPress 2318;
BA_ "SPN" SG_ 2365468158 AuxValve13RetractPortPress 2317;
BA_ "SPN" SG_ 2365468158 AuxValve13ExtendPortPress 2316;
BA_ "SPN" SG_ 2365468158 AxValve13RetractPortMeasuredFlow 2312;
BA_ "SPN" SG_ 2365468158 AuxValve13ExtendPortMeasuredFlow 2311;
BA_ "SPN" SG_ 2365467902 AuxValve12ReturnPortPress 2306;
BA_ "SPN" SG_ 2365467902 AuxValve12RetractPortPress 2305;
BA_ "SPN" SG_ 2365467902 AuxValve12ExtendPortPress 2304;
BA_ "SPN" SG_ 2365467902 AxValve12RetractPortMeasuredFlow 2300;
BA_ "SPN" SG_ 2365467902 AuxValve12ExtendPortMeasuredFlow 2299;
BA_ "SPN" SG_ 2365467646 AuxValve11ReturnPortPress 2294;
BA_ "SPN" SG_ 2365467646 AuxValve11RetractPortPress 2293;
BA_ "SPN" SG_ 2365467646 AuxValve11ExtendPortPress 2292;
BA_ "SPN" SG_ 2365467646 AxValve11RetractPortMeasuredFlow 2288;
BA_ "SPN" SG_ 2365467646 AuxValve11ExtendPortMeasuredFlow 2287;
BA_ "SPN" SG_ 2365467390 AuxValve10ReturnPortPress 2282;
BA_ "SPN" SG_ 2365467390 AuxValve10RetractPortPress 2281;
BA_ "SPN" SG_ 2365467390 AuxValve10ExtendPortPress 2280;
BA_ "SPN" SG_ 2365467390 AxValve10RetractPortMeasuredFlow 2276;
BA_ "SPN" SG_ 2365467390 AuxValve10ExtendPortMeasuredFlow 2275;
BA_ "SPN" SG_ 2365467134 AuxValve9ReturnPortPress 2270;
BA_ "SPN" SG_ 2365467134 AuxValve9RetractPortPress 2269;
BA_ "SPN" SG_ 2365467134 AuxValve9ExtendPortPress 2268;
BA_ "SPN" SG_ 2365467134 AuxValve9RetractPortMeasuredFlow 2264;
BA_ "SPN" SG_ 2365467134 AuxValve9ExtendPortMeasuredFlow 2263;
BA_ "SPN" SG_ 2365466878 AuxValve8ReturnPortPress 2258;
BA_ "SPN" SG_ 2365466878 AuxValve8RetractPortPress 2257;
BA_ "SPN" SG_ 2365466878 AuxValve8ExtendPortPress 2256;
BA_ "SPN" SG_ 2365466878 AuxValve8RetractPortMeasuredFlow 1996;
BA_ "SPN" SG_ 2365466878 AuxValve8ExtendPortMeasuredFlow 1995;
BA_ "SPN" SG_ 2365466622 AuxValve7ReturnPortPress 1990;
BA_ "SPN" SG_ 2365466622 AuxValve7RetractPortPress 1989;
BA_ "SPN" SG_ 2365466622 AuxValve7ExtendPortPress 1988;
BA_ "SPN" SG_ 2365466622 AuxValve7RetractPortMeasuredFlow 1984;
BA_ "SPN" SG_ 2365466622 AuxValve7ExtendPortMeasuredFlow 1983;
BA_ "SPN" SG_ 2365466366 AuxValve6ReturnPortPress 1978;
BA_ "SPN" SG_ 2365466366 AuxValve6RetractPortPress 1977;
BA_ "SPN" SG_ 2365466366 AuxValve6ExtendPortPress 1976;
BA_ "SPN" SG_ 2365466366 AuxValve6RetractPortMeasuredFlow 1972;
BA_ "SPN" SG_ 2365466366 AuxValve6ExtendPortMeasuredFlow 1971;
BA_ "SPN" SG_ 2365466110 AuxValve5ReturnPortPress 1966;
BA_ "SPN" SG_ 2365466110 AuxValve5RetractPortPress 1965;
BA_ "SPN" SG_ 2365466110 AuxValve5ExtendPortPress 1964;
BA_ "SPN" SG_ 2365466110 AuxValve5RetractPortMeasuredFlow 1960;
BA_ "SPN" SG_ 2365466110 AuxValve5ExtendPortMeasuredFlow 1959;
BA_ "SPN" SG_ 2365465854 AuxValve4ReturnPortPress 1954;
BA_ "SPN" SG_ 2365465854 AuxValve4RetractPortPress 1953;
BA_ "SPN" SG_ 2365465854 AuxValve4ExtendPortPress 1952;
BA_ "SPN" SG_ 2365465854 AuxValve4RetractPortMeasuredFlow 1948;
BA_ "SPN" SG_ 2365465854 AuxValve4ExtendPortMeasuredFlow 1947;
BA_ "SPN" SG_ 2365465598 AuxValve3ReturnPortPress 1942;
BA_ "SPN" SG_ 2365465598 AuxValve3RetractPortPress 1941;
BA_ "SPN" SG_ 2365465598 AuxValve3ExtendPortPress 1940;
BA_ "SPN" SG_ 2365465598 AuxValve3RetractPortMeasuredFlow 1936;
BA_ "SPN" SG_ 2365465598 AuxValve3ExtendPortMeasuredFlow 1935;
BA_ "SPN" SG_ 2365465342 AuxValve2ReturnPortPress 1930;
BA_ "SPN" SG_ 2365465342 AuxValve2RetractPortPress 1929;
BA_ "SPN" SG_ 2365465342 AuxValve2ExtendPortPress 1928;
BA_ "SPN" SG_ 2365465342 AuxValve2RetractPortMeasuredFlow 1924;
BA_ "SPN" SG_ 2365465342 AuxValve2ExtendPortMeasuredFlow 1923;
BA_ "SPN" SG_ 2365465086 AuxValve1ReturnPortPress 1918;
BA_ "SPN" SG_ 2365465086 AuxValve1RetractPortPress 1917;
BA_ "SPN" SG_ 2365465086 AuxValve1ExtendPortPress 1916;
BA_ "SPN" SG_ 2365465086 AuxValve1RetractPortMeasuredFlow 1912;
BA_ "SPN" SG_ 2365465086 AuxValve1ExtendPortMeasuredFlow 1911;
BA_ "SPN" SG_ 2365464830 AuxValve0ReturnPortPress 1906;
BA_ "SPN" SG_ 2365464830 AuxValve0RetractPortPress 1905;
BA_ "SPN" SG_ 2365464830 AuxValve0ExtendPortPress 1904;
BA_ "SPN" SG_ 2365464830 AuxValve0RetractPortMeasuredFlow 1900;
BA_ "SPN" SG_ 2365464830 AuxValve0ExtendPortMeasuredFlow 1899;
BA_ "SPN" SG_ 2365464574 AuxValve15Exit_reasonCode 5815;
BA_ "SPN" SG_ 2365464574 AuxValve15FailSafeMode 2346;
BA_ "SigType" SG_ 2365464574 AuxValve15FailSafeMode 4;
BA_ "SPN" SG_ 2365464574 AuxValve15State 2339;
BA_ "SPN" SG_ 2365464574 AuxValve15RetractPortEstFlow 2338;
BA_ "SPN" SG_ 2365464574 AuxValve15ExtendPortEstFlow 2337;
BA_ "SPN" SG_ 2365464318 AuxValve14Exit_reasonCode 5814;
BA_ "SPN" SG_ 2365464318 AuxValve14FailSafeMode 2334;
BA_ "SigType" SG_ 2365464318 AuxValve14FailSafeMode 4;
BA_ "SPN" SG_ 2365464318 AuxValve14State 2327;
BA_ "SPN" SG_ 2365464318 AuxValve14RetractPortEstFlow 2326;
BA_ "SPN" SG_ 2365464318 AuxValve14ExtendPortEstFlow 2325;
BA_ "SPN" SG_ 2365464062 AuxValve13Exit_reasonCode 5813;
BA_ "SPN" SG_ 2365464062 AuxValve13FailSafeMode 2322;
BA_ "SigType" SG_ 2365464062 AuxValve13FailSafeMode 4;
BA_ "SPN" SG_ 2365464062 AuxValve13State 2315;
BA_ "SPN" SG_ 2365464062 AuxValve13RetractPortEstFlow 2314;
BA_ "SPN" SG_ 2365464062 AuxValve13ExtendPortEstFlow 2313;
BA_ "SPN" SG_ 2365463806 AuxValve12Exit_reasonCode 5812;
BA_ "SPN" SG_ 2365463806 AuxValve12FailSafeMode 2310;
BA_ "SigType" SG_ 2365463806 AuxValve12FailSafeMode 4;
BA_ "SPN" SG_ 2365463806 AuxValve12State 2303;
BA_ "SPN" SG_ 2365463806 AuxValve12RetractPortEstFlow 2302;
BA_ "SPN" SG_ 2365463806 AuxValve12ExtendPortEstFlow 2301;
BA_ "SPN" SG_ 2365463550 AuxValve11Exit_reasonCode 5811;
BA_ "SPN" SG_ 2365463550 AuxValve11FailSafeMode 2298;
BA_ "SigType" SG_ 2365463550 AuxValve11FailSafeMode 4;
BA_ "SPN" SG_ 2365463550 AuxValve11State 2291;
BA_ "SPN" SG_ 2365463550 AuxValve11RetractPortEstFlow 2290;
BA_ "SPN" SG_ 2365463550 AuxValve11ExtendPortEstFlow 2289;
BA_ "SPN" SG_ 2365463294 AuxValve10Exit_reasonCode 5810;
BA_ "SPN" SG_ 2365463294 AuxValve10FailSafeMode 2286;
BA_ "SigType" SG_ 2365463294 AuxValve10FailSafeMode 4;
BA_ "SPN" SG_ 2365463294 AuxValve10State 2279;
BA_ "SPN" SG_ 2365463294 AuxValve10RetractPortEstFlow 2278;
BA_ "SPN" SG_ 2365463294 AuxValve10ExtendPortEstFlow 2277;
BA_ "SPN" SG_ 2365463038 AuxValve9Exit_reasonCode 5809;
BA_ "SPN" SG_ 2365463038 AuxValve9FailSafeMode 2274;
BA_ "SigType" SG_ 2365463038 AuxValve9FailSafeMode 4;
BA_ "SPN" SG_ 2365463038 AuxValve9State 2267;
BA_ "SPN" SG_ 2365463038 AuxValve9RetractPortEstFlow 2266;
BA_ "SPN" SG_ 2365463038 AuxValve9ExtendPortEstFlow 2265;
BA_ "SPN" SG_ 2365462782 AuxValve8Exit_reasonCode 5808;
BA_ "SPN" SG_ 2365462782 AuxValve8FailSafeMode 2262;
BA_ "SigType" SG_ 2365462782 AuxValve8FailSafeMode 4;
BA_ "SPN" SG_ 2365462782 AuxValve8State 1999;
BA_ "SPN" SG_ 2365462782 AuxValve8RetractPortEstFlow 1998;
BA_ "SPN" SG_ 2365462782 AuxValve8ExtendPortEstFlow 1997;
BA_ "SPN" SG_ 2365462526 AuxValve7Exit_reasonCode 5807;
BA_ "SPN" SG_ 2365462526 AuxValve7FailSafeMode 1994;
BA_ "SigType" SG_ 2365462526 AuxValve7FailSafeMode 4;
BA_ "SPN" SG_ 2365462526 AuxValve7State 1987;
BA_ "SPN" SG_ 2365462526 AuxValve7RetractPortEstFlow 1986;
BA_ "SPN" SG_ 2365462526 AuxValve7ExtendPortEstFlow 1985;
BA_ "SPN" SG_ 2365462270 AuxValve6Exit_reasonCode 5806;
BA_ "SPN" SG_ 2365462270 AuxValve6FailSafeMode 1982;
BA_ "SigType" SG_ 2365462270 AuxValve6FailSafeMode 4;
BA_ "SPN" SG_ 2365462270 AuxValve6State 1975;
BA_ "SPN" SG_ 2365462270 AuxValve6RetractPortEstFlow 1974;
BA_ "SPN" SG_ 2365462270 AuxValve6ExtendPortEstFlow 1973;
BA_ "SPN" SG_ 2365462014 AuxValve5Exit_reasonCode 5805;
BA_ "SPN" SG_ 2365462014 AuxValve5FailSafeMode 1970;
BA_ "SigType" SG_ 2365462014 AuxValve5FailSafeMode 4;
BA_ "SPN" SG_ 2365462014 AuxValve5State 1963;
BA_ "SPN" SG_ 2365462014 AuxValve5RetractPortEstFlow 1962;
BA_ "SPN" SG_ 2365462014 AuxValve5ExtendPortEstFlow 1961;
BA_ "SPN" SG_ 2365461758 AuxValve4Exit_reasonCode 5804;
BA_ "SPN" SG_ 2365461758 AuxValve4FailSafeMode 1958;
BA_ "SigType" SG_ 2365461758 AuxValve4FailSafeMode 4;
BA_ "SPN" SG_ 2365461758 AuxValve4State 1951;
BA_ "SPN" SG_ 2365461758 AuxValve4RetractPortEstFlow 1950;
BA_ "SPN" SG_ 2365461758 AuxValve4ExtendPortEstFlow 1949;
BA_ "SPN" SG_ 2365461502 AuxValve3Exit_reasonCode 5803;
BA_ "SPN" SG_ 2365461502 AuxValve3FailSafeMode 1946;
BA_ "SigType" SG_ 2365461502 AuxValve3FailSafeMode 4;
BA_ "SPN" SG_ 2365461502 AuxValve3State 1939;
BA_ "SPN" SG_ 2365461502 AuxValve3RetractPortEstFlow 1938;
BA_ "SPN" SG_ 2365461502 AuxValve3ExtendPortEstFlow 1937;
BA_ "SPN" SG_ 2365461246 AuxValve2Exit_reasonCode 5802;
BA_ "SPN" SG_ 2365461246 AuxValve2FailSafeMode 1934;
BA_ "SigType" SG_ 2365461246 AuxValve2FailSafeMode 4;
BA_ "SPN" SG_ 2365461246 AuxValve2State 1927;
BA_ "SPN" SG_ 2365461246 AuxValve2RetractPortEstFlow 1926;
BA_ "SPN" SG_ 2365461246 AuxValve2ExtendPortEstFlow 1925;
BA_ "SPN" SG_ 2365460990 AuxValve1Exit_reasonCode 5801;
BA_ "SPN" SG_ 2365460990 AuxValve1FailSafeMode 1922;
BA_ "SigType" SG_ 2365460990 AuxValve1FailSafeMode 4;
BA_ "SPN" SG_ 2365460990 AuxValve1State 1915;
BA_ "SPN" SG_ 2365460990 AuxValve1RetractPortEstFlow 1914;
BA_ "SPN" SG_ 2365460990 AuxValve1ExtendPortEstFlow 1913;
BA_ "SPN" SG_ 2365460734 AuxValve0Exit_reasonCode 5800;
BA_ "SPN" SG_ 2365460734 AuxValve0FailSafeMode 1910;
BA_ "SigType" SG_ 2365460734 AuxValve0FailSafeMode 4;
BA_ "SPN" SG_ 2365460734 AuxValve0State 1903;
BA_ "SPN" SG_ 2365460734 AuxValve0RetractPortEstFlow 1902;
BA_ "SPN" SG_ 2365460734 AuxValve0ExtendPortEstFlow 1901;
BA_ "SPN" SG_ 2365460478 DistanceUnitCmd 2414;
BA_ "SigType" SG_ 2365460478 DistanceUnitCmd 4;
BA_ "SPN" SG_ 2365460478 AreaUnitCmd 2415;
BA_ "SigType" SG_ 2365460478 AreaUnitCmd 4;
BA_ "SPN" SG_ 2365460478 VolumeUnitCmd 2416;
BA_ "SigType" SG_ 2365460478 VolumeUnitCmd 4;
BA_ "SPN" SG_ 2365460478 MassUnitCmd 2417;
BA_ "SigType" SG_ 2365460478 MassUnitCmd 4;
BA_ "SPN" SG_ 2365460478 DateCmd 2412;
BA_ "SPN" SG_ 2365460478 DecimalSymbolCmd 2411;
BA_ "SigType" SG_ 2365460478 DecimalSymbolCmd 4;
BA_ "SPN" SG_ 2365460478 TimeCmd 2413;
BA_ "SigType" SG_ 2365460478 TimeCmd 4;
BA_ "SPN" SG_ 2365460478 LanguageCodeCmd 2410;
BA_ "SPN" SG_ 2365460222 DataDictionaryRow 2427;
BA_ "SPN" SG_ 2365460222 DataDictionaryColumn 2428;
BA_ "SPN" SG_ 2365460222 ImplementType 2425;
BA_ "SPN" SG_ 2365460222 ImplementPos 2426;
BA_ "SPN" SG_ 2365460222 DataFormat_ErrorCondition 2419;
BA_ "SigType" SG_ 2365460222 DataFormat_ErrorCondition 4;
BA_ "SPN" SG_ 2365460222 ProcessDataType 2420;
BA_ "SigType" SG_ 2365460222 ProcessDataType 4;
BA_ "SPN" SG_ 2365460222 ProcessDataModifier 2421;
BA_ "SPN" SG_ 2365460222 RepetitionRateParameter 2418;
BA_ "SPN" SG_ 2365458942 TrctrFcltyRspLmt_RqstSttsRprting 7444;
BA_ "SPN" SG_ 2365458686 TrctrFcltyRqLmt_RqstSttsRporting 7445;
BA_ "SigType" SG_ 2365444094 NumberOfMembers 3;
BA_ "SPN" SG_ 2365443838 NAMEOfWorkingSetMember 2845;
BA_ "SPN" SG_ 2365434878 PGNOfConfigurableMessageDesired 3330;
BA_ "SPN" SG_ 2365434878 MessageSelectionCtrl 3329;
BA_ "SigType" SG_ 2365434878 MessageSelectionCtrl 1;
BA_ "SPN" SG_ 2566754814 AutomaticTransferSwitchStatus 3547;
BA_ "SPN" SG_ 2566754814 UtilityCircuitBreakerStatus 3546;
BA_ "SPN" SG_ 2566754814 GeneratorCircuitBreakerStatus 3545;
BA_ "SPN" SG_ 2566754302 GeneratorTotalPercentKVAr 3592;
BA_ "SigType" SG_ 2566754302 GeneratorTotalPercentKVAr 1;
BA_ "SPN" SG_ 2566754302 GeneratorTotalPercentKVA 3591;
BA_ "SigType" SG_ 2566754302 GeneratorTotalPercentKVA 1;
BA_ "SPN" SG_ 2566754302 GeneratorTotalPercentKW 3590;
BA_ "SigType" SG_ 2566754302 GeneratorTotalPercentKW 1;
BA_ "SPN" SG_ 2566754046 GeneratorTotalKVArHoursImport 3594;
BA_ "SigType" SG_ 2566754046 GeneratorTotalKVArHoursImport 1;
BA_ "SPN" SG_ 2566754046 GeneratorTotalKVArHoursExport 3593;
BA_ "SigType" SG_ 2566754046 GeneratorTotalKVArHoursExport 1;
BA_ "SPN" SG_ 2566753790 UtilityTotalKVArHoursImport 3596;
BA_ "SigType" SG_ 2566753790 UtilityTotalKVArHoursImport 1;
BA_ "SPN" SG_ 2566753790 UtilityTotalKVArHoursExport 3595;
BA_ "SigType" SG_ 2566753790 UtilityTotalKVArHoursExport 1;
BA_ "SPN" SG_ 2365408254 MachineSelectedDirectionCmd 4312;
BA_ "SigType" SG_ 2365408254 MachineSelectedDirectionCmd 4;
BA_ "SPN" SG_ 2365408254 MchnSelectedSpeedExit_reasonCode 5818;
BA_ "SPN" SG_ 2365408254 MchineSelectedSpeedSetpointLimit 4311;
BA_ "SPN" SG_ 2365408254 MachineSelectedSpeedSetpointCmd 4310;
BA_ "SPN" SG_ 2365407998 ISOBUSCmplncCrtfctnMssgeRevision 7446;
BA_ "SPN" SG_ 2365407998 ISOBUSCmplncCrtfctnRfrenceNumber 4330;
BA_ "SPN" SG_ 2365407998 ISOBUSCmplncCrtfctonTypeTaskCtrl 4325;
BA_ "SPN" SG_ 2365407998 ISOBUSCmplncCrtfctnTypTCWrkn4326 4326;
BA_ "SPN" SG_ 2365407998 ISOBUSCmplncCrtfctnTypTCWrkngStM 4327;
BA_ "SPN" SG_ 2365407998 ISOBUSCmplncCrtfctnTypFileServer 4328;
BA_ "SPN" SG_ 2365407998 ISOBUSCmplncCrtfctnTypGPSRceiver 4329;
BA_ "SPN" SG_ 2365407998 ISOBUSCmplncCrtfcationTypeMinECU 4317;
BA_ "SPN" SG_ 2365407998 ISOBUSCmplncCrtfctnTypTECUClass1 4318;
BA_ "SPN" SG_ 2365407998 ISOBUSCmplncCrtfctnTypTECUClass2 4319;
BA_ "SPN" SG_ 2365407998 ISOBUSCmplncCrtfctnTypTECUClass3 4320;
BA_ "SPN" SG_ 2365407998 ISOBUSCmplncCrtfctnTypeClass3ECU 4321;
BA_ "SPN" SG_ 2365407998 ISOBUSCmplncCrtfctnTypVrtlTrmnal 4322;
BA_ "SPN" SG_ 2365407998 ISOBUSCmplncCrtfctnTypVTWrkn4323 4323;
BA_ "SPN" SG_ 2365407998 ISOBUSCmplncCrtfctnTypVTWrkngStM 4324;
BA_ "SPN" SG_ 2365407998 ISOBUSCmplncCrtfctonLaboratoryID 4316;
BA_ "SPN" SG_ 2365407998 ISOBUSCmplncCrtfctLaboratoryType 4315;
BA_ "SPN" SG_ 2365407998 ISOBUSCmplnceCertificateRevision 4314;
BA_ "SPN" SG_ 2365407998 ISOBUSCmplianceCertificationYear 4313;
BA_ "SPN" SG_ 2365391870 ImplementOperatingStateCmd 5139;
BA_ "SigType" SG_ 2365391870 ImplementOperatingStateCmd 4;
VAL_ 2364593150 PrdctvCrsCtrlDrvlnDsnggInhibitRq 3 "Don't care/take no action" 2 "Reserved" 1 "Driveline Disengage Inhibit Request" 0 "No Inhibit Request" ;
VAL_ 2364593150 VhclSpdCtrlOvrrideEventIndicator 3 "Not available" 2 "Reserved" 1 "Speed Control event is active" 0 "Speed Control event is not active" ;
VAL_ 2364593150 PrdctvCrsCtrlSpeedEventIndicator 3 "Not available" 2 "Decreased speed event is active" 1 "Increased speed event is active" 0 "No speed event is active" ;
VAL_ 2364593150 PredictiveCruiseCtrlEventInRange 3 "Not available" 2 "Error" 1 "PCC event in range" 0 "No PCC event in range" ;
VAL_ 2364593150 VehicleSpeedCtrlOverrideRq 3 "Don't care/take no action" 2 "Reserved" 1 "Speed control override requested" 0 "No speed control override requested" ;
VAL_ 2364593150 PredictiveCruiseCtrlState 15 "Not Available" 14 "Error" 8 "Enabled, but not functional due to self test" 7 "Enabled, but not functional due to inhibited by driver" 6 "Enabled, but not functional due to vehicle speed below speed threshold" 5 "Enabled, but not functional due to predicted path not available" 4 "Enabled, but not functional due to road grade info not available" 3 "Enabled, but not functional due to map position not available" 2 "Enabled, but not functional due to vehicle position not available" 1 "Enabled" 0 "Disabled" ;
VAL_ 2364592638 EngCylHdBypssActtr1OprtionStatus 15 "Not available" 14 "Error" 6 "Calibration in Progress (must be broadcast at least once per calibration process defined in SPN 3464)" 5 "Uncontrolled Shutdown Active (no torque is being applied from the actuator)" 4 "Controlled Shutdown Active (driving to the default position - usually this means closed)" 3 "Derate Active (torque output reduced due to environmental conditions)" 2 "Alarm High Severity (functional but transient performance may be reduced)" 1 "Alarm (fully operational but needs service)" 0 "Normal" ;
VAL_ 2364592638 EngCylHdBypssActuator1TempStatus 7 "Not available" 6 "Error" 5 "Not Defined" 4 "Low Most severe" 3 "Low Least severe" 2 "In Range" 1 "High Least severe" 0 "High Most severe" ;
VAL_ 2364592382 EngCyl24ExcludeFromCombustionRq 3 "Not available/Do not care" 2 "Reserved" 1 "Include for Combustion" 0 "Exclude from Combustion" ;
VAL_ 2364592382 EngCyl23ExcludeFromCombustionRq 3 "Not available/Do not care" 2 "Reserved" 1 "Include for Combustion" 0 "Exclude from Combustion" ;
VAL_ 2364592382 EngCyl22ExcludeFromCombustionRq 3 "Not available/Do not care" 2 "Reserved" 1 "Include for Combustion" 0 "Exclude from Combustion" ;
VAL_ 2364592382 EngCyl21ExcludeFromCombustionRq 3 "Not available/Do not care" 2 "Reserved" 1 "Include for Combustion" 0 "Exclude from Combustion" ;
VAL_ 2364592382 EngCyl20ExcludeFromCombustionRq 3 "Not available/Do not care" 2 "Reserved" 1 "Include for Combustion" 0 "Exclude from Combustion" ;
VAL_ 2364592382 EngCyl19ExcludeFromCombustionRq 3 "Not available/Do not care" 2 "Reserved" 1 "Include for Combustion" 0 "Exclude from Combustion" ;
VAL_ 2364592382 EngCyl18ExcludeFromCombustionRq 3 "Not available/Do not care" 2 "Reserved" 1 "Include for Combustion" 0 "Exclude from Combustion" ;
VAL_ 2364592382 EngCyl17ExcludeFromCombustionRq 3 "Not available/Do not care" 2 "Reserved" 1 "Include for Combustion" 0 "Exclude from Combustion" ;
VAL_ 2364592382 EngCyl16ExcludeFromCombustionRq 3 "Not available/Do not care" 2 "Reserved" 1 "Include for Combustion" 0 "Exclude from Combustion" ;
VAL_ 2364592382 EngCyl15ExcludeFromCombustionRq 3 "Not available/Do not care" 2 "Reserved" 1 "Include for Combustion" 0 "Exclude from Combustion" ;
VAL_ 2364592382 EngCyl14ExcludeFromCombustionRq 3 "Not available/Do not care" 2 "Reserved" 1 "Include for Combustion" 0 "Exclude from Combustion" ;
VAL_ 2364592382 EngCyl13ExcludeFromCombustionRq 3 "Not available/Do not care" 2 "Reserved" 1 "Include for Combustion" 0 "Exclude from Combustion" ;
VAL_ 2364592382 EngCyl12ExcludeFromCombustionRq 3 "Not available/Do not care" 2 "Reserved" 1 "Include for Combustion" 0 "Exclude from Combustion" ;
VAL_ 2364592382 EngCyl11ExcludeFromCombustionRq 3 "Not available/Do not care" 2 "Reserved" 1 "Include for Combustion" 0 "Exclude from Combustion" ;
VAL_ 2364592382 EngCyl10ExcludeFromCombustionRq 3 "Not available/Do not care" 2 "Reserved" 1 "Include for Combustion" 0 "Exclude from Combustion" ;
VAL_ 2364592382 EngCyl9ExcludeFromCombustionRq 3 "Not available/Do not care" 2 "Reserved" 1 "Include for Combustion" 0 "Exclude from Combustion" ;
VAL_ 2364592382 EngCyl8ExcludeFromCombustionRq 3 "Not available/Do not care" 2 "Reserved" 1 "Include for Combustion" 0 "Exclude from Combustion" ;
VAL_ 2364592382 EngCyl7ExcludeFromCombustionRq 3 "Not available/Do not care" 2 "Reserved" 1 "Include for Combustion" 0 "Exclude from Combustion" ;
VAL_ 2364592382 EngCyl6ExcludeFromCombustionRq 3 "Not available/Do not care" 2 "Reserved" 1 "Include for Combustion" 0 "Exclude from Combustion" ;
VAL_ 2364592382 EngCyl5ExcludeFromCombustionRq 3 "Not available/Do not care" 2 "Reserved" 1 "Include for Combustion" 0 "Exclude from Combustion" ;
VAL_ 2364592382 EngCyl4ExcludeFromCombustionRq 3 "Not available/Do not care" 2 "Reserved" 1 "Include for Combustion" 0 "Exclude from Combustion" ;
VAL_ 2364592382 EngCyl3ExcludeFromCombustionRq 3 "Not available/Do not care" 2 "Reserved" 1 "Include for Combustion" 0 "Exclude from Combustion" ;
VAL_ 2364592382 EngCyl2ExcludeFromCombustionRq 3 "Not available/Do not care" 2 "Reserved" 1 "Include for Combustion" 0 "Exclude from Combustion" ;
VAL_ 2364592382 EngCyl1ExcludeFromCombustionRq 3 "Not available/Do not care" 2 "Reserved" 1 "Include for Combustion" 0 "Exclude from Combustion" ;
VAL_ 2558918398 PrdctiveCruiseCtrlDeactivationRq 3 "Not available" 2 "Error" 1 "Predictive cruise control is requested to be deactived" 0 "Predictive cruise control is not requested to be deactived" ;
VAL_ 2558918398 PredictiveCruiseCtrlEnableSwitch 3 "Not available" 2 "Error" 1 "Predictive cruise control is enabled" 0 "Predictive cruise control is not enabled" ;
VAL_ 2558918398 HtExchngerDebrisPurgeForceSwitch 3 "not available" 2 "error" 1 "active" 0 "not active" ;
VAL_ 2558918398 HtExchngrDbrisPurgeInhibitSwitch 3 "not available" 2 "error" 1 "active" 0 "not active" ;
VAL_ 2558918398 SCROprtrInducementOverrideSwitch 3 "Not available" 2 "Error" 1 "On" 0 "Off" ;
VAL_ 2558852862 AT1ParticulateSensorDewpoint 3 "Not available" 2 "SAE reserved" 1 "Dewpoint has been reached" 0 "Dewpoint has not been reached" ;
VAL_ 2558852862 AT1PrtculateSensorRegenerationRq 3 "Not available" 2 "SAE reserved" 1 "Regeneration requested" 0 "Regeneration not requested" ;
VAL_ 2558852862 AT1ParticulateSensorShutdownRq 3 "Not available" 2 "SAE reserved" 1 "Shutdown request active" 0 "Shutdown request not active" ;
VAL_ 2558787326 PayloadCalibSetPointCmd 15 "Not Available" 14 "Error" 13 "Reserved" 12 "Reset Calibration" 11 "Correction Point" 10 "End Point" 9 "Calibration Reference Point 9" 8 "Calibration Reference Point 8" 7 "Calibration Reference Point 7" 6 "Calibration Reference Point 6" 5 "Calibration Reference Point 5" 4 "Calibration Reference Point 4" 3 "Calibration Reference Point 3" 2 "Calibration Reference Point 2" 1 "Calibration Reference Point 1" 0 "Zero Point" ;
VAL_ 2558656254 RqToPermitDEFDosingTestInjection 7 "don't care" 2 "urgent request to permit DEF Dosing Test Injection or test injection is running" 1 "request to permit DEF Dosing Test Injection or test injection is running" 0 "no request" ;
VAL_ 2558656254 RqToPermitDEFHydStiffnessCheck 3 "don't care" 2 "reserved" 1 "request to permit DEF hydraulic stiffness check or stiffness check is running" 0 "no request" ;
VAL_ 2558656254 ATThermalManagementInhibitRq 3 "Not Available" 2 "Reserved for SAE assignment" 1 "Inhibit" 0 "Do not inhibit" ;
VAL_ 2558590718 HybrdSystmRgnrtvBrakingDisableRq 3 "Don't care / take no action" 2 "Reserved" 1 "Regenerative braking disable request is active.  Regenerative braking is not allowed." 0 "Regenerative braking disable request is not active.  Regenerative braking is allowed." ;
VAL_ 2558590718 HybridSystemProtectionOverrideRq 3 "Don't care / take no action" 2 "Reserved" 1 "Active" 0 "Not active" ;
VAL_ 2350710526 TransOverrideCtrlModePriority 3 "Low priority" 2 "Medium priority" 1 "High priority" 0 "Highest priority" ;
VAL_ 2350710526 TransOverrideCtrlMode 3 "Speed/torque limit control - Limit speed and/or torque based on the included limit values." 2 "Torque control - Control torque to the included “desired torque” value." 1 "Speed control - Control speed to the included “desired speed” value." 0 "Override disabled - Disable any existing control commanded by the source of this command." ;
VAL_ 2365475326 GroundBasedDirection 3 "Not available" 2 "Error indication" 1 "Forward" 0 "Reverse" ;
VAL_ 2365475070 KeySwitchNOTOFF 3 "Not available" 2 "Error indication" 1 "Key Switch Not Off" 0 "Key Switch Off" ;
VAL_ 2365475070 WheelBasedDirection 3 "Not available" 2 "Error indication" 1 "Forward" 0 "Reverse" ;
VAL_ 2365474814 ImplementInWorkState 3 "Not available" 2 "Error indication" 1 "Implement is “in-work”" 0 "Implement is “out of work”" ;
VAL_ 2365474814 ImplementTransportState 3 "Not available" 2 "Error indication" 1 "Implement may be transported" 0 "Implement may Not be transported " ;
VAL_ 2365474814 ImplementParkState 3 "Not available" 2 "Error indication" 1 "Implement may be disconnected" 0 "Implement may Not be disconnected " ;
VAL_ 2365474814 ImplementWorkState 3 "Not available" 2 "Error indication" 1 "Implement is ready for field work" 0 "Implement is Not ready for field work " ;
VAL_ 2365474814 MaintainECUPower 3 "Don’t Care" 2 "Reserved " 1 "Requirement for 2 more seconds of ECU_PWR" 0 "No Further Requirement for ECU_PWR" ;
VAL_ 2365474814 MaintainAcuatorPower 3 "Don’t Care" 2 "Reserved " 1 "Requirement for 2 more seconds of PWR" 0 "No Further Requirement for PWR" ;
VAL_ 2365474558 FrontHitchInworkIndication 3 "Not available" 2 "Error indication" 1 "Hitch position is in-work" 0 "Hitch position is out-of-work " ;
VAL_ 2365474302 RearHitchInworkIndication 3 "Not available" 2 "Error indication" 1 "Hitch position is in-work" 0 "Hitch position is out-of-work " ;
VAL_ 2365474046 FrontPowerTakeOffEngagement 3 "Not available" 2 "Error indication" 1 "Power take off engaged" 0 "Power take off disengaged" ;
VAL_ 2365474046 FrontPowerTakeOffMode 3 "Not available" 2 "Error indication" 1 "Power take off mode is 1000" 0 "Power take off mode is 540" ;
VAL_ 2365474046 FrontPowerTakeOffEconomyMode 3 "Not available" 2 "Error indication" 1 "Power take off economy mode is engaged" 0 "Power take off economy mode is disengaged" ;
VAL_ 2365473790 RearPowerTakeOffEngagement 3 "Not available" 2 "Error indication" 1 "Power take off engaged" 0 "Power take off disengaged" ;
VAL_ 2365473790 RearPowerTakeOffMode 3 "Not available" 2 "Error indication" 1 "Power take off mode is 1000" 0 "Power take off mode is 540" ;
VAL_ 2365473790 RearPowerTakeOffEconomyMode 3 "Not available" 2 "Error indication" 1 "Power take off economy mode is engaged" 0 "Power take off economy mode is disengaged" ;
VAL_ 2365473534 FrontPowerTakeOffModeCmd 3 "Don’t Care" 2 "Reserved" 1 "Select 1000 rpm mode " 0 "Select 540 rpm mode" ;
VAL_ 2365473534 RearPowerTakeOffModeCmd 3 "Don’t Care" 2 "Reserved" 1 "Select 1000 rpm mode " 0 "Select 540 rpm mode" ;
VAL_ 2365473534 FrontPowerTakeOffEconomyModeCmd 3 "Don’t Care" 2 "Reserved" 1 "Engage Power take off‘s economy mode" 0 "Disengage Power take off‘s economy mode" ;
VAL_ 2365473534 RearPowerTakeOffEconomyModeCmd 3 "Don’t Care" 2 "Reserved" 1 "Engage Power take off‘s economy mode" 0 "Disengage Power take off‘s economy mode" ;
VAL_ 2365473534 FrontPowerTakeOffEngagementCmd 3 "Don’t Care" 2 "Reserved" 1 "Engage Power take off " 0 "Disengage Power take off" ;
VAL_ 2365473534 RearPowerTakeOffEngagementCmd 3 "Don’t Care" 2 "Reserved" 1 "Engage Power take off " 0 "Disengage Power take off" ;
VAL_ 2365472766 AuxValve15FailSafeModeCmd 3 "Don’t Care" 2 "Reserved" 1 "Float" 0 "Block" ;
VAL_ 2365472766 AuxValve15StateCmd 15 "Don’t Care" 3 "Float" 2 "Retract" 1 "Extend" 0 "Block" ;
VAL_ 2365472510 AuxValve14FailSafeModeCmd 3 "Don’t Care" 2 "Reserved" 1 "Float" 0 "Block" ;
VAL_ 2365472510 AuxValve14StateCmd 15 "Don’t Care" 3 "Float" 2 "Retract" 1 "Extend" 0 "Block" ;
VAL_ 2365472254 AuxValve13FailSafeModeCmd 3 "Don’t Care" 2 "Reserved" 1 "Float" 0 "Block" ;
VAL_ 2365472254 AuxValve13StateCmd 15 "Don’t Care" 3 "Float" 2 "Retract" 1 "Extend" 0 "Block" ;
VAL_ 2365471998 AuxValve12FailSafeModeCmd 3 "Don’t Care" 2 "Reserved" 1 "Float" 0 "Block" ;
VAL_ 2365471998 AuxValve12StateCmd 15 "Don’t Care" 3 "Float" 2 "Retract" 1 "Extend" 0 "Block" ;
VAL_ 2365471742 AuxValve11FailSafeModeCmd 3 "Don’t Care" 2 "Reserved" 1 "Float" 0 "Block" ;
VAL_ 2365471742 AuxValve11StateCmd 15 "Don’t Care" 3 "Float" 2 "Retract" 1 "Extend" 0 "Block" ;
VAL_ 2365471486 AuxValve10FailSafeModeCmd 3 "Don’t Care" 2 "Reserved" 1 "Float" 0 "Block" ;
VAL_ 2365471486 AuxValve10StateCmd 15 "Don’t Care" 3 "Float" 2 "Retract" 1 "Extend" 0 "Block" ;
VAL_ 2365471230 AuxValve9FailSafeModeCmd 3 "Don’t Care" 2 "Reserved" 1 "Float" 0 "Block" ;
VAL_ 2365471230 AuxValve9StateCmd 15 "Don’t Care" 3 "Float" 2 "Retract" 1 "Extend" 0 "Block" ;
VAL_ 2365470974 AuxValve8FailSafeModeCmd 3 "Don’t Care" 2 "Reserved" 1 "Float" 0 "Block" ;
VAL_ 2365470974 AuxValve8StateCmd 15 "Don’t Care" 3 "Float" 2 "Retract" 1 "Extend" 0 "Block" ;
VAL_ 2365470718 AuxValve7FailSafeModeCmd 3 "Don’t Care" 2 "Reserved" 1 "Float" 0 "Block" ;
VAL_ 2365470718 AuxValve7StateCmd 15 "Don’t Care" 3 "Float" 2 "Retract" 1 "Extend" 0 "Block" ;
VAL_ 2365470462 AuxValve6FailSafeModeCmd 3 "Don’t Care" 2 "Reserved" 1 "Float" 0 "Block" ;
VAL_ 2365470462 AuxValve6StateCmd 15 "Don’t Care" 3 "Float" 2 "Retract" 1 "Extend" 0 "Block" ;
VAL_ 2365470206 AuxValve5FailSafeModeCmd 3 "Don’t Care" 2 "Reserved" 1 "Float" 0 "Block" ;
VAL_ 2365470206 AuxValve5StateCmd 15 "Don’t Care" 3 "Float" 2 "Retract" 1 "Extend" 0 "Block" ;
VAL_ 2365469950 AuxValve4FailSafeModeCmd 3 "Don’t Care" 2 "Reserved" 1 "Float" 0 "Block" ;
VAL_ 2365469950 AuxValve4StateCmd 15 "Don’t Care" 3 "Float" 2 "Retract" 1 "Extend" 0 "Block" ;
VAL_ 2365469694 AuxValve3FailSafeModeCmd 3 "Don’t Care" 2 "Reserved" 1 "Float" 0 "Block" ;
VAL_ 2365469694 AuxValve3StateCmd 15 "Don’t Care" 3 "Float" 2 "Retract" 1 "Extend" 0 "Block" ;
VAL_ 2365469438 AuxValve2FailSafeModeCmd 3 "Don’t Care" 2 "Reserved" 1 "Float" 0 "Block" ;
VAL_ 2365469438 AuxValve2StateCmd 15 "Don’t Care" 3 "Float" 2 "Retract" 1 "Extend" 0 "Block" ;
VAL_ 2365469182 AuxValve1FailSafeModeCmd 3 "Don’t Care" 2 "Reserved" 1 "Float" 0 "Block" ;
VAL_ 2365469182 AuxValve1StateCmd 15 "Don’t Care" 3 "Float" 2 "Retract" 1 "Extend" 0 "Block" ;
VAL_ 2365468926 AuxValve0FailSafeModeCmd 3 "Don’t Care" 2 "Reserved" 1 "Float" 0 "Block" ;
VAL_ 2365468926 AuxValve0StateCmd 15 "Don’t Care" 3 "Float" 2 "Retract" 1 "Extend" 0 "Block" ;
VAL_ 2365464574 AuxValve15FailSafeMode 3 "Not available" 2 "Error" 1 "Float" 0 "Block" ;
VAL_ 2365464574 AuxValve15State 15 "Don’t Care" 3 "Floating" 2 "Retract" 1 "Extend" 0 "Blocked" ;
VAL_ 2365464318 AuxValve14FailSafeMode 3 "Not available" 2 "Error indication" 1 "Float" 0 "Block" ;
VAL_ 2365464318 AuxValve14State 15 "Don’t Care" 3 "Floating" 2 "Retract" 1 "Extend" 0 "Blocked" ;
VAL_ 2365464062 AuxValve13FailSafeMode 3 "Not available" 2 "Error indication" 1 "Float" 0 "Block" ;
VAL_ 2365464062 AuxValve13State 15 "Don’t Care" 3 "Floating" 2 "Retract" 1 "Extend" 0 "Blocked" ;
VAL_ 2365463806 AuxValve12FailSafeMode 3 "Not available" 2 "Error indication" 1 "Float" 0 "Block" ;
VAL_ 2365463806 AuxValve12State 15 "Don’t Care" 3 "Floating" 2 "Retract" 1 "Extend" 0 "Blocked" ;
VAL_ 2365463550 AuxValve11FailSafeMode 3 "Not available" 2 "Error indication" 1 "Float" 0 "Block" ;
VAL_ 2365463550 AuxValve11State 15 "Don’t Care" 3 "Floating" 2 "Retract" 1 "Extend" 0 "Blocked" ;
VAL_ 2365463294 AuxValve10FailSafeMode 3 "Not available" 2 "Error indication" 1 "Float" 0 "Block" ;
VAL_ 2365463294 AuxValve10State 15 "Don’t Care" 3 "Floating" 2 "Retract" 1 "Extend" 0 "Blocked" ;
VAL_ 2365463038 AuxValve9FailSafeMode 3 "Not available" 2 "Error indication" 1 "Float" 0 "Block" ;
VAL_ 2365463038 AuxValve9State 15 "Don’t Care" 3 "Floating" 2 "Retract" 1 "Extend" 0 "Blocked" ;
VAL_ 2365462782 AuxValve8FailSafeMode 3 "Not available" 2 "Error indication" 1 "Float" 0 "Block" ;
VAL_ 2365462782 AuxValve8State 15 "Don’t Care" 3 "Floating" 2 "Retract" 1 "Extend" 0 "Blocked" ;
VAL_ 2365462526 AuxValve7FailSafeMode 3 "Not available" 2 "Error indication" 1 "Float" 0 "Block" ;
VAL_ 2365462526 AuxValve7State 15 "Don’t Care" 3 "Floating" 2 "Retract" 1 "Extend" 0 "Blocked" ;
VAL_ 2365462270 AuxValve6FailSafeMode 3 "Not available" 2 "Error indication" 1 "Float" 0 "Block" ;
VAL_ 2365462270 AuxValve6State 15 "Don’t Care" 3 "Floating" 2 "Retract" 1 "Extend" 0 "Blocked" ;
VAL_ 2365462014 AuxValve5FailSafeMode 3 "Not available" 2 "Error indication" 1 "Float" 0 "Block" ;
VAL_ 2365462014 AuxValve5State 15 "Don’t Care" 3 "Floating" 2 "Retract" 1 "Extend" 0 "Blocked" ;
VAL_ 2365461758 AuxValve4FailSafeMode 3 "Not available" 2 "Error indication" 1 "Float" 0 "Block" ;
VAL_ 2365461758 AuxValve4State 15 "Don’t Care" 3 "Floating" 2 "Retract" 1 "Extend" 0 "Blocked" ;
VAL_ 2365461502 AuxValve3FailSafeMode 3 "Not available" 2 "Error indication" 1 "Float" 0 "Block" ;
VAL_ 2365461502 AuxValve3State 15 "Don’t Care" 3 "Floating" 2 "Retract" 1 "Extend" 0 "Blocked" ;
VAL_ 2365461246 AuxValve2FailSafeMode 3 "Not available" 2 "Error indication" 1 "Float" 0 "Block" ;
VAL_ 2365461246 AuxValve2State 15 "Don’t Care" 3 "Floating" 2 "Retract" 1 "Extend" 0 "Blocked" ;
VAL_ 2365460990 AuxValve1FailSafeMode 3 "Not available" 2 "Error indication" 1 "Float" 0 "Block" ;
VAL_ 2365460990 AuxValve1State 15 "Don’t Care" 3 "Floating" 2 "Retract" 1 "Extend" 0 "Blocked" ;
VAL_ 2365460734 AuxValve0FailSafeMode 3 "Not available" 2 "Error indication" 1 "Float" 0 "Block" ;
VAL_ 2365460734 AuxValve0State 15 "Don’t Care" 3 "Floating" 2 "Retract" 1 "Extend" 0 "Blocked" ;
VAL_ 2365460478 DistanceUnitCmd 3 "No action" 2 "Reserved" 1 "Imperial (miles, feet, ..)" 0 "Metric (km, m, …)" ;
VAL_ 2365460478 AreaUnitCmd 3 "No action" 2 "Reserved" 1 "Imperial (acres or feet2)" 0 "Metric (ha or m2)" ;
VAL_ 2365460478 VolumeUnitCmd 3 "No action" 2 "US (gallon)" 1 "Imperial (gallon)" 0 "Metric (litre)" ;
VAL_ 2365460478 MassUnitCmd 3 "No action" 2 "Tons/pounds (short tons-US, pounds, …)" 1 "Imperial (long tons-UK, pounds, ….)" 0 "Metric (tonne, kg, …)" ;
VAL_ 2365460478 DecimalSymbolCmd 3 "No action" 2 "Reserved" 1 "Point is used" 0 "Comma is used" ;
VAL_ 2365460478 TimeCmd 3 "No action" 2 "Reserved" 1 "12 hour (am/ pm)" 0 "24 hour" ;
VAL_ 2365460222 DataFormat_ErrorCondition 3 "Not Available or error" 2 "Data format is unsigned Long Integer" 1 "Data format is Floating" 0 "Data format is Long Integer" ;
VAL_ 2365460222 ProcessDataType 3 "Message is Actual value request" 2 "Message is Set Point request" 1 "Data is Actual values" 0 "Data is Set Point" ;
VAL_ 2365408254 MachineSelectedDirectionCmd 3 "Don't care, take no action" 2 "Reserved" 1 "Forward" 0 "Reverse" ;
VAL_ 2365407998 ISOBUSCmplncCrtfctLaboratoryType 7 "Not available (Not certified)" 2 "NA certified laboratory" 1 "EU certified laboratory" 0 "Non-certified laboratory/ self certification" ;
VAL_ 2365407998 ISOBUSCmplnceCertificateRevision 7 "Not available" 3 "Fourth Revision (Suffix C)" 2 "Third Revision (Suffix B)" 1 "Second Revision (Suffix A)" 0 "First Revision (No Suffix)" ;
VAL_ 2365391870 ImplementOperatingStateCmd 3 "Take no action" 2 "Set implement to park state" 1 "Set implement to transport state" 0 "Set implement to field working state" ;
